VERSION "dbc-export 1 2025.20.8"

NS_ :

BS_:

BU_: APP BMS CC CMP CMPD CP DAS DI DIF DIR EPBL EPBR EVSE FC GTW HCML HCMR HVP ICR PCS PM PMF PMR PTC SCCM SCM SCS SDCR TAS UMC VC VCFRONT VCLEFT VCRIGHT VCSEC

BO_ 1291 TAS_alertLog: 8 TAS
 SG_ TAS_alertID M : 0|9@1+ (1,0) [0|511] "" Vector__XXX
 SG_ TAS_alertState : 15|1@1+ (1,0) [0|1] "" Vector__XXX
 SG_ TAS_a001_InternalWatchdog m1 : 16|1@1+ (1,0) [0|1] "" Vector__XXX
 SG_ TAS_a002_CPUUndervoltage m2 : 16|1@1+ (1,0) [0|1] "" Vector__XXX
 SG_ TAS_a002_PowerOnReset m2 : 17|1@1+ (1,0) [0|1] "" Vector__XXX
 SG_ TAS_a003_AssertID m3 : 16|16@1+ (1,0) [0|65535] "" Vector__XXX
 SG_ TAS_a003_LineNumber m3 : 32|16@1+ (1,0) [0|65535] "" Vector__XXX
 SG_ TAS_a003_Data m3 : 48|16@1+ (1,0) [0|65535] "" Vector__XXX
 SG_ TAS_a012_ClockError m12 : 16|1@1+ (1,0) [0|1] "" Vector__XXX
 SG_ TAS_a012_FlashError m12 : 17|1@1+ (1,0) [0|1] "" Vector__XXX
 SG_ TAS_a012_SoftwareReset m12 : 18|1@1+ (1,0) [0|1] "" Vector__XXX
 SG_ TAS_a012_CheckstopReset m12 : 19|1@1+ (1,0) [0|1] "" Vector__XXX
 SG_ TAS_a012_DebugReset m12 : 20|1@1+ (1,0) [0|1] "" Vector__XXX
 SG_ TAS_a012_ExternalReset m12 : 21|1@1+ (1,0) [0|1] "" Vector__XXX
 SG_ TAS_a021_Task1msLate m21 : 16|1@1+ (1,0) [0|1] "" Vector__XXX
 SG_ TAS_a021_Task1msStarved m21 : 17|1@1+ (1,0) [0|1] "" Vector__XXX
 SG_ TAS_a021_Task1msMissed m21 : 18|1@1+ (1,0) [0|1] "" Vector__XXX
 SG_ TAS_a021_Task10msLate m21 : 19|1@1+ (1,0) [0|1] "" Vector__XXX
 SG_ TAS_a021_Task10msStarved m21 : 20|1@1+ (1,0) [0|1] "" Vector__XXX
 SG_ TAS_a021_Task10msMissed m21 : 21|1@1+ (1,0) [0|1] "" Vector__XXX
 SG_ TAS_a021_Task100msLate m21 : 22|1@1+ (1,0) [0|1] "" Vector__XXX
 SG_ TAS_a021_Task100msStarved m21 : 23|1@1+ (1,0) [0|1] "" Vector__XXX
 SG_ TAS_a021_Task100msMissed m21 : 24|1@1+ (1,0) [0|1] "" Vector__XXX
 SG_ TAS_a021_Task1000msLate m21 : 25|1@1+ (1,0) [0|1] "" Vector__XXX
 SG_ TAS_a021_Task1000msStarved m21 : 26|1@1+ (1,0) [0|1] "" Vector__XXX
 SG_ TAS_a021_Task1000msMissed m21 : 27|1@1+ (1,0) [0|1] "" Vector__XXX
 SG_ TAS_a022_TaskInitErrorCount m22 : 16|8@1+ (1,0) [0|255] "" Vector__XXX
 SG_ TAS_a022_TaskInitError0 m22 : 24|8@1+ (1,0) [0|255] "" Vector__XXX
 SG_ TAS_a022_TaskInitError1 m22 : 32|8@1+ (1,0) [0|255] "" Vector__XXX
 SG_ TAS_a022_TaskInitError2 m22 : 40|8@1+ (1,0) [0|255] "" Vector__XXX
 SG_ TAS_a022_TaskInitError3 m22 : 48|8@1+ (1,0) [0|255] "" Vector__XXX
 SG_ TAS_a022_TaskInitError4 m22 : 56|8@1+ (1,0) [0|255] "" Vector__XXX
 SG_ TAS_a025_vehicleLockAtCrash m25 : 16|1@1+ (1,0) [0|1] "" Vector__XXX
 SG_ TAS_a025_CANCrashIsActive m25 : 17|1@1+ (1,0) [0|1] "" Vector__XXX
 SG_ TAS_a025_appCrashIsActive m25 : 18|1@1+ (1,0) [0|1] "" Vector__XXX
 SG_ TAS_a025_lastCrashEvent m25 : 24|32@1+ (1,0) [0|4294967295] "" Vector__XXX
 SG_ TAS_a030_PWMdutyCycleFL m30 : 16|16@1+ (0.0025,0) [0|163.8375] "%" Vector__XXX
 SG_ TAS_a030_PWMfrequencyFL m30 : 32|16@1+ (0.025,0) [0|1638.375] "Hz" Vector__XXX
 SG_ TAS_a030_PWMfaultFL m30 : 48|4@1+ (1,0) [0|15] "" Vector__XXX
 SG_ TAS_a031_PWMdutyCycleFR m31 : 16|16@1+ (0.0025,0) [0|163.8375] "%" Vector__XXX
 SG_ TAS_a031_PWMfrequencyFR m31 : 32|16@1+ (0.025,0) [0|1638.375] "Hz" Vector__XXX
 SG_ TAS_a031_PWMfaultFR m31 : 48|4@1+ (1,0) [0|15] "" Vector__XXX
 SG_ TAS_a032_PWMdutyCycleRL m32 : 16|16@1+ (0.0025,0) [0|163.8375] "%" Vector__XXX
 SG_ TAS_a032_PWMfrequencyRL m32 : 32|16@1+ (0.025,0) [0|1638.375] "Hz" Vector__XXX
 SG_ TAS_a032_PWMfaultRL m32 : 48|4@1+ (1,0) [0|15] "" Vector__XXX
 SG_ TAS_a033_PWMdutyCycleRR m33 : 16|16@1+ (0.0025,0) [0|163.8375] "%" Vector__XXX
 SG_ TAS_a033_PWMfrequencyRR m33 : 32|16@1+ (0.025,0) [0|1638.375] "Hz" Vector__XXX
 SG_ TAS_a033_PWMfaultRR m33 : 48|4@1+ (1,0) [0|15] "" Vector__XXX
 SG_ TAS_a034_PWMdutyCycleFL m34 : 16|16@1+ (0.0025,0) [0|163.8375] "%" Vector__XXX
 SG_ TAS_a034_PWMfrequencyFL m34 : 32|16@1+ (0.025,0) [0|1638.375] "Hz" Vector__XXX
 SG_ TAS_a034_PWMfaultFL m34 : 48|4@1+ (1,0) [0|15] "" Vector__XXX
 SG_ TAS_a035_PWMdutyCycleFR m35 : 16|16@1+ (0.0025,0) [0|163.8375] "%" Vector__XXX
 SG_ TAS_a035_PWMfrequencyFR m35 : 32|16@1+ (0.025,0) [0|1638.375] "Hz" Vector__XXX
 SG_ TAS_a035_PWMfaultFR m35 : 48|4@1+ (1,0) [0|15] "" Vector__XXX
 SG_ TAS_a036_PWMdutyCycleRL m36 : 16|16@1+ (0.0025,0) [0|163.8375] "%" Vector__XXX
 SG_ TAS_a036_PWMfrequencyRL m36 : 32|16@1+ (0.025,0) [0|1638.375] "Hz" Vector__XXX
 SG_ TAS_a036_PWMfaultRL m36 : 48|4@1+ (1,0) [0|15] "" Vector__XXX
 SG_ TAS_a037_PWMdutyCycleRR m37 : 16|16@1+ (0.0025,0) [0|163.8375] "%" Vector__XXX
 SG_ TAS_a037_PWMfrequencyRR m37 : 32|16@1+ (0.025,0) [0|1638.375] "Hz" Vector__XXX
 SG_ TAS_a037_PWMfaultRR m37 : 48|4@1+ (1,0) [0|15] "" Vector__XXX
 SG_ TAS_a038_PWMdutyCycleFL m38 : 16|16@1+ (0.0025,0) [0|163.8375] "%" Vector__XXX
 SG_ TAS_a038_PWMfrequencyFL m38 : 32|16@1+ (0.025,0) [0|1638.375] "Hz" Vector__XXX
 SG_ TAS_a038_PWMfaultFL m38 : 48|4@1+ (1,0) [0|15] "" Vector__XXX
 SG_ TAS_a039_PWMdutyCycleFR m39 : 16|16@1+ (0.0025,0) [0|163.8375] "%" Vector__XXX
 SG_ TAS_a039_PWMfrequencyFR m39 : 32|16@1+ (0.025,0) [0|1638.375] "Hz" Vector__XXX
 SG_ TAS_a039_PWMfaultFR m39 : 48|4@1+ (1,0) [0|15] "" Vector__XXX
 SG_ TAS_a040_PWMdutyCycleRL m40 : 16|16@1+ (0.0025,0) [0|163.8375] "%" Vector__XXX
 SG_ TAS_a040_PWMfrequencyRL m40 : 32|16@1+ (0.025,0) [0|1638.375] "Hz" Vector__XXX
 SG_ TAS_a040_PWMfaultRL m40 : 48|4@1+ (1,0) [0|15] "" Vector__XXX
 SG_ TAS_a041_PWMdutyCycleRR m41 : 16|16@1+ (0.0025,0) [0|163.8375] "%" Vector__XXX
 SG_ TAS_a041_PWMfrequencyRR m41 : 32|16@1+ (0.025,0) [0|1638.375] "Hz" Vector__XXX
 SG_ TAS_a041_PWMfaultRR m41 : 48|4@1+ (1,0) [0|15] "" Vector__XXX
 SG_ TAS_a070_voltage12V m70 : 16|16@1+ (0.001,0) [0|65.535] "V" Vector__XXX
 SG_ TAS_a071_voltage12V m71 : 16|16@1+ (0.001,0) [0|65.535] "V" Vector__XXX
 SG_ TAS_a072_voltage5VOnBoard m72 : 16|16@1+ (0.001,0) [0|65.535] "V" Vector__XXX
 SG_ TAS_a073_voltage5VOnBoard m73 : 16|16@1+ (0.001,0) [0|65.535] "V" Vector__XXX
 SG_ TAS_a074_voltage5VOffBoard m74 : 16|16@1+ (0.001,0) [0|65.535] "V" Vector__XXX
 SG_ TAS_a075_voltage5VOffBoard m75 : 16|16@1+ (0.001,0) [0|65.535] "V" Vector__XXX
 SG_ TAS_a076_voltage5VOffBoard m76 : 16|16@1+ (0.001,0) [0|65.535] "V" Vector__XXX
 SG_ TAS_a077_sensorVoltage m77 : 16|16@1+ (0.001,0) [0|65.535] "V" Vector__XXX
 SG_ TAS_a077_sensorRefVoltage m77 : 32|16@1+ (0.001,0) [0|65.535] "V" Vector__XXX
 SG_ TAS_a078_sensorVoltage m78 : 16|16@1+ (0.001,0) [0|65.535] "V" Vector__XXX
 SG_ TAS_a078_sensorRefVoltage m78 : 32|16@1+ (0.001,0) [0|65.535] "V" Vector__XXX
 SG_ TAS_a080_voltage5VHeight m80 : 16|16@1+ (0.001,0) [0|65.535] "V" Vector__XXX
 SG_ TAS_a081_voltage5VHeight m81 : 16|16@1+ (0.001,0) [0|65.535] "V" Vector__XXX
 SG_ TAS_a082_voltage5VHeight m82 : 16|16@1+ (0.001,0) [0|65.535] "V" Vector__XXX
 SG_ TAS_a083_voltage5VAnalog m83 : 16|16@1+ (0.001,0) [0|65.535] "V" Vector__XXX
 SG_ TAS_a084_voltage5VAnalog m84 : 16|16@1+ (0.001,0) [0|65.535] "V" Vector__XXX
 SG_ TAS_a085_voltage5VAnalog m85 : 16|16@1+ (0.001,0) [0|65.535] "V" Vector__XXX
 SG_ TAS_a086_voltage12VSwitched m86 : 16|16@1+ (0.001,0) [0|65.535] "V" Vector__XXX
 SG_ TAS_a087_voltage12VSwitched m87 : 16|16@1+ (0.001,0) [0|65.535] "V" Vector__XXX
 SG_ TAS_a093_readError m93 : 16|1@1+ (1,0) [0|1] "" Vector__XXX
 SG_ TAS_a093_IVOR2Exception m93 : 17|1@1+ (1,0) [0|1] "" Vector__XXX
 SG_ TAS_a098_VCFRONT_LVPowerState_MI m98 : 16|1@1+ (1,0) [0|1] "" Vector__XXX
 SG_ TAS_a098_VCFRONT_sensors_MIA m98 : 17|1@1+ (1,0) [0|1] "" Vector__XXX
 SG_ TAS_a098_VCFRONT_status_MIA m98 : 18|1@1+ (1,0) [0|1] "" Vector__XXX
 SG_ TAS_a098_VCFRONT_systemStatus_MI m98 : 19|1@1+ (1,0) [0|1] "" Vector__XXX
 SG_ TAS_a098_VCFRONT_vehNm_MIA m98 : 20|1@1+ (1,0) [0|1] "" Vector__XXX
 SG_ TAS_a099_UI_chassisControl_MIA m99 : 16|1@1+ (1,0) [0|1] "" Vector__XXX
 SG_ TAS_a099_UI_driverAssistMapData_ m99 : 17|1@1+ (1,0) [0|1] "" Vector__XXX
 SG_ TAS_a099_UI_suspensionControl_MI m99 : 18|1@1+ (1,0) [0|1] "" Vector__XXX
 SG_ TAS_a099_UI_vehicleModes_MIA m99 : 19|1@1+ (1,0) [0|1] "" Vector__XXX
 SG_ TAS_a100_RCM_inertial1_MIA m100 : 16|1@1+ (1,0) [0|1] "" Vector__XXX
 SG_ TAS_a100_RCM_inertial2_MIA m100 : 17|1@1+ (1,0) [0|1] "" Vector__XXX
 SG_ TAS_a101_ESP_brakeTorque_MIA m101 : 16|1@1+ (1,0) [0|1] "" Vector__XXX
 SG_ TAS_a101_ESP_status_MIA m101 : 17|1@1+ (1,0) [0|1] "" Vector__XXX
 SG_ TAS_a101_ESP_wheelRotation_MIA m101 : 18|1@1+ (1,0) [0|1] "" Vector__XXX
 SG_ TAS_a102_DI_chassisControl_MIA m102 : 16|1@1+ (1,0) [0|1] "" Vector__XXX
 SG_ TAS_a102_DI_locStatus_MIA m102 : 17|1@1+ (1,0) [0|1] "" Vector__XXX
 SG_ TAS_a102_DI_speed_MIA m102 : 18|1@1+ (1,0) [0|1] "" Vector__XXX
 SG_ TAS_a102_DI_systemStatus_MIA m102 : 19|1@1+ (1,0) [0|1] "" Vector__XXX
 SG_ TAS_a102_DI_vehicleEstimates_MIA m102 : 20|1@1+ (1,0) [0|1] "" Vector__XXX
 SG_ TAS_a102_DIF_torque_MIA m102 : 21|1@1+ (1,0) [0|1] "" Vector__XXX
 SG_ TAS_a102_DIR_torque_MIA m102 : 22|1@1+ (1,0) [0|1] "" Vector__XXX
 SG_ TAS_a103_GTW_carConfig_MIA m103 : 16|1@1+ (1,0) [0|1] "" Vector__XXX
 SG_ TAS_a103_GTW_time_MIA m103 : 17|1@1+ (1,0) [0|1] "" Vector__XXX
 SG_ TAS_a103_GTW_vehNm_MIA m103 : 18|1@1+ (1,0) [0|1] "" Vector__XXX
 SG_ TAS_a103_GTW_vin_MIA m103 : 19|1@1+ (1,0) [0|1] "" Vector__XXX
 SG_ TAS_a164_detectedDamperSolenoid m164 : 16|3@1+ (1,0) [0|7] "" Vector__XXX
 SG_ TAS_a164_expectedDamperSolenoid m164 : 19|3@1+ (1,0) [0|7] "" Vector__XXX
 SG_ TAS_a165_damperValveFault m165 : 16|4@1+ (1,0) [0|15] "" Vector__XXX
 SG_ TAS_a166_damperValveFault m166 : 16|4@1+ (1,0) [0|15] "" Vector__XXX
 SG_ TAS_a167_damperValveFault m167 : 16|4@1+ (1,0) [0|15] "" Vector__XXX
 SG_ TAS_a168_damperValveFault m168 : 16|4@1+ (1,0) [0|15] "" Vector__XXX
 SG_ TAS_a169_damperValveFault m169 : 16|4@1+ (1,0) [0|15] "" Vector__XXX
 SG_ TAS_a170_damperValveFault m170 : 16|4@1+ (1,0) [0|15] "" Vector__XXX
 SG_ TAS_a171_damperValveFault m171 : 16|4@1+ (1,0) [0|15] "" Vector__XXX
 SG_ TAS_a172_damperValveFault m172 : 16|4@1+ (1,0) [0|15] "" Vector__XXX
 SG_ TAS_a173_heightDelta_mm m173 : 16|8@1+ (1,-128) [-128|127] "mm" Vector__XXX
 SG_ TAS_a174_heightDelta_mm m174 : 16|8@1+ (1,-128) [-128|127] "mm" Vector__XXX
 SG_ TAS_a175_heightDelta_mm m175 : 16|8@1+ (1,-128) [-128|127] "mm" Vector__XXX
 SG_ TAS_a176_heightDelta_mm m176 : 16|8@1+ (1,-128) [-128|127] "mm" Vector__XXX
 SG_ TAS_a190_a2bFaultType m190 : 16|4@1+ (1,0) [0|15] "" Vector__XXX
 SG_ TAS_a190_a2bInterruptType m190 : 24|8@1+ (1,0) [0|255] "" Vector__XXX
 SG_ TAS_a190_a2bFaultSource m190 : 32|2@1+ (1,0) [0|3] "" Vector__XXX
 SG_ TAS_a191_a2bFaultType m191 : 16|4@1+ (1,0) [0|15] "" Vector__XXX
 SG_ TAS_a191_a2bInterruptType m191 : 24|8@1+ (1,0) [0|255] "" Vector__XXX
 SG_ TAS_a191_a2bFaultSource m191 : 32|2@1+ (1,0) [0|3] "" Vector__XXX
 SG_ TAS_a192_rideHeightVelDspFL m192 : 16|5@1- (0.2,0) [-3.2|3] "mps" Vector__XXX
 SG_ TAS_a192_rideHeightVelDspFR m192 : 24|5@1- (0.2,0) [-3.2|3] "mps" Vector__XXX
 SG_ TAS_a192_rideHeightVelDspRL m192 : 32|5@1- (0.2,0) [-3.2|3] "mps" Vector__XXX
 SG_ TAS_a192_rideHeightVelDspRR m192 : 37|5@1- (0.2,0) [-3.2|3] "mps" Vector__XXX
 SG_ TAS_a192_rideHeightVelObserverFL m192 : 42|5@1- (0.2,0) [-3.2|3] "mps" Vector__XXX
 SG_ TAS_a192_rideHeightVelObserverFR m192 : 47|5@1- (0.2,0) [-3.2|3] "mps" Vector__XXX
 SG_ TAS_a192_rideHeightVelObserverRL m192 : 52|5@1- (0.2,0) [-3.2|3] "mps" Vector__XXX
 SG_ TAS_a192_rideHeightVelObserverRR m192 : 57|5@1- (0.2,0) [-3.2|3] "mps" Vector__XXX
 SG_ TAS_a192_alertVersion m192 : 62|2@1+ (1,0) [0|3] "" Vector__XXX
 SG_ TAS_a193_EPAS3P_sysStatus_MIA m193 : 16|1@1+ (1,0) [0|1] "" Vector__XXX
 SG_ TAS_a210_heightSensorDeltaFL m210 : 16|8@1+ (1,-128) [-128|127] "mm" Vector__XXX
 SG_ TAS_a210_heightSensorDeltaFR m210 : 24|8@1+ (1,-128) [-128|127] "mm" Vector__XXX
 SG_ TAS_a210_heightSensorDeltaRL m210 : 32|8@1+ (1,-128) [-128|127] "mm" Vector__XXX
 SG_ TAS_a210_heightSensorDeltaRR m210 : 40|8@1+ (1,-128) [-128|127] "mm" Vector__XXX
 SG_ TAS_a220_galleryPressure m220 : 16|8@1+ (0.1,0) [0|25.5] "bara" Vector__XXX
 SG_ TAS_a220_timeInExhaust m220 : 24|32@1+ (1,0) [0|4294967295] "ms" Vector__XXX
 SG_ TAS_a221_galleryPressureDelta m221 : 16|8@1+ (0.1,0) [0|25.5] "bar" Vector__XXX
 SG_ TAS_a221_timeInIdle m221 : 24|32@1+ (1,0) [0|4294967295] "ms" Vector__XXX
 SG_ TAS_a222_galleryPressureDelta m222 : 16|8@1+ (0.1,0) [0|25.5] "bar" Vector__XXX
 SG_ TAS_a223_galleryPressure m223 : 16|8@1+ (0.1,0) [0|25.5] "bara" Vector__XXX
 SG_ TAS_a223_valveOnFL m223 : 24|1@1+ (1,0) [0|1] "" Vector__XXX
 SG_ TAS_a223_valveOnFR m223 : 25|1@1+ (1,0) [0|1] "" Vector__XXX
 SG_ TAS_a223_valveOnRL m223 : 26|1@1+ (1,0) [0|1] "" Vector__XXX
 SG_ TAS_a223_valveOnRR m223 : 27|1@1+ (1,0) [0|1] "" Vector__XXX
 SG_ TAS_a223_valveOnReservoir m223 : 28|1@1+ (1,0) [0|1] "" Vector__XXX
 SG_ TAS_a224_galleryPressure m224 : 16|8@1+ (0.1,0) [0|25.5] "bara" Vector__XXX
 SG_ TAS_a224_valveOnFL m224 : 24|1@1+ (1,0) [0|1] "" Vector__XXX
 SG_ TAS_a224_valveOnFR m224 : 25|1@1+ (1,0) [0|1] "" Vector__XXX
 SG_ TAS_a224_valveOnRL m224 : 26|1@1+ (1,0) [0|1] "" Vector__XXX
 SG_ TAS_a224_valveOnRR m224 : 27|1@1+ (1,0) [0|1] "" Vector__XXX
 SG_ TAS_a224_valveOnReservoir m224 : 28|1@1+ (1,0) [0|1] "" Vector__XXX
 SG_ TAS_a225_galleryPressure m225 : 16|8@1+ (0.1,0) [0|25.5] "bara" Vector__XXX
 SG_ TAS_a226_PWMdutyCycleFL m226 : 16|16@1+ (0.0025,0) [0|163.8375] "%" Vector__XXX
 SG_ TAS_a226_PWMfrequencyFL m226 : 32|16@1+ (0.025,0) [0|1638.375] "Hz" Vector__XXX
 SG_ TAS_a226_PWMfaultFL m226 : 48|4@1+ (1,0) [0|15] "" Vector__XXX
 SG_ TAS_a227_PWMdutyCycleFR m227 : 16|16@1+ (0.0025,0) [0|163.8375] "%" Vector__XXX
 SG_ TAS_a227_PWMfrequencyFR m227 : 32|16@1+ (0.025,0) [0|1638.375] "Hz" Vector__XXX
 SG_ TAS_a227_PWMfaultFR m227 : 48|4@1+ (1,0) [0|15] "" Vector__XXX
 SG_ TAS_a228_PWMdutyCycleRL m228 : 16|16@1+ (0.0025,0) [0|163.8375] "%" Vector__XXX
 SG_ TAS_a228_PWMfrequencyRL m228 : 32|16@1+ (0.025,0) [0|1638.375] "Hz" Vector__XXX
 SG_ TAS_a228_PWMfaultRL m228 : 48|4@1+ (1,0) [0|15] "" Vector__XXX
 SG_ TAS_a229_PWMdutyCycleRR m229 : 16|16@1+ (0.0025,0) [0|163.8375] "%" Vector__XXX
 SG_ TAS_a229_PWMfrequencyRR m229 : 32|16@1+ (0.025,0) [0|1638.375] "Hz" Vector__XXX
 SG_ TAS_a229_PWMfaultRR m229 : 48|4@1+ (1,0) [0|15] "" Vector__XXX
 SG_ TAS_a232_detectedSuspensionType m232 : 16|3@1+ (1,0) [0|7] "" Vector__XXX
 SG_ TAS_a232_expectedSuspensionType m232 : 19|3@1+ (1,0) [0|7] "" Vector__XXX
 SG_ TAS_a234_detectedDamperHydraulic m234 : 16|2@1+ (1,0) [0|3] "" Vector__XXX
 SG_ TAS_a234_expectedDamperHydraulic m234 : 18|2@1+ (1,0) [0|3] "" Vector__XXX
 SG_ TAS_a240_highAdjustCountRatio m240 : 16|1@1+ (1,0) [0|1] "" Vector__XXX
 SG_ TAS_a240_highAdjustTimeRatio m240 : 17|1@1+ (1,0) [0|1] "" Vector__XXX
 SG_ TAS_a240_highCrossPressure m240 : 18|1@1+ (1,0) [0|1] "" Vector__XXX
 SG_ TAS_a240_highCompExhTimeRatio m240 : 19|1@1+ (1,0) [0|1] "" Vector__XXX
 SG_ TAS_a240_adjustCountRatioSpring m240 : 20|3@1+ (1,0) [0|7] "" Vector__XXX
 SG_ TAS_a240_adjustCountRatio m240 : 24|8@1+ (0.02952756,0) [0|7.50000024] "InflateCount/DeflateCount" Vector__XXX
 SG_ TAS_a240_adjustTimeRatioSpring m240 : 32|3@1+ (1,0) [0|7] "" Vector__XXX
 SG_ TAS_a240_adjustTimeRatio m240 : 40|8@1+ (0.02952756,0) [0|7.50000024] "InflateTime/DeflateTime" Vector__XXX
 SG_ TAS_a240_compExhTimeRatio m240 : 48|8@1+ (0.0294117648154,0) [0|7.50000002793] "CompressorTime/ExhaustTime" Vector__XXX
 SG_ TAS_a240_crossPressure m240 : 56|8@1- (0.1,0) [-12.8|12.7] "bara/bara" Vector__XXX
 SG_ TAS_a285_twistLevel m285 : 16|8@1+ (1,-128) [-128|127] "mm" Vector__XXX
 SG_ TAS_a290_twistLevel m290 : 16|8@1+ (1,-128) [-128|127] "mm" Vector__XXX
 SG_ TAS_a291_frontAxleHeight m291 : 16|8@1+ (1,-128) [-128|127] "mm" Vector__XXX
 SG_ TAS_a292_rearAxleHeight m292 : 16|8@1+ (1,-128) [-128|127] "mm" Vector__XXX
 SG_ TAS_a293_frontAxleHeight m293 : 16|8@1+ (1,-128) [-128|127] "mm" Vector__XXX
 SG_ TAS_a294_rearAxleHeight m294 : 16|8@1+ (1,-128) [-128|127] "mm" Vector__XXX
 SG_ TAS_a295_targetHeight m295 : 16|8@1+ (1,-128) [-128|127] "mm" Vector__XXX
 SG_ TAS_a296_detectedChassisType m296 : 16|3@1+ (1,0) [0|7] "" Vector__XXX
 SG_ TAS_a296_expectedChassisType m296 : 19|3@1+ (1,0) [0|7] "" Vector__XXX
 SG_ TAS_a319_detectedDrivetrainType m319 : 16|2@1+ (1,0) [0|3] "" Vector__XXX
 SG_ TAS_a319_expectedDrivetrainType m319 : 18|2@1+ (1,0) [0|3] "" Vector__XXX

BO_ 852 TAS_alertMatrix: 8 TAS
 SG_ TAS_matrixIndex M : 0|4@1+ (1,0) [0|15] "" Vector__XXX
 SG_ TAS_a001_WatchdogReset m0 : 4|1@1+ (1,0) [0|1] "" Vector__XXX
 SG_ TAS_a002_PowerLossReset m0 : 5|1@1+ (1,0) [0|1] "" Vector__XXX
 SG_ TAS_a003_SWAssertion m0 : 6|1@1+ (1,0) [0|1] "" Vector__XXX
 SG_ TAS_a012_CPUReset m0 : 15|1@1+ (1,0) [0|1] "" Vector__XXX
 SG_ TAS_a015_NVMMError m0 : 18|1@1+ (1,0) [0|1] "" Vector__XXX
 SG_ TAS_a016_NVMMRecordError m0 : 19|1@1+ (1,0) [0|1] "" Vector__XXX
 SG_ TAS_a021_TaskSchedulerError m0 : 24|1@1+ (1,0) [0|1] "" Vector__XXX
 SG_ TAS_a022_TaskInitError m0 : 25|1@1+ (1,0) [0|1] "" Vector__XXX
 SG_ TAS_a023_rtosResetRequested m0 : 26|1@1+ (1,0) [0|1] "" Vector__XXX
 SG_ TAS_a024_prefetchAbort m0 : 27|1@1+ (1,0) [0|1] "" Vector__XXX
 SG_ TAS_a025_CrashEvent m0 : 28|1@1+ (1,0) [0|1] "" Vector__XXX
 SG_ TAS_a030_PWMerrorFL m0 : 33|1@1+ (1,0) [0|1] "" Vector__XXX
 SG_ TAS_a031_PWMerrorFR m0 : 34|1@1+ (1,0) [0|1] "" Vector__XXX
 SG_ TAS_a032_PWMerrorRL m0 : 35|1@1+ (1,0) [0|1] "" Vector__XXX
 SG_ TAS_a033_PWMerrorRR m0 : 36|1@1+ (1,0) [0|1] "" Vector__XXX
 SG_ TAS_a034_PWMshortFL m0 : 37|1@1+ (1,0) [0|1] "" Vector__XXX
 SG_ TAS_a035_PWMshortFR m0 : 38|1@1+ (1,0) [0|1] "" Vector__XXX
 SG_ TAS_a036_PWMshortRL m0 : 39|1@1+ (1,0) [0|1] "" Vector__XXX
 SG_ TAS_a037_PWMshortRR m0 : 40|1@1+ (1,0) [0|1] "" Vector__XXX
 SG_ TAS_a038_PWMopenFL m0 : 41|1@1+ (1,0) [0|1] "" Vector__XXX
 SG_ TAS_a039_PWMopenFR m0 : 42|1@1+ (1,0) [0|1] "" Vector__XXX
 SG_ TAS_a040_PWMopenRL m0 : 43|1@1+ (1,0) [0|1] "" Vector__XXX
 SG_ TAS_a041_PWMopenRR m0 : 44|1@1+ (1,0) [0|1] "" Vector__XXX
 SG_ TAS_a043_Task1msError m0 : 46|1@1+ (1,0) [0|1] "" Vector__XXX
 SG_ TAS_a044_Task10msError m0 : 47|1@1+ (1,0) [0|1] "" Vector__XXX
 SG_ TAS_a045_Task100msError m0 : 48|1@1+ (1,0) [0|1] "" Vector__XXX
 SG_ TAS_a046_Task1000msError m0 : 49|1@1+ (1,0) [0|1] "" Vector__XXX
 SG_ TAS_a061_XCPConnected m1 : 4|1@1+ (1,0) [0|1] "" Vector__XXX
 SG_ TAS_a062_XCPWasConnected m1 : 5|1@1+ (1,0) [0|1] "" Vector__XXX
 SG_ TAS_a063_abortFault m1 : 6|1@1+ (1,0) [0|1] "" Vector__XXX
 SG_ TAS_a064_abortFaultExt m1 : 7|1@1+ (1,0) [0|1] "" Vector__XXX
 SG_ TAS_a065_ahbWriteFault m1 : 8|1@1+ (1,0) [0|1] "" Vector__XXX
 SG_ TAS_a066_undefinedInstructionAbo m1 : 9|1@1+ (1,0) [0|1] "" Vector__XXX
 SG_ TAS_a067_reservedHandlerAbort m1 : 10|1@1+ (1,0) [0|1] "" Vector__XXX
 SG_ TAS_a070_underVoltage12V m1 : 13|1@1+ (1,0) [0|1] "" Vector__XXX
 SG_ TAS_a071_overVoltage12V m1 : 14|1@1+ (1,0) [0|1] "" Vector__XXX
 SG_ TAS_a072_shortCircuit5VOnBoard m1 : 15|1@1+ (1,0) [0|1] "" Vector__XXX
 SG_ TAS_a073_underVoltage5VOnBoard m1 : 16|1@1+ (1,0) [0|1] "" Vector__XXX
 SG_ TAS_a074_shortCircuit5VOffBoard m1 : 17|1@1+ (1,0) [0|1] "" Vector__XXX
 SG_ TAS_a075_underVoltage5VOffBoard m1 : 18|1@1+ (1,0) [0|1] "" Vector__XXX
 SG_ TAS_a076_overVoltage5VOffBoard m1 : 19|1@1+ (1,0) [0|1] "" Vector__XXX
 SG_ TAS_a077_pressureSigVTooLow m1 : 20|1@1+ (1,0) [0|1] "" Vector__XXX
 SG_ TAS_a078_pressureSigVTooHigh m1 : 21|1@1+ (1,0) [0|1] "" Vector__XXX
 SG_ TAS_a080_shortCircuit5VHeight m1 : 23|1@1+ (1,0) [0|1] "" Vector__XXX
 SG_ TAS_a081_underVoltage5VHeight m1 : 24|1@1+ (1,0) [0|1] "" Vector__XXX
 SG_ TAS_a082_overVoltage5VHeight m1 : 25|1@1+ (1,0) [0|1] "" Vector__XXX
 SG_ TAS_a083_shortCircuit5VAnalog m1 : 26|1@1+ (1,0) [0|1] "" Vector__XXX
 SG_ TAS_a084_underVoltage5VAnalog m1 : 27|1@1+ (1,0) [0|1] "" Vector__XXX
 SG_ TAS_a085_overVoltage5VAnalog m1 : 28|1@1+ (1,0) [0|1] "" Vector__XXX
 SG_ TAS_a086_underVoltage12VSwtchd m1 : 29|1@1+ (1,0) [0|1] "" Vector__XXX
 SG_ TAS_a087_overVoltage12VSwtchd m1 : 30|1@1+ (1,0) [0|1] "" Vector__XXX
 SG_ TAS_a093_OTPError m1 : 36|1@1+ (1,0) [0|1] "" Vector__XXX
 SG_ TAS_a098_VCFRONT_MIA m1 : 41|1@1+ (1,0) [0|1] "" Vector__XXX
 SG_ TAS_a099_UI_MIA m1 : 42|1@1+ (1,0) [0|1] "" Vector__XXX
 SG_ TAS_a100_RCM_MIA m1 : 43|1@1+ (1,0) [0|1] "" Vector__XXX
 SG_ TAS_a101_ESP_MIA m1 : 44|1@1+ (1,0) [0|1] "" Vector__XXX
 SG_ TAS_a102_DI_MIA m1 : 45|1@1+ (1,0) [0|1] "" Vector__XXX
 SG_ TAS_a103_GTW_MIA m1 : 46|1@1+ (1,0) [0|1] "" Vector__XXX
 SG_ TAS_a105_ECUDebugMode m1 : 48|1@1+ (1,0) [0|1] "" Vector__XXX
 SG_ TAS_a106_HighCPULoad m1 : 49|1@1+ (1,0) [0|1] "" Vector__XXX
 SG_ TAS_a107_HighStackUsage m1 : 50|1@1+ (1,0) [0|1] "" Vector__XXX
 SG_ TAS_a150_accelAvgImplausible_FL_ m2 : 33|1@1+ (1,0) [0|1] "" Vector__XXX
 SG_ TAS_a151_accelAvgImplausible_FL_ m2 : 34|1@1+ (1,0) [0|1] "" Vector__XXX
 SG_ TAS_a152_accelAvgImplausible_FL_ m2 : 35|1@1+ (1,0) [0|1] "" Vector__XXX
 SG_ TAS_a153_accelAvgImplausible_FR_ m2 : 36|1@1+ (1,0) [0|1] "" Vector__XXX
 SG_ TAS_a154_accelAvgImplausible_FR_ m2 : 37|1@1+ (1,0) [0|1] "" Vector__XXX
 SG_ TAS_a155_accelAvgImplausible_FR_ m2 : 38|1@1+ (1,0) [0|1] "" Vector__XXX
 SG_ TAS_a156_accelAvgImplausible_RL_ m2 : 39|1@1+ (1,0) [0|1] "" Vector__XXX
 SG_ TAS_a157_accelAvgImplausible_RL_ m2 : 40|1@1+ (1,0) [0|1] "" Vector__XXX
 SG_ TAS_a158_accelAvgImplausible_RL_ m2 : 41|1@1+ (1,0) [0|1] "" Vector__XXX
 SG_ TAS_a159_accelAvgImplausible_RR_ m2 : 42|1@1+ (1,0) [0|1] "" Vector__XXX
 SG_ TAS_a160_accelAvgImplausible_RR_ m2 : 43|1@1+ (1,0) [0|1] "" Vector__XXX
 SG_ TAS_a161_accelAvgImplausible_RR_ m2 : 44|1@1+ (1,0) [0|1] "" Vector__XXX
 SG_ TAS_a164_damperSolenoidMismatch m2 : 47|1@1+ (1,0) [0|1] "" Vector__XXX
 SG_ TAS_a165_damperValveCompFL m2 : 48|1@1+ (1,0) [0|1] "" Vector__XXX
 SG_ TAS_a166_damperValveRbndFL m2 : 49|1@1+ (1,0) [0|1] "" Vector__XXX
 SG_ TAS_a167_damperValveCompFR m2 : 50|1@1+ (1,0) [0|1] "" Vector__XXX
 SG_ TAS_a168_damperValveRbndFR m2 : 51|1@1+ (1,0) [0|1] "" Vector__XXX
 SG_ TAS_a169_damperValveCompRL m2 : 52|1@1+ (1,0) [0|1] "" Vector__XXX
 SG_ TAS_a170_damperValveRbndRL m2 : 53|1@1+ (1,0) [0|1] "" Vector__XXX
 SG_ TAS_a171_damperValveCompRR m2 : 54|1@1+ (1,0) [0|1] "" Vector__XXX
 SG_ TAS_a172_damperValveRbndRR m2 : 55|1@1+ (1,0) [0|1] "" Vector__XXX
 SG_ TAS_a173_staticLeakDetectFL m2 : 56|1@1+ (1,0) [0|1] "" Vector__XXX
 SG_ TAS_a174_staticLeakDetectFR m2 : 57|1@1+ (1,0) [0|1] "" Vector__XXX
 SG_ TAS_a175_staticLeakDetectRL m2 : 58|1@1+ (1,0) [0|1] "" Vector__XXX
 SG_ TAS_a176_staticLeakDetectRR m2 : 59|1@1+ (1,0) [0|1] "" Vector__XXX
 SG_ TAS_a190_a2bFrontAxleFault m3 : 13|1@1+ (1,0) [0|1] "" Vector__XXX
 SG_ TAS_a191_a2bRearAxleFault m3 : 14|1@1+ (1,0) [0|1] "" Vector__XXX
 SG_ TAS_a192_rideHeightObserverDiver m3 : 15|1@1+ (1,0) [0|1] "" Vector__XXX
 SG_ TAS_a193_EPAS3P_MIA m3 : 16|1@1+ (1,0) [0|1] "" Vector__XXX
 SG_ TAS_a194_a2bFrontAxleDataError m3 : 17|1@1+ (1,0) [0|1] "" Vector__XXX
 SG_ TAS_a195_a2bRearAxleDataError m3 : 18|1@1+ (1,0) [0|1] "" Vector__XXX
 SG_ TAS_a196_adaptiveDampingUsingDSP m3 : 19|1@1+ (1,0) [0|1] "" Vector__XXX
 SG_ TAS_a197_invalidAdaptiveModeRequ m3 : 20|1@1+ (1,0) [0|1] "" Vector__XXX
 SG_ TAS_a200_jackModeActive m3 : 23|1@1+ (1,0) [0|1] "" Vector__XXX
 SG_ TAS_a201_low12VBattery m3 : 24|1@1+ (1,0) [0|1] "" Vector__XXX
 SG_ TAS_a210_outOfRangeCalibration m3 : 33|1@1+ (1,0) [0|1] "" Vector__XXX
 SG_ TAS_a211_noRideHeightCalib m3 : 34|1@1+ (1,0) [0|1] "" Vector__XXX
 SG_ TAS_a213_yellowWarningLamp m3 : 36|1@1+ (1,0) [0|1] "" Vector__XXX
 SG_ TAS_a214_redWarningLamp m3 : 37|1@1+ (1,0) [0|1] "" Vector__XXX
 SG_ TAS_a215_limpHomeMode10 m3 : 38|1@1+ (1,0) [0|1] "" Vector__XXX
 SG_ TAS_a216_limpHomeMode20 m3 : 39|1@1+ (1,0) [0|1] "" Vector__XXX
 SG_ TAS_a217_limpHomeMode30 m3 : 40|1@1+ (1,0) [0|1] "" Vector__XXX
 SG_ TAS_a218_limpHomeMode40 m3 : 41|1@1+ (1,0) [0|1] "" Vector__XXX
 SG_ TAS_a220_exhaustGalleryFault m3 : 43|1@1+ (1,0) [0|1] "" Vector__XXX
 SG_ TAS_a221_valveLeakDetected m3 : 44|1@1+ (1,0) [0|1] "" Vector__XXX
 SG_ TAS_a222_compressorPrefillFault m3 : 45|1@1+ (1,0) [0|1] "" Vector__XXX
 SG_ TAS_a223_blockedAirline m3 : 46|1@1+ (1,0) [0|1] "" Vector__XXX
 SG_ TAS_a224_openAirline m3 : 47|1@1+ (1,0) [0|1] "" Vector__XXX
 SG_ TAS_a225_galleryPressureTooHigh m3 : 48|1@1+ (1,0) [0|1] "" Vector__XXX
 SG_ TAS_a226_PWMfastDetectFL m3 : 49|1@1+ (1,0) [0|1] "" Vector__XXX
 SG_ TAS_a227_PWMfastDetectFR m3 : 50|1@1+ (1,0) [0|1] "" Vector__XXX
 SG_ TAS_a228_PWMfastDetectRL m3 : 51|1@1+ (1,0) [0|1] "" Vector__XXX
 SG_ TAS_a229_PWMfastDetectRR m3 : 52|1@1+ (1,0) [0|1] "" Vector__XXX
 SG_ TAS_a230_notifyGeofence m3 : 53|1@1+ (1,0) [0|1] "" Vector__XXX
 SG_ TAS_a231_notifyRoughRoadRaise m3 : 54|1@1+ (1,0) [0|1] "" Vector__XXX
 SG_ TAS_a232_suspensionTypeMismatch m3 : 55|1@1+ (1,0) [0|1] "" Vector__XXX
 SG_ TAS_a233_compressorStuckOn m3 : 56|1@1+ (1,0) [0|1] "" Vector__XXX
 SG_ TAS_a234_damperHydraulicMismatch m3 : 57|1@1+ (1,0) [0|1] "" Vector__XXX
 SG_ TAS_a240_airSpringLeak m3 : 63|1@1+ (1,0) [0|1] "" Vector__XXX
 SG_ TAS_a284_serviceRunModeActive m4 : 47|1@1+ (1,0) [0|1] "" Vector__XXX
 SG_ TAS_a285_twistSustainedUserVis m4 : 48|1@1+ (1,0) [0|1] "" Vector__XXX
 SG_ TAS_a286_driveCycleStats1 m4 : 49|1@1+ (1,0) [0|1] "" Vector__XXX
 SG_ TAS_a287_driveCycleStats2 m4 : 50|1@1+ (1,0) [0|1] "" Vector__XXX
 SG_ TAS_a288_driveCycleStats3 m4 : 51|1@1+ (1,0) [0|1] "" Vector__XXX
 SG_ TAS_a289_driveCycleStats4 m4 : 52|1@1+ (1,0) [0|1] "" Vector__XXX
 SG_ TAS_a290_twistSustainedAtSpeed m4 : 53|1@1+ (1,0) [0|1] "" Vector__XXX
 SG_ TAS_a291_frontAxleTooHigh m4 : 54|1@1+ (1,0) [0|1] "" Vector__XXX
 SG_ TAS_a292_rearAxleTooHigh m4 : 55|1@1+ (1,0) [0|1] "" Vector__XXX
 SG_ TAS_a293_frontAxleTooLow m4 : 56|1@1+ (1,0) [0|1] "" Vector__XXX
 SG_ TAS_a294_rearAxleTooLow m4 : 57|1@1+ (1,0) [0|1] "" Vector__XXX
 SG_ TAS_a295_targetHeightNotMet m4 : 58|1@1+ (1,0) [0|1] "" Vector__XXX
 SG_ TAS_a296_chassisTypeMismatch m4 : 59|1@1+ (1,0) [0|1] "" Vector__XXX
 SG_ TAS_a297_vinMismatch m4 : 60|1@1+ (1,0) [0|1] "" Vector__XXX
 SG_ TAS_a298_vinNotLearned m4 : 61|1@1+ (1,0) [0|1] "" Vector__XXX
 SG_ TAS_a299_offsetEstimateTooLarge m4 : 62|1@1+ (1,0) [0|1] "" Vector__XXX
 SG_ TAS_a300_offsetEstimateData1 m4 : 63|1@1+ (1,0) [0|1] "" Vector__XXX
 SG_ TAS_a301_offsetEstimateData2 m5 : 4|1@1+ (1,0) [0|1] "" Vector__XXX
 SG_ TAS_a303_massEstimateFrozen m5 : 6|1@1+ (1,0) [0|1] "" Vector__XXX
 SG_ TAS_a304_massEstimateFrozenData m5 : 7|1@1+ (1,0) [0|1] "" Vector__XXX
 SG_ TAS_a305_newEndstopPosition m5 : 8|1@1+ (1,0) [0|1] "" Vector__XXX
 SG_ TAS_a306_hardwareProtectFrozen m5 : 9|1@1+ (1,0) [0|1] "" Vector__XXX
 SG_ TAS_a307_endstopBoundaryComp m5 : 10|1@1+ (1,0) [0|1] "" Vector__XXX
 SG_ TAS_a308_endstopBoundaryRbnd m5 : 11|1@1+ (1,0) [0|1] "" Vector__XXX
 SG_ TAS_a309_controlFrozen m5 : 12|1@1+ (1,0) [0|1] "" Vector__XXX
 SG_ TAS_a310_controlFrozenData m5 : 13|1@1+ (1,0) [0|1] "" Vector__XXX
 SG_ TAS_a311_accelsMIA m5 : 14|1@1+ (1,0) [0|1] "" Vector__XXX
 SG_ TAS_a312_rotationalRatesMIA m5 : 15|1@1+ (1,0) [0|1] "" Vector__XXX
 SG_ TAS_a313_dampingCntrlDisabled m5 : 16|1@1+ (1,0) [0|1] "" Vector__XXX
 SG_ TAS_a314_dampingReduced m5 : 17|1@1+ (1,0) [0|1] "" Vector__XXX
 SG_ TAS_a315_pcbaHighTemp m5 : 18|1@1+ (1,0) [0|1] "" Vector__XXX
 SG_ TAS_a316_offsetsAccels m5 : 19|1@1+ (1,0) [0|1] "" Vector__XXX
 SG_ TAS_a317_offsetsRotationalRates m5 : 20|1@1+ (1,0) [0|1] "" Vector__XXX
 SG_ TAS_a318_dampingCntrlInputMIA m5 : 21|1@1+ (1,0) [0|1] "" Vector__XXX
 SG_ TAS_a319_drivetrainTypeMismatch m5 : 22|1@1+ (1,0) [0|1] "" Vector__XXX
 SG_ TAS_a320_offsetsRotationalRates m5 : 23|1@1+ (1,0) [0|1] "" Vector__XXX
 SG_ TAS_a321_speedBumpAttributes1 m5 : 24|1@1+ (1,0) [0|1] "" Vector__XXX
 SG_ TAS_a322_speedBumpAttributes2 m5 : 25|1@1+ (1,0) [0|1] "" Vector__XXX
 SG_ TAS_a332_levelingThresholds1 m5 : 35|1@1+ (1,0) [0|1] "" Vector__XXX
 SG_ TAS_a333_levelingThresholds2 m5 : 36|1@1+ (1,0) [0|1] "" Vector__XXX

BO_ 523 TAS_axleData: 8 TAS
 SG_ TAS_axleIndex M : 0|1@1+ (1,0) [0|1] "" Vector__XXX
 SG_ TAS_rawHeightFL m0 : 4|10@1+ (1,-512) [-512|510] "mm" Vector__XXX
 SG_ TAS_staticHeightEstimateFL m0 : 14|10@1+ (1,-512) [-512|510] "mm" Vector__XXX
 SG_ TAS_componentPressureFL m0 : 24|8@1+ (0.1,0) [0|25.4] "bara" Vector__XXX
 SG_ TAS_rawHeightFR m0 : 32|10@1+ (1,-512) [-512|510] "mm" Vector__XXX
 SG_ TAS_staticHeightEstimateFR m0 : 42|10@1+ (1,-512) [-512|510] "mm" Vector__XXX
 SG_ TAS_componentPressureFR m0 : 52|8@1+ (0.1,0) [0|25.4] "bara" Vector__XXX
 SG_ TAS_rawHeightRL m1 : 4|10@1+ (1,-512) [-512|510] "mm" Vector__XXX
 SG_ TAS_staticHeightEstimateRL m1 : 14|10@1+ (1,-512) [-512|510] "mm" Vector__XXX
 SG_ TAS_componentPressureRL m1 : 24|8@1+ (0.1,0) [0|25.4] "bara" Vector__XXX
 SG_ TAS_rawHeightRR m1 : 32|10@1+ (1,-512) [-512|510] "mm" Vector__XXX
 SG_ TAS_staticHeightEstimateRR m1 : 42|10@1+ (1,-512) [-512|510] "mm" Vector__XXX
 SG_ TAS_componentPressureRR m1 : 52|8@1+ (0.1,0) [0|25.4] "bara" Vector__XXX

BO_ 1398 TAS_dampingStates: 8 TAS
 SG_ TAS_endstopState : 0|1@1+ (1,0) [0|1] "" Vector__XXX
 SG_ TAS_continuousControlState : 1|1@1+ (1,0) [0|1] "" Vector__XXX
 SG_ TAS_activeTireTune : 2|1@1+ (1,0) [0|1] "" Vector__XXX
 SG_ TAS_roughnessRaiseReason : 3|2@1+ (1,0) [0|3] "" Vector__XXX
 SG_ TAS_frontMetricDrivesRear : 5|2@1+ (1,0) [0|3] "" Vector__XXX
 SG_ TAS_roadCondition : 8|8@1+ (0.005,0) [0|1.27] "-" Vector__XXX
 SG_ TAS_bellyProtect : 16|2@1+ (1,0) [0|3] "" Vector__XXX
 SG_ TAS_frontMetricDrivesFront : 18|2@1+ (1,0) [0|3] "" Vector__XXX
 SG_ TAS_speedBumpAxleFront : 20|3@1+ (1,0) [0|7] "" Vector__XXX
 SG_ TAS_speedBumpAxleRear : 23|3@1+ (1,0) [0|7] "" Vector__XXX
 SG_ TAS_holeProtectFL : 26|2@1+ (1,0) [0|3] "" Vector__XXX
 SG_ TAS_holeProtectFR : 28|2@1+ (1,0) [0|3] "" Vector__XXX
 SG_ TAS_holeProtectRL : 30|2@1+ (1,0) [0|3] "" Vector__XXX
 SG_ TAS_holeProtectRR : 32|2@1+ (1,0) [0|3] "" Vector__XXX
 SG_ TAS_stepProtectFL : 34|2@1+ (1,0) [0|3] "" Vector__XXX
 SG_ TAS_stepProtectFR : 36|2@1+ (1,0) [0|3] "" Vector__XXX
 SG_ TAS_stepProtectRL : 38|2@1+ (1,0) [0|3] "" Vector__XXX
 SG_ TAS_stepProtectRR : 40|2@1+ (1,0) [0|3] "" Vector__XXX
 SG_ TAS_FDUTorqueCorruptionScale : 42|4@1+ (0.075,0) [0|1.05] "-" Vector__XXX
 SG_ TAS_sprungMassEstimate : 46|5@1+ (64,1800) [1800|3720] "kg" Vector__XXX
 SG_ TAS_anyDamperActive : 51|1@1+ (1,0) [0|1] "" Vector__XXX
 SG_ TAS_dampingStatesCounter : 52|4@1+ (1,0) [0|15] "" Vector__XXX
 SG_ TAS_dampingStatesChecksum : 56|8@1+ (1,0) [0|255] "" Vector__XXX

BO_ 1357 TAS_info: 8 TAS
 SG_ TAS_infoIndex M : 0|8@1+ (1,0) [0|255] "" Vector__XXX
 SG_ TAS_infoBuildType m10 : 8|8@1+ (1,0) [0|255] "" Vector__XXX
 SG_ TAS_infoBuildConfigId m10 : 16|16@1+ (1,0) [0|65535] "" Vector__XXX
 SG_ TAS_infoHardwareId m10 : 32|1@1+ (1,0) [0|1] "" Vector__XXX
 SG_ TAS_infoComponentId m10 : 48|16@1+ (1,0) [0|65535] "" Vector__XXX
 SG_ TAS_infoPcbaId m11 : 16|8@1+ (1,0) [0|255] "" Vector__XXX
 SG_ TAS_infoAssemblyId m11 : 24|8@1+ (1,0) [0|254] "" Vector__XXX
 SG_ TAS_infoUsageId m11 : 32|16@1+ (1,0) [0|65535] "" Vector__XXX
 SG_ TAS_infoSubUsageId m11 : 48|16@1+ (1,0) [0|65535] "" Vector__XXX
 SG_ TAS_infoAppCrc m13 : 32|32@1+ (1,0) [0|4294967295] "" Vector__XXX
 SG_ TAS_infoAppGitHash m17 : 8|56@1+ (1,0) [0|7.20575940379e+16] "" Vector__XXX
 SG_ TAS_infoBootGitHash m18 : 8|56@1+ (1,0) [0|7.20575940379e+16] "" Vector__XXX
 SG_ TAS_infoPlatformType m19 : 8|8@1+ (1,0) [0|255] "" Vector__XXX
 SG_ TAS_infoMajorVersion m19 : 16|8@1+ (1,0) [0|254] "" Vector__XXX
 SG_ TAS_infoBranchOrigin m19 : 24|8@1+ (1,0) [0|254] "" Vector__XXX
 SG_ TAS_infoMaturity m19 : 32|8@1+ (1,0) [0|254] "" Vector__XXX
 SG_ TAS_infoHardwareRevision m19 : 40|8@1+ (1,0) [0|254] "" Vector__XXX

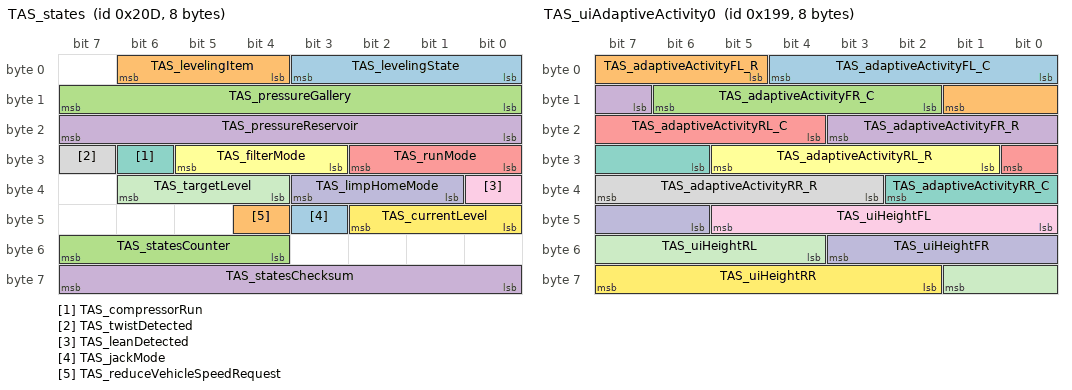
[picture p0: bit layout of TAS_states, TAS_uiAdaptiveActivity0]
BO_ 525 TAS_states: 8 TAS
 SG_ TAS_levelingState : 0|4@1+ (1,0) [0|15] "" Vector__XXX
 SG_ TAS_levelingItem : 4|3@1+ (1,0) [0|7] "" Vector__XXX
 SG_ TAS_pressureGallery : 8|8@1+ (0.1,0) [0|25.4] "bara" Vector__XXX
 SG_ TAS_pressureReservoir : 16|8@1+ (0.1,0) [0|25.4] "bara" Vector__XXX
 SG_ TAS_runMode : 24|3@1+ (1,0) [0|7] "" Vector__XXX
 SG_ TAS_filterMode : 27|3@1+ (1,0) [0|7] "" Vector__XXX
 SG_ TAS_compressorRun : 30|1@1+ (1,0) [0|1] "" Vector__XXX
 SG_ TAS_twistDetected : 31|1@1+ (1,0) [0|1] "" Vector__XXX
 SG_ TAS_leanDetected : 32|1@1+ (1,0) [0|1] "" Vector__XXX
 SG_ TAS_limpHomeMode : 33|3@1+ (1,0) [0|7] "" Vector__XXX
 SG_ TAS_targetLevel : 36|3@1+ (1,0) [0|7] "" Vector__XXX
 SG_ TAS_currentLevel : 40|3@1+ (1,0) [0|7] "" Vector__XXX
 SG_ TAS_jackMode : 43|1@1+ (1,0) [0|1] "" Vector__XXX
 SG_ TAS_reduceVehicleSpeedRequest : 44|1@1+ (1,0) [0|1] "" Vector__XXX
 SG_ TAS_statesCounter : 52|4@1+ (1,0) [0|15] "" Vector__XXX
 SG_ TAS_statesChecksum : 56|8@1+ (1,0) [0|255] "" Vector__XXX

BO_ 409 TAS_uiAdaptiveActivity0: 8 TAS
 SG_ TAS_adaptiveActivityFL_C : 0|5@1+ (0.04,0) [0|1] "-" Vector__XXX
 SG_ TAS_adaptiveActivityFL_R : 5|5@1+ (0.04,0) [0|1] "-" Vector__XXX
 SG_ TAS_adaptiveActivityFR_C : 10|5@1+ (0.04,0) [0|1] "-" Vector__XXX
 SG_ TAS_adaptiveActivityFR_R : 15|5@1+ (0.04,0) [0|1] "-" Vector__XXX
 SG_ TAS_adaptiveActivityRL_C : 20|5@1+ (0.04,0) [0|1] "-" Vector__XXX
 SG_ TAS_adaptiveActivityRL_R : 25|5@1+ (0.04,0) [0|1] "-" Vector__XXX
 SG_ TAS_adaptiveActivityRR_C : 30|5@1+ (0.04,0) [0|1] "-" Vector__XXX
 SG_ TAS_adaptiveActivityRR_R : 35|5@1+ (0.04,0) [0|1] "-" Vector__XXX
 SG_ TAS_uiHeightFL : 40|6@1+ (4,-128) [-128|120] "mm" Vector__XXX
 SG_ TAS_uiHeightFR : 46|6@1+ (4,-128) [-128|120] "mm" Vector__XXX
 SG_ TAS_uiHeightRL : 52|6@1+ (4,-128) [-128|120] "mm" Vector__XXX
 SG_ TAS_uiHeightRR : 58|6@1+ (4,-128) [-128|120] "mm" Vector__XXX

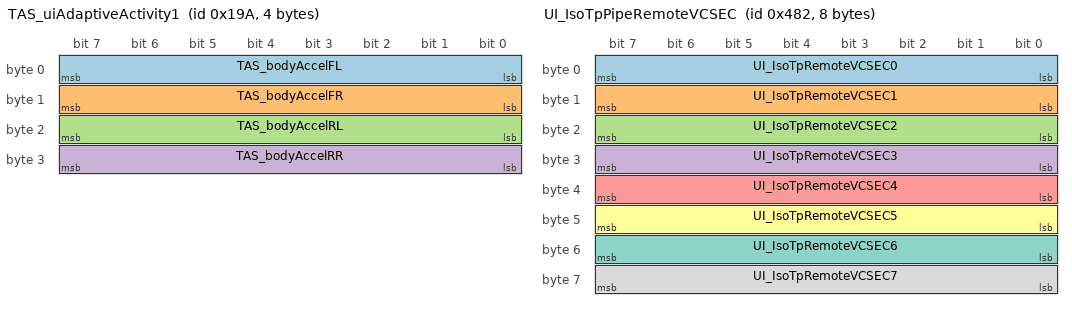
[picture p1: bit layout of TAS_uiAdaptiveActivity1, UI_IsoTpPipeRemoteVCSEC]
BO_ 410 TAS_uiAdaptiveActivity1: 4 TAS
 SG_ TAS_bodyAccelFL : 0|8@1+ (0.05,-5) [-5|5] "g" Vector__XXX
 SG_ TAS_bodyAccelFR : 8|8@1+ (0.05,-5) [-5|5] "g" Vector__XXX
 SG_ TAS_bodyAccelRL : 16|8@1+ (0.05,-5) [-5|5] "g" Vector__XXX
 SG_ TAS_bodyAccelRR : 24|8@1+ (0.05,-5) [-5|5] "g" Vector__XXX

BO_ 538 TAS_uiControl: 5 TAS
 SG_ TAS_yellowWarningLamp : 0|1@1+ (1,0) [0|1] "" Vector__XXX
 SG_ TAS_redWarningLamp : 1|1@1+ (1,0) [0|1] "" Vector__XXX
 SG_ TAS_veryLowAllowed : 2|1@1+ (1,0) [0|1] "" Vector__XXX
 SG_ TAS_lowAllowed : 3|1@1+ (1,0) [0|1] "" Vector__XXX
 SG_ TAS_standardAllowed : 4|1@1+ (1,0) [0|1] "" Vector__XXX
 SG_ TAS_highAllowed : 5|1@1+ (1,0) [0|1] "" Vector__XXX
 SG_ TAS_veryHighAllowed : 6|1@1+ (1,0) [0|1] "" Vector__XXX
 SG_ TAS_extractAllowed : 7|1@1+ (1,0) [0|1] "" Vector__XXX
 SG_ TAS_showSpinner : 9|1@1+ (1,0) [0|1] "" Vector__XXX
 SG_ TAS_adaptiveRideModeOverride : 10|2@1+ (1,0) [0|2] "" Vector__XXX
 SG_ TAS_levelSelectEnabled : 12|1@1+ (1,0) [0|1] "" Vector__XXX
 SG_ TAS_jackModeToggleEnabled : 13|1@1+ (1,0) [0|1] "" Vector__XXX
 SG_ TAS_adaptiveRideSelectEnabled : 14|1@1+ (1,0) [0|1] "" Vector__XXX
 SG_ TAS_launchModeState : 16|3@1+ (1,0) [0|7] "" Vector__XXX
 SG_ TAS_restrictUpLevelingFalcons : 19|1@1+ (1,0) [0|1] "" Vector__XXX
 SG_ TAS_restrictUpLevelingTrunk : 20|1@1+ (1,0) [0|1] "" Vector__XXX
 SG_ TAS_restrictDownLevelingDoors : 21|1@1+ (1,0) [0|1] "" Vector__XXX
 SG_ TAS_restrictLevelingChargeCable : 22|1@1+ (1,0) [0|1] "" Vector__XXX
 SG_ TAS_restrictLevelingSystemCheck : 23|1@1+ (1,0) [0|1] "" Vector__XXX
 SG_ TAS_restrictLevelingTransport : 24|1@1+ (1,0) [0|1] "" Vector__XXX
 SG_ TAS_restrictLevelingShowroom : 25|1@1+ (1,0) [0|1] "" Vector__XXX
 SG_ TAS_uiControlCounter : 28|4@1+ (1,0) [0|15] "" Vector__XXX
 SG_ TAS_uiControlChecksum : 32|8@1+ (1,0) [0|255] "" Vector__XXX

BO_ 1154 UI_IsoTpPipeRemoteVCSEC: 8 GTW
 SG_ UI_IsoTpRemoteVCSEC0 : 0|8@1+ (1,0) [0|255] "" Vector__XXX
 SG_ UI_IsoTpRemoteVCSEC1 : 8|8@1+ (1,0) [0|255] "" Vector__XXX
 SG_ UI_IsoTpRemoteVCSEC2 : 16|8@1+ (1,0) [0|255] "" Vector__XXX
 SG_ UI_IsoTpRemoteVCSEC3 : 24|8@1+ (1,0) [0|255] "" Vector__XXX
 SG_ UI_IsoTpRemoteVCSEC4 : 32|8@1+ (1,0) [0|255] "" Vector__XXX
 SG_ UI_IsoTpRemoteVCSEC5 : 40|8@1+ (1,0) [0|255] "" Vector__XXX
 SG_ UI_IsoTpRemoteVCSEC6 : 48|8@1+ (1,0) [0|255] "" Vector__XXX
 SG_ UI_IsoTpRemoteVCSEC7 : 56|8@1+ (1,0) [0|255] "" Vector__XXX

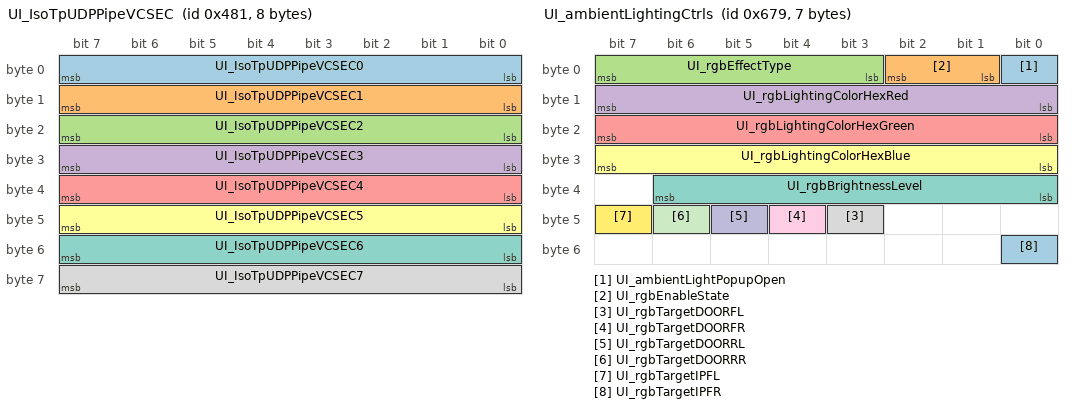
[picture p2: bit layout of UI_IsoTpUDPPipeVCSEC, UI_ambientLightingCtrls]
BO_ 1153 UI_IsoTpUDPPipeVCSEC: 8 GTW
 SG_ UI_IsoTpUDPPipeVCSEC0 : 0|8@1+ (1,0) [0|255] "" Vector__XXX
 SG_ UI_IsoTpUDPPipeVCSEC1 : 8|8@1+ (1,0) [0|255] "" Vector__XXX
 SG_ UI_IsoTpUDPPipeVCSEC2 : 16|8@1+ (1,0) [0|255] "" Vector__XXX
 SG_ UI_IsoTpUDPPipeVCSEC3 : 24|8@1+ (1,0) [0|255] "" Vector__XXX
 SG_ UI_IsoTpUDPPipeVCSEC4 : 32|8@1+ (1,0) [0|255] "" Vector__XXX
 SG_ UI_IsoTpUDPPipeVCSEC5 : 40|8@1+ (1,0) [0|255] "" Vector__XXX
 SG_ UI_IsoTpUDPPipeVCSEC6 : 48|8@1+ (1,0) [0|255] "" Vector__XXX
 SG_ UI_IsoTpUDPPipeVCSEC7 : 56|8@1+ (1,0) [0|255] "" Vector__XXX

BO_ 1657 UI_ambientLightingCtrls: 7 GTW
 SG_ UI_ambientLightPopupOpen : 0|1@1+ (1,0) [0|1] "" Vector__XXX
 SG_ UI_rgbEnableState : 1|2@1+ (1,0) [0|3] "" Vector__XXX
 SG_ UI_rgbEffectType : 3|5@1+ (1,0) [0|31] "" Vector__XXX
 SG_ UI_rgbLightingColorHexRed : 8|8@1+ (1,0) [0|255] "" Vector__XXX
 SG_ UI_rgbLightingColorHexGreen : 16|8@1+ (1,0) [0|255] "" Vector__XXX
 SG_ UI_rgbLightingColorHexBlue : 24|8@1+ (1,0) [0|255] "" Vector__XXX
 SG_ UI_rgbBrightnessLevel : 32|7@1+ (1,0) [0|100] "%" Vector__XXX
 SG_ UI_rgbTargetDOORFL : 43|1@1+ (1,0) [0|1] "" Vector__XXX
 SG_ UI_rgbTargetDOORFR : 44|1@1+ (1,0) [0|1] "" Vector__XXX
 SG_ UI_rgbTargetDOORRL : 45|1@1+ (1,0) [0|1] "" Vector__XXX
 SG_ UI_rgbTargetDOORRR : 46|1@1+ (1,0) [0|1] "" Vector__XXX
 SG_ UI_rgbTargetIPFL : 47|1@1+ (1,0) [0|1] "" Vector__XXX
 SG_ UI_rgbTargetIPFR : 48|1@1+ (1,0) [0|1] "" Vector__XXX

BO_ 1021 UI_autopilotControl: 8 GTW
 SG_ UI_autopilotControlIndex M : 0|3@1+ (1,0) [0|7] "" Vector__XXX
 SG_ UI_hovEnabled m0 : 3|1@1+ (1,0) [0|1] "" Vector__XXX
 SG_ UI_donDisableAutoWiperDuration m0 : 4|3@1+ (1,0) [0|7] "" Vector__XXX
 SG_ UI_donDisableOnAutoWiperSpeed m0 : 7|4@1+ (1,0) [0|15] "" Vector__XXX
 SG_ UI_blindspotMinSpeed m0 : 11|4@1+ (1,0) [0|15] "" Vector__XXX
 SG_ UI_blindspotDistance m0 : 15|3@1+ (1,0) [0|7] "" Vector__XXX
 SG_ UI_blindspotTTC m0 : 18|3@1+ (1,0) [0|7] "" Vector__XXX
 SG_ UI_donStopEndOfRampBuffer m0 : 21|3@1+ (1,0) [0|7] "" Vector__XXX
 SG_ UI_donDisableCutin m0 : 24|1@1+ (1,0) [0|1] "" Vector__XXX
 SG_ UI_smartSetSpeedOffset m0 : 25|6@1+ (1,-30) [-30|33] "%" Vector__XXX
 SG_ UI_smartSetSpeedOffsetType m0 : 31|1@1+ (1,0) [0|1] "" Vector__XXX
 SG_ UI_autopilotMonarchBackup m0 : 32|1@1+ (1,0) [0|1] "" Vector__XXX
 SG_ UI_fsdVisualizationEnabled m0 : 37|1@1+ (1,0) [0|1] "" Vector__XXX
 SG_ UI_fsdStopsControlEnabled m0 : 38|1@1+ (1,0) [0|1] "" Vector__XXX
 SG_ UI_fsdContinueOnGreenWithCIPV m0 : 39|1@1+ (1,0) [0|1] "" Vector__XXX
 SG_ UI_smartSetSpeed m0 : 40|1@1+ (1,0) [0|1] "" Vector__XXX
 SG_ UI_automaticSetSpeedOffset m0 : 41|1@1+ (1,0) [0|1] "" Vector__XXX
 SG_ UI_apply2021_1958_ISA m0 : 42|1@1+ (1,0) [0|1] "" Vector__XXX
 SG_ UI_apply2021_646_ELKS m0 : 43|1@1+ (1,0) [0|1] "" Vector__XXX
 SG_ UI_apply2021_1341_DDAW m0 : 44|1@1+ (1,0) [0|1] "" Vector__XXX
 SG_ UI_homelinkNearby m0 : 45|1@1+ (1,0) [0|1] "" Vector__XXX
 SG_ UI_enableFullSelfDriving m0 : 46|1@1+ (1,0) [0|1] "" Vector__XXX
 SG_ UI_hasFullSelfDriving m0 : 47|1@1+ (1,0) [0|1] "" Vector__XXX
 SG_ UI_autosteerActivation m0 : 48|1@1+ (1,0) [0|1] "" Vector__XXX
 SG_ UI_autopilotDrivingProfile m0 : 49|2@1+ (1,0) [0|3] "" Vector__XXX
 SG_ UI_fsdBetaRequest m0 : 51|1@1+ (1,0) [0|1] "" Vector__XXX
 SG_ UI_fullSelfDrivingSuspended m0 : 52|1@1+ (1,0) [0|1] "" Vector__XXX
 SG_ UI_disableOptionalLaneChanges m0 : 53|1@1+ (1,0) [0|1] "" Vector__XXX
 SG_ UI_applyR152_AEBS m0 : 59|1@1+ (1,0) [0|1] "" Vector__XXX
 SG_ UI_autopilotControlMux0Valid m0 : 63|1@1+ (1,0) [0|1] "" Vector__XXX
 SG_ UI_selectableCameraRequest m1 : 8|4@1+ (1,0) [0|14] "" Vector__XXX
 SG_ UI_overrideSleepWithSuspend m1 : 16|1@1+ (1,0) [0|1] "" Vector__XXX
 SG_ UI_driverMonitorConfirmation m1 : 17|1@1+ (1,0) [0|1] "" Vector__XXX
 SG_ UI_parkAssistUseVision m1 : 18|1@1+ (1,0) [0|1] "" Vector__XXX
 SG_ UI_applyEceR79 m1 : 19|1@1+ (1,0) [0|1] "" Vector__XXX
 SG_ UI_enableMapStops m1 : 20|1@1+ (1,0) [0|1] "" Vector__XXX
 SG_ UI_disableMain m1 : 23|1@1+ (1,0) [0|1] "" Vector__XXX
 SG_ UI_disableNarrow m1 : 24|1@1+ (1,0) [0|1] "" Vector__XXX
 SG_ UI_disableFisheye m1 : 25|1@1+ (1,0) [0|1] "" Vector__XXX
 SG_ UI_disableLeftPillar m1 : 26|1@1+ (1,0) [0|1] "" Vector__XXX
 SG_ UI_disableRightPillar m1 : 27|1@1+ (1,0) [0|1] "" Vector__XXX
 SG_ UI_disableLeftRepeater m1 : 28|1@1+ (1,0) [0|1] "" Vector__XXX
 SG_ UI_disableRightRepeater m1 : 29|1@1+ (1,0) [0|1] "" Vector__XXX
 SG_ UI_disableBackup m1 : 30|1@1+ (1,0) [0|1] "" Vector__XXX
 SG_ UI_disableRadar m1 : 31|1@1+ (1,0) [0|1] "" Vector__XXX
 SG_ UI_noStalkConfirmAlertHaptic m1 : 32|1@1+ (1,0) [0|1] "" Vector__XXX
 SG_ UI_regulatoryLKA m1 : 33|1@1+ (1,0) [0|1] "" Vector__XXX
 SG_ UI_regulatoryLaneAssistLevel m1 : 34|1@1+ (1,0) [0|1] "" Vector__XXX
 SG_ UI_ulcSnooze m1 : 36|1@1+ (1,0) [0|1] "" Vector__XXX
 SG_ UI_noStalkConfirmAlertChime m1 : 37|1@1+ (1,0) [0|1] "" Vector__XXX
 SG_ UI_factorySummonEnable m1 : 39|1@1+ (1,0) [0|1] "" Vector__XXX
 SG_ UI_apmv3Branch m1 : 40|3@1+ (1,0) [0|7] "" Vector__XXX
 SG_ UI_enableCabinCamera m1 : 43|1@1+ (1,0) [0|1] "" Vector__XXX
 SG_ UI_enableAutopilotStopWarning m1 : 44|1@1+ (1,0) [0|1] "" Vector__XXX
 SG_ UI_showLaneGraph m1 : 45|1@1+ (1,0) [0|1] "" Vector__XXX
 SG_ UI_showTrackLabels m1 : 46|1@1+ (1,0) [0|1] "" Vector__XXX
 SG_ UI_hardCoreSummon m1 : 47|1@1+ (1,0) [0|1] "" Vector__XXX
 SG_ UI_enableCabinCameraTelemetry m1 : 48|1@1+ (1,0) [0|1] "" Vector__XXX
 SG_ UI_enableVisionSpeedControl m1 : 49|1@1+ (1,0) [0|1] "" Vector__XXX
 SG_ UI_autopilotTelemetryInChina m1 : 50|1@1+ (1,0) [0|1] "" Vector__XXX
 SG_ UI_enableTeslaAutopark m1 : 51|1@1+ (1,0) [0|1] "" Vector__XXX
 SG_ UI_autoTurnSignalMode m1 : 52|1@1+ (1,0) [0|1] "" Vector__XXX
 SG_ UI_enableCautionLightControl m1 : 54|1@1+ (1,0) [0|1] "" Vector__XXX
 SG_ UI_applyEceR79SmartSummonOnly m1 : 55|1@1+ (1,0) [0|1] "" Vector__XXX
 SG_ UI_autopilotMonarchEnabled m1 : 56|1@1+ (1,0) [0|1] "" Vector__XXX
 SG_ UI_autopilotEphemerisEnabled m1 : 57|1@1+ (1,0) [0|1] "" Vector__XXX
 SG_ UI_enableCabinAudioRecording m1 : 59|1@1+ (1,0) [0|1] "" Vector__XXX
 SG_ UI_autopilotControlMux1Valid m1 : 63|1@1+ (1,0) [0|1] "" Vector__XXX
 SG_ UI_enableApproachingEmergencyVeh m2 : 5|1@1+ (1,0) [0|1] "" Vector__XXX
 SG_ UI_enableStartFsdFromParkBrakeCo m2 : 6|1@1+ (1,0) [0|1] "" Vector__XXX
 SG_ UI_enableStartFsdFromPark m2 : 7|1@1+ (1,0) [0|1] "" Vector__XXX
 SG_ UI_fsdMaxSpeedOffsetPercentage m2 : 8|6@1+ (1,0) [0|63] "%" Vector__XXX
 SG_ UI_coldStartMonarchInFactory m2 : 16|1@1+ (1,0) [0|1] "" Vector__XXX
 SG_ UI_autopilotControlMux2Valid m2 : 63|1@1+ (1,0) [0|1] "" Vector__XXX

BO_ 819 UI_chargeRequest: 5 GTW
 SG_ UI_openChargePortDoorRequest : 0|1@1+ (1,0) [0|1] "" Vector__XXX
 SG_ UI_closeChargePortDoorRequest : 1|1@1+ (1,0) [0|1] "" Vector__XXX
 SG_ UI_chargeEnableRequest : 2|1@1+ (1,0) [0|1] "" Vector__XXX
 SG_ UI_brickVLoggingRequest : 3|1@1+ (1,0) [0|1] "" Vector__XXX
 SG_ UI_brickBalancingDisabled : 4|1@1+ (1,0) [0|1] "" Vector__XXX
 SG_ UI_dSocAlertThreshold : 5|3@1+ (0.5,-4) [-4|-0.5] "%" Vector__XXX
 SG_ UI_acChargeCurrentLimit : 8|7@1+ (1,0) [0|126] "A" Vector__XXX
 SG_ UI_dSocAlertEnable : 15|1@1+ (1,0) [0|1] "" Vector__XXX
 SG_ UI_chargeTerminationPct : 16|10@1+ (0.1,0) [5|100] "%" Vector__XXX
 SG_ UI_chargeFeature1 : 26|1@1+ (1,0) [0|1] "" Vector__XXX
 SG_ UI_chargeFeature2 : 27|1@1+ (1,0) [0|1] "" Vector__XXX
 SG_ UI_chargeFeature3 : 28|1@1+ (1,0) [0|1] "" Vector__XXX
 SG_ UI_scheduledDepartureEnabled : 29|1@1+ (1,0) [0|1] "" Vector__XXX
 SG_ UI_chargePortLatchRequest : 30|2@1+ (1,0) [0|3] "" Vector__XXX
 SG_ UI_socSnapshotExpirationTime : 32|4@1+ (2,2) [2|32] "weeks" Vector__XXX
 SG_ UI_cpInletHeaterRequest : 36|2@1+ (1,0) [0|3] "" Vector__XXX
 SG_ UI_chargePowerSampleRequest : 38|1@1+ (1,0) [0|1] "" Vector__XXX
 SG_ UI_enableIso15118 : 39|1@1+ (1,0) [0|1] "" Vector__XXX

BO_ 659 UI_chassisControl: 8 GTW
 SG_ UI_steeringTuneRequest : 0|2@1+ (1,0) [0|3] "" Vector__XXX
 SG_ UI_tractionControlMode : 2|3@1+ (1,0) [0|7] "" Vector__XXX
 SG_ UI_parkBrakeRequest : 5|2@1+ (1,0) [0|2] "" Vector__XXX
 SG_ UI_narrowGarages : 7|1@1+ (1,0) [0|1] "" Vector__XXX
 SG_ UI_winchModeRequest : 8|2@1+ (1,0) [0|3] "" Vector__XXX
 SG_ UI_zeroSpeedConfirmed : 10|2@1+ (1,0) [0|2] "" Vector__XXX
 SG_ UI_trailerMode : 12|1@1+ (1,0) [0|1] "" Vector__XXX
 SG_ UI_distanceUnits : 13|1@1+ (1,0) [0|1] "" Vector__XXX
 SG_ UI_dasDebugEnable : 14|1@1+ (1,0) [0|1] "" Vector__XXX
 SG_ UI_accOvertakeEnable : 16|2@1+ (1,0) [0|2] "" Vector__XXX
 SG_ UI_aebEnable : 18|2@1+ (1,0) [0|2] "" Vector__XXX
 SG_ UI_aesEnable : 20|2@1+ (1,0) [0|2] "" Vector__XXX
 SG_ UI_ahlbEnable : 22|2@1+ (1,0) [0|2] "" Vector__XXX
 SG_ UI_autoLaneChangeEnable : 24|2@1+ (1,0) [0|2] "" Vector__XXX
 SG_ UI_winchProxUserOverride : 26|1@1+ (1,0) [0|1] "" Vector__XXX
 SG_ UI_rebootAutopilot : 27|1@1+ (1,0) [0|1] "" Vector__XXX
 SG_ UI_autoParkRequest : 28|4@1+ (1,0) [0|14] "" Vector__XXX
 SG_ UI_bsdEnable : 32|2@1+ (1,0) [0|2] "" Vector__XXX
 SG_ UI_fcwEnable : 34|2@1+ (1,0) [0|2] "" Vector__XXX
 SG_ UI_fcwSensitivity : 36|2@1+ (1,0) [0|2] "" Vector__XXX
 SG_ UI_latControlEnable : 38|2@1+ (1,0) [0|2] "" Vector__XXX
 SG_ UI_ldwEnable : 40|2@1+ (1,0) [0|2] "" Vector__XXX
 SG_ UI_pedalSafetyEnable : 42|2@1+ (1,0) [0|2] "" Vector__XXX
 SG_ UI_pedalMap_epas : 44|2@1+ (1,0) [0|3] "" Vector__XXX
 SG_ UI_redLightStopSignEnable : 46|2@1+ (1,0) [0|2] "" Vector__XXX
 SG_ UI_selfParkTune : 48|4@1+ (1,0) [0|14] "" Vector__XXX
 SG_ UI_chassisControlCounter : 52|4@1+ (1,0) [0|15] "" Vector__XXX
 SG_ UI_chassisControlChecksum : 56|8@1+ (1,0) [0|255] "" Vector__XXX

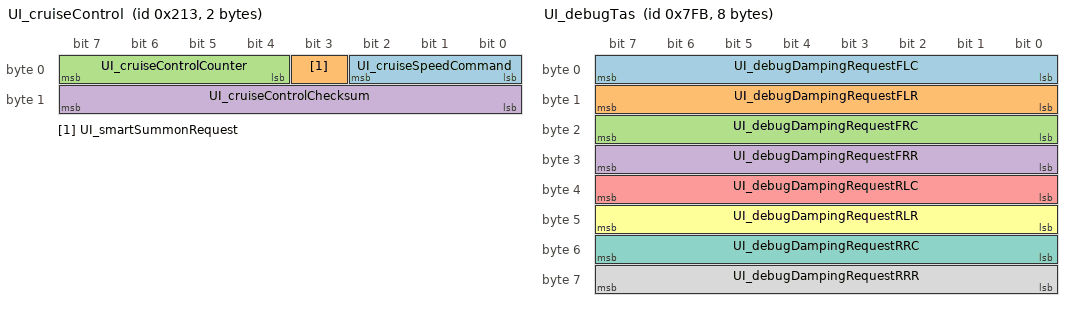
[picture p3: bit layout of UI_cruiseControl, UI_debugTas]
BO_ 531 UI_cruiseControl: 2 GTW
 SG_ UI_cruiseSpeedCommand : 0|3@1+ (1,0) [0|7] "" Vector__XXX
 SG_ UI_smartSummonRequest : 3|1@1+ (1,0) [0|1] "" Vector__XXX
 SG_ UI_cruiseControlCounter : 4|4@1+ (1,0) [0|15] "" Vector__XXX
 SG_ UI_cruiseControlChecksum : 8|8@1+ (1,0) [0|255] "" Vector__XXX

BO_ 1280 UI_debugECU: 2 GTW
 SG_ UI_debugEcuTarget M : 0|5@1+ (1,0) [0|31] "" Vector__XXX
 SG_ UI_DI_debugEnable m1 : 8|1@1+ (1,0) [0|1] "" Vector__XXX
 SG_ UI_DIS_debugEnable m2 : 8|1@1+ (1,0) [0|1] "" Vector__XXX
 SG_ UI_PM_debugEnable m3 : 8|1@1+ (1,0) [0|1] "" Vector__XXX
 SG_ UI_PM_debugAt100Hz m3 : 9|1@1+ (1,0) [0|1] "" Vector__XXX
 SG_ UI_PMS_debugEnable m4 : 8|1@1+ (1,0) [0|1] "" Vector__XXX
 SG_ UI_PMS_debugAt100Hz m4 : 9|1@1+ (1,0) [0|1] "" Vector__XXX
 SG_ UI_BMS_debugAllEnable m5 : 8|1@1+ (1,0) [0|1] "" Vector__XXX
 SG_ UI_BMS_debugDisable m5 : 9|1@1+ (1,0) [0|1] "" Vector__XXX
 SG_ UI_VCRIGHT_debugEnable m6 : 8|1@1+ (1,0) [0|1] "" Vector__XXX
 SG_ UI_VCFRONT_debugEnable m7 : 5|1@1+ (1,0) [0|1] "" Vector__XXX
 SG_ UI_DIF_debugEnable m8 : 8|1@1+ (1,0) [0|1] "" Vector__XXX
 SG_ UI_DIR_debugEnable m9 : 8|1@1+ (1,0) [0|1] "" Vector__XXX
 SG_ UI_PMF_debugEnable m10 : 8|1@1+ (1,0) [0|1] "" Vector__XXX
 SG_ UI_PMR_debugEnable m11 : 8|1@1+ (1,0) [0|1] "" Vector__XXX

BO_ 2043 UI_debugTas: 8 GTW
 SG_ UI_debugDampingRequestFLC : 0|8@1+ (0.01,0) [0|2.54] "A" Vector__XXX
 SG_ UI_debugDampingRequestFLR : 8|8@1+ (0.01,0) [0|2.54] "A" Vector__XXX
 SG_ UI_debugDampingRequestFRC : 16|8@1+ (0.01,0) [0|2.54] "A" Vector__XXX
 SG_ UI_debugDampingRequestFRR : 24|8@1+ (0.01,0) [0|2.54] "A" Vector__XXX
 SG_ UI_debugDampingRequestRLC : 32|8@1+ (0.01,0) [0|2.54] "A" Vector__XXX
 SG_ UI_debugDampingRequestRLR : 40|8@1+ (0.01,0) [0|2.54] "A" Vector__XXX
 SG_ UI_debugDampingRequestRRC : 48|8@1+ (0.01,0) [0|2.54] "A" Vector__XXX
 SG_ UI_debugDampingRequestRRR : 56|8@1+ (0.01,0) [0|2.54] "A" Vector__XXX

BO_ 568 UI_driverAssistMapData: 8 GTW
 SG_ UI_mapSpeedLimitDependency : 0|3@1+ (1,0) [0|6] "" Vector__XXX
 SG_ UI_roadClass : 3|3@1+ (1,0) [1|7] "" Vector__XXX
 SG_ UI_inSuperchargerGeofence : 6|1@1+ (1,0) [0|1] "" Vector__XXX
 SG_ UI_mapSpeedUnits : 7|1@1+ (1,0) [0|1] "" Vector__XXX
 SG_ UI_mapSpeedLimit : 8|5@1+ (1,0) [0|30] "" Vector__XXX
 SG_ UI_mapSpeedLimitType : 13|3@1+ (1,0) [0|6] "" Vector__XXX
 SG_ UI_countryCode : 16|10@1+ (1,0) [0|1022] "" Vector__XXX
 SG_ UI_streetCount : 26|2@1+ (1,0) [0|3] "" Vector__XXX
 SG_ UI_gpsRoadMatch : 28|1@1+ (1,0) [0|1] "" Vector__XXX
 SG_ UI_navRouteActive : 29|1@1+ (1,0) [0|1] "" Vector__XXX
 SG_ UI_parallelAutoparkEnabled : 30|1@1+ (1,0) [0|1] "" Vector__XXX
 SG_ UI_perpendicularAutoparkEnabled : 31|1@1+ (1,0) [0|1] "" Vector__XXX
 SG_ UI_nextBranchDist : 32|5@1+ (10,0) [0|300] "m" Vector__XXX
 SG_ UI_controlledAccess : 37|1@1+ (1,0) [0|1] "" Vector__XXX
 SG_ UI_nextBranchLeftOffRamp : 38|1@1+ (1,0) [0|1] "" Vector__XXX
 SG_ UI_nextBranchRightOffRamp : 39|1@1+ (1,0) [0|1] "" Vector__XXX
 SG_ UI_rejectLeftLane : 40|1@1+ (1,0) [0|1] "" Vector__XXX
 SG_ UI_rejectRightLane : 41|1@1+ (1,0) [0|1] "" Vector__XXX
 SG_ UI_rejectHPP : 42|1@1+ (1,0) [0|1] "" Vector__XXX
 SG_ UI_rejectNav : 43|1@1+ (1,0) [0|1] "" Vector__XXX
 SG_ UI_rejectLeftFreeSpace : 44|1@1+ (1,0) [0|1] "" Vector__XXX
 SG_ UI_rejectRightFreeSpace : 45|1@1+ (1,0) [0|1] "" Vector__XXX
 SG_ UI_rejectAutosteer : 46|1@1+ (1,0) [0|1] "" Vector__XXX
 SG_ UI_rejectHandsOn : 47|1@1+ (1,0) [0|1] "" Vector__XXX
 SG_ UI_acceptBottsDots : 48|1@1+ (1,0) [0|1] "" Vector__XXX
 SG_ UI_autosteerRestricted : 49|1@1+ (1,0) [0|1] "" Vector__XXX
 SG_ UI_pmmEnabled : 50|1@1+ (1,0) [0|1] "" Vector__XXX
 SG_ UI_scaEnabled : 51|1@1+ (1,0) [0|1] "" Vector__XXX
 SG_ UI_mapDataCounter : 52|4@1+ (1,0) [0|15] "" Vector__XXX
 SG_ UI_mapDataChecksum : 56|8@1+ (1,0) [0|255] "" Vector__XXX

BO_ 645 UI_driverProfileRecall: 8 GTW
 SG_ UI_driverProfileRecallIndex M : 0|3@1+ (1,0) [1|7] "" Vector__XXX
 SG_ UI_driverProfileRecallStop : 3|1@1+ (1,0) [0|1] "" Vector__XXX
 SG_ UI_frontSeatRecallActive m1 : 4|1@1+ (1,0) [0|1] "" Vector__XXX
 SG_ UI_frontSeatTrackPos m1 : 5|10@1- (4,0) [-2048|2044] "mm" Vector__XXX
 SG_ UI_frontSeatBackPos m1 : 16|12@1- (0.1,0) [-204.8|204.7] "deg" Vector__XXX
 SG_ UI_frontSeatLiftPos m1 : 32|10@1- (4,0) [-2048|2044] "mm" Vector__XXX
 SG_ UI_frontSeatTiltPos m1 : 48|12@1- (0.1,0) [-204.8|204.7] "deg" Vector__XXX
 SG_ UI_columnAndLumbarRecallActive m2 : 4|1@1+ (1,0) [0|1] "" Vector__XXX
 SG_ UI_steeringColumnUpDownPos m2 : 8|8@1- (1,103) [-25|230] "mm" Vector__XXX
 SG_ UI_lumbarAPressureHpa m2 : 16|16@1+ (1,0) [0|65535] "" Vector__XXX
 SG_ UI_lumbarBPressureHpa m2 : 32|16@1+ (1,0) [0|65535] "" Vector__XXX
 SG_ UI_steeringColumnInOutPos m2 : 48|8@1- (1,103) [-25|230] "mm" Vector__XXX
 SG_ UI_leftMirrorTiltXPosition m3 : 8|8@1+ (0.02,0) [0|5] "V" Vector__XXX
 SG_ UI_leftMirrorTiltYPosition m3 : 16|8@1+ (0.02,0) [0|5] "V" Vector__XXX
 SG_ UI_rightMirrorTiltXPosition m3 : 24|8@1+ (0.02,0) [0|5.1] "V" Vector__XXX
 SG_ UI_rightMirrorTiltYPosition m3 : 32|8@1+ (0.02,0) [0|5.1] "V" Vector__XXX
 SG_ UI_mirrorRecallActive m4 : 4|1@1+ (1,0) [0|1] "" Vector__XXX
 SG_ UI_customMirrorDipPositionsSet m4 : 5|1@1+ (1,0) [0|1] "" Vector__XXX
 SG_ UI_leftMirrorDipXPosition m4 : 8|8@1+ (0.02,0) [0|5] "V" Vector__XXX
 SG_ UI_leftMirrorDipYPosition m4 : 16|8@1+ (0.02,0) [0|5] "V" Vector__XXX
 SG_ UI_rightMirrorDipXPosition m4 : 24|8@1+ (0.02,0) [0|5.1] "V" Vector__XXX
 SG_ UI_rightMirrorDipYPosition m4 : 32|8@1+ (0.02,0) [0|5.1] "V" Vector__XXX
 SG_ UI_modifyMirrorDipRequest m4 : 40|2@1+ (1,0) [0|3] "" Vector__XXX

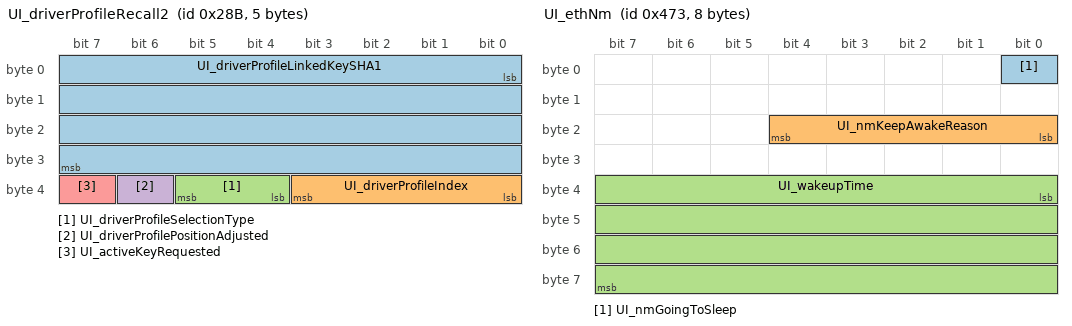
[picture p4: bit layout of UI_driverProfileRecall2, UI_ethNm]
BO_ 651 UI_driverProfileRecall2: 5 GTW
 SG_ UI_driverProfileLinkedKeySHA1 : 0|32@1+ (1,0) [0|4294967294] "" Vector__XXX
 SG_ UI_driverProfileIndex : 32|4@1+ (1,0) [0|15] "" Vector__XXX
 SG_ UI_driverProfileSelectionType : 36|2@1+ (1,0) [0|3] "" Vector__XXX
 SG_ UI_driverProfilePositionAdjusted : 38|1@1+ (1,0) [0|1] "" Vector__XXX
 SG_ UI_activeKeyRequested : 39|1@1+ (1,0) [0|1] "" Vector__XXX

BO_ 984 UI_elevationStatus: 4 GTW
 SG_ UI_elevation : 0|14@1- (1,0) [-8192|8190] "m" Vector__XXX
 SG_ UI_navElevation : 16|14@1- (1,0) [-8192|8190] "m" Vector__XXX

BO_ 1139 UI_ethNm: 8 GTW
 SG_ UI_nmGoingToSleep : 0|1@1+ (1,0) [0|1] "" Vector__XXX
 SG_ UI_nmKeepAwakeReason : 16|5@1+ (1,0) [1|31] "" Vector__XXX
 SG_ UI_wakeupTime : 32|32@1+ (1,0) [0|4294967295] "" Vector__XXX

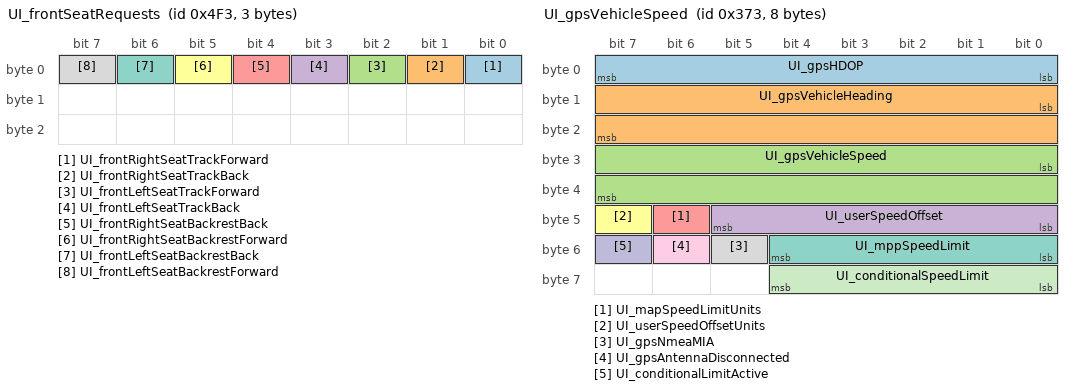
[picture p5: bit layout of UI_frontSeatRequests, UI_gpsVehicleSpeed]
BO_ 1267 UI_frontSeatRequests: 3 GTW
 SG_ UI_frontRightSeatTrackForward : 0|1@1+ (1,0) [0|1] "" Vector__XXX
 SG_ UI_frontRightSeatTrackBack : 1|1@1+ (1,0) [0|1] "" Vector__XXX
 SG_ UI_frontLeftSeatTrackForward : 2|1@1+ (1,0) [0|1] "" Vector__XXX
 SG_ UI_frontLeftSeatTrackBack : 3|1@1+ (1,0) [0|1] "" Vector__XXX
 SG_ UI_frontRightSeatBackrestBack : 4|1@1+ (1,0) [0|1] "" Vector__XXX
 SG_ UI_frontRightSeatBackrestForward : 5|1@1+ (1,0) [0|1] "" Vector__XXX
 SG_ UI_frontLeftSeatBackrestBack : 6|1@1+ (1,0) [0|1] "" Vector__XXX
 SG_ UI_frontLeftSeatBackrestForward : 7|1@1+ (1,0) [0|1] "" Vector__XXX

BO_ 804 UI_gpsTime: 8 GTW
 SG_ UI_gpsTime : 0|64@1+ (1,0) [0|1.84467440737e+19] "" Vector__XXX

BO_ 883 UI_gpsVehicleSpeed: 8 GTW
 SG_ UI_gpsHDOP : 0|8@1+ (0.1,0) [0|25.5] "1" Vector__XXX
 SG_ UI_gpsVehicleHeading : 8|16@1+ (0.0078125,0) [0|511.9921875] "deg" Vector__XXX
 SG_ UI_gpsVehicleSpeed : 24|16@1+ (0.00390625,0) [0|255.99609375] "km/hr" Vector__XXX
 SG_ UI_userSpeedOffset : 40|6@1+ (1,-30) [-30|33] "kph/mph" Vector__XXX
 SG_ UI_mapSpeedLimitUnits : 46|1@1+ (1,0) [0|1] "" Vector__XXX
 SG_ UI_userSpeedOffsetUnits : 47|1@1+ (1,0) [0|1] "" Vector__XXX
 SG_ UI_mppSpeedLimit : 48|5@1+ (5,0) [0|155] "kph/mph" Vector__XXX
 SG_ UI_gpsNmeaMIA : 53|1@1+ (1,0) [0|1] "" Vector__XXX
 SG_ UI_gpsAntennaDisconnected : 54|1@1+ (1,0) [0|1] "" Vector__XXX
 SG_ UI_conditionalLimitActive : 55|1@1+ (1,0) [0|1] "" Vector__XXX
 SG_ UI_conditionalSpeedLimit : 56|5@1+ (5,0) [0|150] "kph/mph" Vector__XXX

BO_ 755 UI_hvacRequest: 8 GTW
 SG_ UI_hvacReqTempSetpointLeft : 0|5@1+ (0.5,15) [15|28] "degC" Vector__XXX
 SG_ UI_hvacReqAutoBlowerLevel : 5|3@1+ (1,0) [0|7] "" Vector__XXX
 SG_ UI_hvacReqTempSetpointRight : 8|5@1+ (0.5,15) [15|28] "degC" Vector__XXX
 SG_ UI_hvacReqAirDistributionMode : 13|3@1+ (1,0) [0|7] "" Vector__XXX
 SG_ UI_hvacReqBlowerSegment : 16|4@1+ (1,0) [0|15] "" Vector__XXX
 SG_ UI_hvacReqRecirc : 20|2@1+ (1,0) [0|3] "" Vector__XXX
 SG_ UI_hvacReqACDisable : 22|2@1+ (1,0) [0|3] "" Vector__XXX
 SG_ UI_hvacDefogState : 24|2@1+ (1,0) [0|3] "" Vector__XXX
 SG_ UI_hvacReqUserPowerState : 26|3@1+ (1,0) [0|7] "" Vector__XXX
 SG_ UI_hvacReqSecondRowState : 29|3@1+ (1,0) [0|7] "" Vector__XXX
 SG_ UI_hvacUseModeledDuctTemp : 32|1@1+ (1,0) [0|1] "" Vector__XXX
 SG_ UI_hvacReqKeepClimateOn : 33|2@1+ (1,0) [0|3] "" Vector__XXX
 SG_ UI_hvacReqBioWeaponDefMode : 35|1@1+ (1,0) [0|1] "" Vector__XXX
 SG_ UI_hvacLatchPassengerPresent : 39|1@1+ (1,0) [0|1] "" Vector__XXX
 SG_ UI_enableHvacControlsFeatures1 : 44|1@1+ (1,0) [0|1] "" Vector__XXX
 SG_ UI_enableHvacNotifications : 45|1@1+ (1,0) [0|1] "" Vector__XXX
 SG_ UI_hvacPhoneCallAirFlowAdjustEna : 46|1@1+ (1,0) [0|1] "" Vector__XXX
 SG_ UI_enableHvacVOCPurgeRoutine : 47|1@1+ (1,0) [0|1] "" Vector__XXX
 SG_ UI_enableCustomerTHSAlerts : 53|1@1+ (1,0) [0|1] "" Vector__XXX
 SG_ UI_evapDryingSelectiveEnable : 54|1@1+ (1,0) [0|1] "" Vector__XXX
 SG_ UI_enableHvacWeatherDataBasedHum : 55|1@1+ (1,0) [0|1] "" Vector__XXX
 SG_ UI_hvacReqTempSetpointCOP : 56|2@1+ (1,0) [0|3] "" Vector__XXX
 SG_ UI_hvacClimateNudgeStatus : 58|3@1+ (1,0) [0|7] "" Vector__XXX
 SG_ UI_enableHvacControlsFeatures2 : 61|1@1+ (1,0) [0|1] "" Vector__XXX
 SG_ UI_enableHvacAPFoggingMonitor : 62|1@1+ (1,0) [0|1] "" Vector__XXX
 SG_ UI_enableHvacLimpMode : 63|1@1+ (1,0) [0|1] "" Vector__XXX

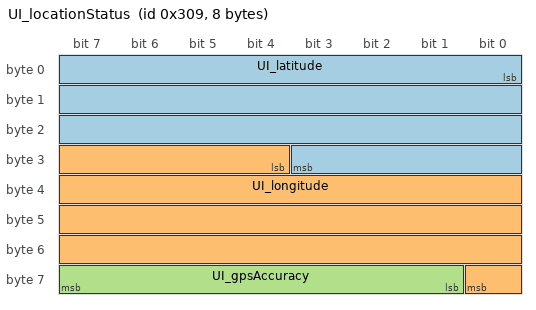
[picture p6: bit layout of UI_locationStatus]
BO_ 777 UI_locationStatus: 8 GTW
 SG_ UI_latitude : 0|28@1- (1.0e-06,0) [-134.217728|134.217727] "deg" Vector__XXX
 SG_ UI_longitude : 28|29@1- (1.0e-06,0) [-268.435456|268.435455] "deg" Vector__XXX
 SG_ UI_gpsAccuracy : 57|7@1+ (0.2,0) [0|25.2] "m" Vector__XXX

BO_TX_BU_ 1291 : TAS;
BO_TX_BU_ 852 : TAS;
BO_TX_BU_ 523 : TAS;
BO_TX_BU_ 1398 : TAS;
BO_TX_BU_ 1357 : TAS;
BO_TX_BU_ 525 : TAS;
BO_TX_BU_ 409 : TAS;
BO_TX_BU_ 410 : TAS;
BO_TX_BU_ 538 : TAS;
BO_TX_BU_ 1154 : GTW;
BO_TX_BU_ 1153 : GTW;
BO_TX_BU_ 1657 : GTW;
BO_TX_BU_ 1021 : GTW;
BO_TX_BU_ 819 : GTW;
BO_TX_BU_ 659 : GTW;
BO_TX_BU_ 531 : GTW;
BO_TX_BU_ 1280 : GTW;
BO_TX_BU_ 2043 : GTW;
BO_TX_BU_ 568 : GTW;
BO_TX_BU_ 645 : GTW;
BO_TX_BU_ 651 : GTW;
BO_TX_BU_ 984 : GTW;
BO_TX_BU_ 1139 : GTW;
BO_TX_BU_ 1267 : GTW;
BO_TX_BU_ 804 : GTW;
BO_TX_BU_ 883 : GTW;
BO_TX_BU_ 755 : GTW;
BO_TX_BU_ 777 : GTW;
CM_ BO_ 1291 "Air suspension controller message: alert log";
CM_ SG_ 1291 TAS_alertID "Air suspension controller: alert ID";
CM_ SG_ 1291 TAS_alertState "Air suspension controller: alert state";
CM_ SG_ 1291 TAS_a001_InternalWatchdog "Air suspension controller: a001 internal watchdog";
CM_ SG_ 1291 TAS_a002_CPUUndervoltage "Air suspension controller: a002 CPU undervoltage";
CM_ SG_ 1291 TAS_a002_PowerOnReset "Air suspension controller: a002 power on reset";
CM_ SG_ 1291 TAS_a003_AssertID "Air suspension controller: a003 assert ID";
CM_ SG_ 1291 TAS_a003_LineNumber "Air suspension controller: a003 line number";
CM_ SG_ 1291 TAS_a003_Data "Air suspension controller: a003 data";
CM_ SG_ 1291 TAS_a012_ClockError "Air suspension controller: a012 clock error";
CM_ SG_ 1291 TAS_a012_FlashError "Air suspension controller: a012 flash error";
CM_ SG_ 1291 TAS_a012_SoftwareReset "Air suspension controller: a012 software reset";
CM_ SG_ 1291 TAS_a012_CheckstopReset "Air suspension controller: a012 checkstop reset";
CM_ SG_ 1291 TAS_a012_DebugReset "Air suspension controller: a012 debug reset";
CM_ SG_ 1291 TAS_a012_ExternalReset "Air suspension controller: a012 external reset";
CM_ SG_ 1291 TAS_a021_Task1msLate "Air suspension controller: a021 task1ms late";
CM_ SG_ 1291 TAS_a021_Task1msStarved "Air suspension controller: a021 task1ms starved";
CM_ SG_ 1291 TAS_a021_Task1msMissed "Air suspension controller: a021 task1ms missed";
CM_ SG_ 1291 TAS_a021_Task10msLate "Air suspension controller: a021 task10ms late";
CM_ SG_ 1291 TAS_a021_Task10msStarved "Air suspension controller: a021 task10ms starved";
CM_ SG_ 1291 TAS_a021_Task10msMissed "Air suspension controller: a021 task10ms missed";
CM_ SG_ 1291 TAS_a021_Task100msLate "Air suspension controller: a021 task100ms late";
CM_ SG_ 1291 TAS_a021_Task100msStarved "Air suspension controller: a021 task100ms starved";
CM_ SG_ 1291 TAS_a021_Task100msMissed "Air suspension controller: a021 task100ms missed";
CM_ SG_ 1291 TAS_a021_Task1000msLate "Air suspension controller: a021 task1000ms late";
CM_ SG_ 1291 TAS_a021_Task1000msStarved "Air suspension controller: a021 task1000ms starved";
CM_ SG_ 1291 TAS_a021_Task1000msMissed "Air suspension controller: a021 task1000ms missed";
CM_ SG_ 1291 TAS_a022_TaskInitErrorCount "Air suspension controller: a022 task init error count";
CM_ SG_ 1291 TAS_a022_TaskInitError0 "Air suspension controller: a022 task init error0";
CM_ SG_ 1291 TAS_a022_TaskInitError1 "Air suspension controller: a022 task init error1";
CM_ SG_ 1291 TAS_a022_TaskInitError2 "Air suspension controller: a022 task init error2";
CM_ SG_ 1291 TAS_a022_TaskInitError3 "Air suspension controller: a022 task init error3";
CM_ SG_ 1291 TAS_a022_TaskInitError4 "Air suspension controller: a022 task init error4";
CM_ SG_ 1291 TAS_a025_vehicleLockAtCrash "Air suspension controller: a025 vehicle lock at crash";
CM_ SG_ 1291 TAS_a025_CANCrashIsActive "Air suspension controller: a025 CAN crash is active";
CM_ SG_ 1291 TAS_a025_appCrashIsActive "Air suspension controller: a025 app crash is active";
CM_ SG_ 1291 TAS_a025_lastCrashEvent "Air suspension controller: a025 last crash event";
CM_ SG_ 1291 TAS_a030_PWMdutyCycleFL "Air suspension controller: a030 PW mduty cycle FL";
CM_ SG_ 1291 TAS_a030_PWMfrequencyFL "Air suspension controller: a030 PW mfrequency FL";
CM_ SG_ 1291 TAS_a030_PWMfaultFL "Air suspension controller: a030 PW mfault FL";
CM_ SG_ 1291 TAS_a031_PWMdutyCycleFR "Air suspension controller: a031 PW mduty cycle FR";
CM_ SG_ 1291 TAS_a031_PWMfrequencyFR "Air suspension controller: a031 PW mfrequency FR";
CM_ SG_ 1291 TAS_a031_PWMfaultFR "Air suspension controller: a031 PW mfault FR";
CM_ SG_ 1291 TAS_a032_PWMdutyCycleRL "Air suspension controller: a032 PW mduty cycle RL";
CM_ SG_ 1291 TAS_a032_PWMfrequencyRL "Air suspension controller: a032 PW mfrequency RL";
CM_ SG_ 1291 TAS_a032_PWMfaultRL "Air suspension controller: a032 PW mfault RL";
CM_ SG_ 1291 TAS_a033_PWMdutyCycleRR "Air suspension controller: a033 PW mduty cycle RR";
CM_ SG_ 1291 TAS_a033_PWMfrequencyRR "Air suspension controller: a033 PW mfrequency RR";
CM_ SG_ 1291 TAS_a033_PWMfaultRR "Air suspension controller: a033 PW mfault RR";
CM_ SG_ 1291 TAS_a034_PWMdutyCycleFL "Air suspension controller: a034 PW mduty cycle FL";
CM_ SG_ 1291 TAS_a034_PWMfrequencyFL "Air suspension controller: a034 PW mfrequency FL";
CM_ SG_ 1291 TAS_a034_PWMfaultFL "Air suspension controller: a034 PW mfault FL";
CM_ SG_ 1291 TAS_a035_PWMdutyCycleFR "Air suspension controller: a035 PW mduty cycle FR";
CM_ SG_ 1291 TAS_a035_PWMfrequencyFR "Air suspension controller: a035 PW mfrequency FR";
CM_ SG_ 1291 TAS_a035_PWMfaultFR "Air suspension controller: a035 PW mfault FR";
CM_ SG_ 1291 TAS_a036_PWMdutyCycleRL "Air suspension controller: a036 PW mduty cycle RL";
CM_ SG_ 1291 TAS_a036_PWMfrequencyRL "Air suspension controller: a036 PW mfrequency RL";
CM_ SG_ 1291 TAS_a036_PWMfaultRL "Air suspension controller: a036 PW mfault RL";
CM_ SG_ 1291 TAS_a037_PWMdutyCycleRR "Air suspension controller: a037 PW mduty cycle RR";
CM_ SG_ 1291 TAS_a037_PWMfrequencyRR "Air suspension controller: a037 PW mfrequency RR";
CM_ SG_ 1291 TAS_a037_PWMfaultRR "Air suspension controller: a037 PW mfault RR";
CM_ SG_ 1291 TAS_a038_PWMdutyCycleFL "Air suspension controller: a038 PW mduty cycle FL";
CM_ SG_ 1291 TAS_a038_PWMfrequencyFL "Air suspension controller: a038 PW mfrequency FL";
CM_ SG_ 1291 TAS_a038_PWMfaultFL "Air suspension controller: a038 PW mfault FL";
CM_ SG_ 1291 TAS_a039_PWMdutyCycleFR "Air suspension controller: a039 PW mduty cycle FR";
CM_ SG_ 1291 TAS_a039_PWMfrequencyFR "Air suspension controller: a039 PW mfrequency FR";
CM_ SG_ 1291 TAS_a039_PWMfaultFR "Air suspension controller: a039 PW mfault FR";
CM_ SG_ 1291 TAS_a040_PWMdutyCycleRL "Air suspension controller: a040 PW mduty cycle RL";
CM_ SG_ 1291 TAS_a040_PWMfrequencyRL "Air suspension controller: a040 PW mfrequency RL";
CM_ SG_ 1291 TAS_a040_PWMfaultRL "Air suspension controller: a040 PW mfault RL";
CM_ SG_ 1291 TAS_a041_PWMdutyCycleRR "Air suspension controller: a041 PW mduty cycle RR";
CM_ SG_ 1291 TAS_a041_PWMfrequencyRR "Air suspension controller: a041 PW mfrequency RR";
CM_ SG_ 1291 TAS_a041_PWMfaultRR "Air suspension controller: a041 PW mfault RR";
CM_ SG_ 1291 TAS_a070_voltage12V "Air suspension controller: a070 voltage12 v";
CM_ SG_ 1291 TAS_a071_voltage12V "Air suspension controller: a071 voltage12 v";
CM_ SG_ 1291 TAS_a072_voltage5VOnBoard "Air suspension controller: a072 voltage5 v on board";
CM_ SG_ 1291 TAS_a073_voltage5VOnBoard "Air suspension controller: a073 voltage5 v on board";
CM_ SG_ 1291 TAS_a074_voltage5VOffBoard "Air suspension controller: a074 voltage5 v off board";
CM_ SG_ 1291 TAS_a075_voltage5VOffBoard "Air suspension controller: a075 voltage5 v off board";
CM_ SG_ 1291 TAS_a076_voltage5VOffBoard "Air suspension controller: a076 voltage5 v off board";
CM_ SG_ 1291 TAS_a077_sensorVoltage "Air suspension controller: a077 sensor voltage";
CM_ SG_ 1291 TAS_a077_sensorRefVoltage "Air suspension controller: a077 sensor ref voltage";
CM_ SG_ 1291 TAS_a078_sensorVoltage "Air suspension controller: a078 sensor voltage";
CM_ SG_ 1291 TAS_a078_sensorRefVoltage "Air suspension controller: a078 sensor ref voltage";
CM_ SG_ 1291 TAS_a080_voltage5VHeight "Air suspension controller: a080 voltage5 v height";
CM_ SG_ 1291 TAS_a081_voltage5VHeight "Air suspension controller: a081 voltage5 v height";
CM_ SG_ 1291 TAS_a082_voltage5VHeight "Air suspension controller: a082 voltage5 v height";
CM_ SG_ 1291 TAS_a083_voltage5VAnalog "Air suspension controller: a083 voltage5 v analog";
CM_ SG_ 1291 TAS_a084_voltage5VAnalog "Air suspension controller: a084 voltage5 v analog";
CM_ SG_ 1291 TAS_a085_voltage5VAnalog "Air suspension controller: a085 voltage5 v analog";
CM_ SG_ 1291 TAS_a086_voltage12VSwitched "Air suspension controller: a086 voltage12 v switched";
CM_ SG_ 1291 TAS_a087_voltage12VSwitched "Air suspension controller: a087 voltage12 v switched";
CM_ SG_ 1291 TAS_a093_readError "Air suspension controller: a093 read error";
CM_ SG_ 1291 TAS_a093_IVOR2Exception "Air suspension controller: a093 IVOR2 exception";
CM_ SG_ 1291 TAS_a098_VCFRONT_LVPowerState_MI "Air suspension controller: a098 VCFRONT LV power state MIA";
CM_ SG_ 1291 TAS_a098_VCFRONT_sensors_MIA "Air suspension controller: a098 VCFRONT sensors MIA";
CM_ SG_ 1291 TAS_a098_VCFRONT_status_MIA "Air suspension controller: a098 VCFRONT status MIA";
CM_ SG_ 1291 TAS_a098_VCFRONT_systemStatus_MI "Air suspension controller: a098 VCFRONT system status MIA";
CM_ SG_ 1291 TAS_a098_VCFRONT_vehNm_MIA "Air suspension controller: a098 VCFRONT veh nm MIA";
CM_ SG_ 1291 TAS_a099_UI_chassisControl_MIA "Air suspension controller: a099 UI chassis control MIA";
CM_ SG_ 1291 TAS_a099_UI_driverAssistMapData_ "Air suspension controller: a099 UI driver assist map data MIA";
CM_ SG_ 1291 TAS_a099_UI_suspensionControl_MI "Air suspension controller: a099 UI suspension control MIA";
CM_ SG_ 1291 TAS_a099_UI_vehicleModes_MIA "Air suspension controller: a099 UI vehicle modes MIA";
CM_ SG_ 1291 TAS_a100_RCM_inertial1_MIA "Air suspension controller: a100 RCM inertial1 MIA";
CM_ SG_ 1291 TAS_a100_RCM_inertial2_MIA "Air suspension controller: a100 RCM inertial2 MIA";
CM_ SG_ 1291 TAS_a101_ESP_brakeTorque_MIA "Air suspension controller: a101 ESP brake torque MIA";
CM_ SG_ 1291 TAS_a101_ESP_status_MIA "Air suspension controller: a101 ESP status MIA";
CM_ SG_ 1291 TAS_a101_ESP_wheelRotation_MIA "Air suspension controller: a101 ESP wheel rotation MIA";
CM_ SG_ 1291 TAS_a102_DI_chassisControl_MIA "Air suspension controller: a102 DI chassis control MIA";
CM_ SG_ 1291 TAS_a102_DI_locStatus_MIA "Air suspension controller: a102 DI loc status MIA";
CM_ SG_ 1291 TAS_a102_DI_speed_MIA "Air suspension controller: a102 DI speed MIA";
CM_ SG_ 1291 TAS_a102_DI_systemStatus_MIA "Air suspension controller: a102 DI system status MIA";
CM_ SG_ 1291 TAS_a102_DI_vehicleEstimates_MIA "Air suspension controller: a102 DI vehicle estimates MIA";
CM_ SG_ 1291 TAS_a102_DIF_torque_MIA "Air suspension controller: a102 DIF torque MIA";
CM_ SG_ 1291 TAS_a102_DIR_torque_MIA "Air suspension controller: a102 DIR torque MIA";
CM_ SG_ 1291 TAS_a103_GTW_carConfig_MIA "Air suspension controller: a103 GTW car config MIA";
CM_ SG_ 1291 TAS_a103_GTW_time_MIA "Air suspension controller: a103 GTW time MIA";
CM_ SG_ 1291 TAS_a103_GTW_vehNm_MIA "Air suspension controller: a103 GTW veh nm MIA";
CM_ SG_ 1291 TAS_a103_GTW_vin_MIA "Air suspension controller: a103 GTW vin MIA";
CM_ SG_ 1291 TAS_a164_detectedDamperSolenoid "Air suspension controller: a164 detected damper solenoid";
CM_ SG_ 1291 TAS_a164_expectedDamperSolenoid "Air suspension controller: a164 expected damper solenoid";
CM_ SG_ 1291 TAS_a165_damperValveFault "Air suspension controller: a165 damper valve fault";
CM_ SG_ 1291 TAS_a166_damperValveFault "Air suspension controller: a166 damper valve fault";
CM_ SG_ 1291 TAS_a167_damperValveFault "Air suspension controller: a167 damper valve fault";
CM_ SG_ 1291 TAS_a168_damperValveFault "Air suspension controller: a168 damper valve fault";
CM_ SG_ 1291 TAS_a169_damperValveFault "Air suspension controller: a169 damper valve fault";
CM_ SG_ 1291 TAS_a170_damperValveFault "Air suspension controller: a170 damper valve fault";
CM_ SG_ 1291 TAS_a171_damperValveFault "Air suspension controller: a171 damper valve fault";
CM_ SG_ 1291 TAS_a172_damperValveFault "Air suspension controller: a172 damper valve fault";
CM_ SG_ 1291 TAS_a173_heightDelta_mm "Air suspension controller: a173 height delta mm";
CM_ SG_ 1291 TAS_a174_heightDelta_mm "Air suspension controller: a174 height delta mm";
CM_ SG_ 1291 TAS_a175_heightDelta_mm "Air suspension controller: a175 height delta mm";
CM_ SG_ 1291 TAS_a176_heightDelta_mm "Air suspension controller: a176 height delta mm";
CM_ SG_ 1291 TAS_a190_a2bFaultType "Air suspension controller: a190 a2b fault type";
CM_ SG_ 1291 TAS_a190_a2bInterruptType "Air suspension controller: a190 a2b interrupt type";
CM_ SG_ 1291 TAS_a190_a2bFaultSource "Air suspension controller: a190 a2b fault source";
CM_ SG_ 1291 TAS_a191_a2bFaultType "Air suspension controller: a191 a2b fault type";
CM_ SG_ 1291 TAS_a191_a2bInterruptType "Air suspension controller: a191 a2b interrupt type";
CM_ SG_ 1291 TAS_a191_a2bFaultSource "Air suspension controller: a191 a2b fault source";
CM_ SG_ 1291 TAS_a192_rideHeightVelDspFL "Air suspension controller: a192 ride height vel dsp FL";
CM_ SG_ 1291 TAS_a192_rideHeightVelDspFR "Air suspension controller: a192 ride height vel dsp FR";
CM_ SG_ 1291 TAS_a192_rideHeightVelDspRL "Air suspension controller: a192 ride height vel dsp RL";
CM_ SG_ 1291 TAS_a192_rideHeightVelDspRR "Air suspension controller: a192 ride height vel dsp RR";
CM_ SG_ 1291 TAS_a192_rideHeightVelObserverFL "Air suspension controller: a192 ride height vel observer FL";
CM_ SG_ 1291 TAS_a192_rideHeightVelObserverFR "Air suspension controller: a192 ride height vel observer FR";
CM_ SG_ 1291 TAS_a192_rideHeightVelObserverRL "Air suspension controller: a192 ride height vel observer RL";
CM_ SG_ 1291 TAS_a192_rideHeightVelObserverRR "Air suspension controller: a192 ride height vel observer RR";
CM_ SG_ 1291 TAS_a192_alertVersion "Air suspension controller: a192 alert version";
CM_ SG_ 1291 TAS_a193_EPAS3P_sysStatus_MIA "Air suspension controller: a193 EPAS3 p sys status MIA";
CM_ SG_ 1291 TAS_a210_heightSensorDeltaFL "Air suspension controller: a210 height sensor delta FL";
CM_ SG_ 1291 TAS_a210_heightSensorDeltaFR "Air suspension controller: a210 height sensor delta FR";
CM_ SG_ 1291 TAS_a210_heightSensorDeltaRL "Air suspension controller: a210 height sensor delta RL";
CM_ SG_ 1291 TAS_a210_heightSensorDeltaRR "Air suspension controller: a210 height sensor delta RR";
CM_ SG_ 1291 TAS_a220_galleryPressure "Air suspension controller: a220 gallery pressure";
CM_ SG_ 1291 TAS_a220_timeInExhaust "Air suspension controller: a220 time in exhaust";
CM_ SG_ 1291 TAS_a221_galleryPressureDelta "Air suspension controller: a221 gallery pressure delta";
CM_ SG_ 1291 TAS_a221_timeInIdle "Air suspension controller: a221 time in idle";
CM_ SG_ 1291 TAS_a222_galleryPressureDelta "Air suspension controller: a222 gallery pressure delta";
CM_ SG_ 1291 TAS_a223_galleryPressure "Air suspension controller: a223 gallery pressure";
CM_ SG_ 1291 TAS_a223_valveOnFL "Air suspension controller: a223 valve on FL";
CM_ SG_ 1291 TAS_a223_valveOnFR "Air suspension controller: a223 valve on FR";
CM_ SG_ 1291 TAS_a223_valveOnRL "Air suspension controller: a223 valve on RL";
CM_ SG_ 1291 TAS_a223_valveOnRR "Air suspension controller: a223 valve on RR";
CM_ SG_ 1291 TAS_a223_valveOnReservoir "Air suspension controller: a223 valve on reservoir";
CM_ SG_ 1291 TAS_a224_galleryPressure "Air suspension controller: a224 gallery pressure";
CM_ SG_ 1291 TAS_a224_valveOnFL "Air suspension controller: a224 valve on FL";
CM_ SG_ 1291 TAS_a224_valveOnFR "Air suspension controller: a224 valve on FR";
CM_ SG_ 1291 TAS_a224_valveOnRL "Air suspension controller: a224 valve on RL";
CM_ SG_ 1291 TAS_a224_valveOnRR "Air suspension controller: a224 valve on RR";
CM_ SG_ 1291 TAS_a224_valveOnReservoir "Air suspension controller: a224 valve on reservoir";
CM_ SG_ 1291 TAS_a225_galleryPressure "Air suspension controller: a225 gallery pressure";
CM_ SG_ 1291 TAS_a226_PWMdutyCycleFL "Air suspension controller: a226 PW mduty cycle FL";
CM_ SG_ 1291 TAS_a226_PWMfrequencyFL "Air suspension controller: a226 PW mfrequency FL";
CM_ SG_ 1291 TAS_a226_PWMfaultFL "Air suspension controller: a226 PW mfault FL";
CM_ SG_ 1291 TAS_a227_PWMdutyCycleFR "Air suspension controller: a227 PW mduty cycle FR";
CM_ SG_ 1291 TAS_a227_PWMfrequencyFR "Air suspension controller: a227 PW mfrequency FR";
CM_ SG_ 1291 TAS_a227_PWMfaultFR "Air suspension controller: a227 PW mfault FR";
CM_ SG_ 1291 TAS_a228_PWMdutyCycleRL "Air suspension controller: a228 PW mduty cycle RL";
CM_ SG_ 1291 TAS_a228_PWMfrequencyRL "Air suspension controller: a228 PW mfrequency RL";
CM_ SG_ 1291 TAS_a228_PWMfaultRL "Air suspension controller: a228 PW mfault RL";
CM_ SG_ 1291 TAS_a229_PWMdutyCycleRR "Air suspension controller: a229 PW mduty cycle RR";
CM_ SG_ 1291 TAS_a229_PWMfrequencyRR "Air suspension controller: a229 PW mfrequency RR";
CM_ SG_ 1291 TAS_a229_PWMfaultRR "Air suspension controller: a229 PW mfault RR";
CM_ SG_ 1291 TAS_a232_detectedSuspensionType "Air suspension controller: a232 detected suspension type";
CM_ SG_ 1291 TAS_a232_expectedSuspensionType "Air suspension controller: a232 expected suspension type";
CM_ SG_ 1291 TAS_a234_detectedDamperHydraulic "Air suspension controller: a234 detected damper hydraulic";
CM_ SG_ 1291 TAS_a234_expectedDamperHydraulic "Air suspension controller: a234 expected damper hydraulic";
CM_ SG_ 1291 TAS_a240_highAdjustCountRatio "Air suspension controller: a240 high adjust count ratio";
CM_ SG_ 1291 TAS_a240_highAdjustTimeRatio "Air suspension controller: a240 high adjust time ratio";
CM_ SG_ 1291 TAS_a240_highCrossPressure "Air suspension controller: a240 high cross pressure";
CM_ SG_ 1291 TAS_a240_highCompExhTimeRatio "Air suspension controller: a240 high comp exh time ratio";
CM_ SG_ 1291 TAS_a240_adjustCountRatioSpring "Air suspension controller: a240 adjust count ratio spring";
CM_ SG_ 1291 TAS_a240_adjustCountRatio "Air suspension controller: a240 adjust count ratio; raw 255 = signal not available (SNA)";
CM_ SG_ 1291 TAS_a240_adjustTimeRatioSpring "Air suspension controller: a240 adjust time ratio spring";
CM_ SG_ 1291 TAS_a240_adjustTimeRatio "Air suspension controller: a240 adjust time ratio; raw 255 = signal not available (SNA)";
CM_ SG_ 1291 TAS_a240_compExhTimeRatio "Air suspension controller: a240 comp exh time ratio";
CM_ SG_ 1291 TAS_a240_crossPressure "Air suspension controller: a240 cross pressure";
CM_ SG_ 1291 TAS_a285_twistLevel "Air suspension controller: a285 twist level";
CM_ SG_ 1291 TAS_a290_twistLevel "Air suspension controller: a290 twist level";
CM_ SG_ 1291 TAS_a291_frontAxleHeight "Air suspension controller: a291 front axle height";
CM_ SG_ 1291 TAS_a292_rearAxleHeight "Air suspension controller: a292 rear axle height";
CM_ SG_ 1291 TAS_a293_frontAxleHeight "Air suspension controller: a293 front axle height";
CM_ SG_ 1291 TAS_a294_rearAxleHeight "Air suspension controller: a294 rear axle height";
CM_ SG_ 1291 TAS_a295_targetHeight "Air suspension controller: a295 target height";
CM_ SG_ 1291 TAS_a296_detectedChassisType "Air suspension controller: a296 detected chassis type";
CM_ SG_ 1291 TAS_a296_expectedChassisType "Air suspension controller: a296 expected chassis type";
CM_ SG_ 1291 TAS_a319_detectedDrivetrainType "Air suspension controller: a319 detected drivetrain type";
CM_ SG_ 1291 TAS_a319_expectedDrivetrainType "Air suspension controller: a319 expected drivetrain type";
CM_ BO_ 852 "Air suspension controller message: alert matrix";
CM_ SG_ 852 TAS_matrixIndex "Air suspension controller: matrix index";
CM_ SG_ 852 TAS_a001_WatchdogReset "Air suspension controller: a001 watchdog reset";
CM_ SG_ 852 TAS_a002_PowerLossReset "Air suspension controller: a002 power loss reset";
CM_ SG_ 852 TAS_a003_SWAssertion "Air suspension controller: a003 SW assertion";
CM_ SG_ 852 TAS_a012_CPUReset "Air suspension controller: a012 CPU reset";
CM_ SG_ 852 TAS_a015_NVMMError "Air suspension controller: a015 NVMM error";
CM_ SG_ 852 TAS_a016_NVMMRecordError "Air suspension controller: a016 NVMM record error";
CM_ SG_ 852 TAS_a021_TaskSchedulerError "Air suspension controller: a021 task scheduler error";
CM_ SG_ 852 TAS_a022_TaskInitError "Air suspension controller: a022 task init error";
CM_ SG_ 852 TAS_a023_rtosResetRequested "Air suspension controller: a023 rtos reset requested";
CM_ SG_ 852 TAS_a024_prefetchAbort "Air suspension controller: a024 prefetch abort";
CM_ SG_ 852 TAS_a025_CrashEvent "Air suspension controller: a025 crash event";
CM_ SG_ 852 TAS_a030_PWMerrorFL "Air suspension controller: a030 PW merror FL";
CM_ SG_ 852 TAS_a031_PWMerrorFR "Air suspension controller: a031 PW merror FR";
CM_ SG_ 852 TAS_a032_PWMerrorRL "Air suspension controller: a032 PW merror RL";
CM_ SG_ 852 TAS_a033_PWMerrorRR "Air suspension controller: a033 PW merror RR";
CM_ SG_ 852 TAS_a034_PWMshortFL "Air suspension controller: a034 PW mshort FL";
CM_ SG_ 852 TAS_a035_PWMshortFR "Air suspension controller: a035 PW mshort FR";
CM_ SG_ 852 TAS_a036_PWMshortRL "Air suspension controller: a036 PW mshort RL";
CM_ SG_ 852 TAS_a037_PWMshortRR "Air suspension controller: a037 PW mshort RR";
CM_ SG_ 852 TAS_a038_PWMopenFL "Air suspension controller: a038 PW mopen FL";
CM_ SG_ 852 TAS_a039_PWMopenFR "Air suspension controller: a039 PW mopen FR";
CM_ SG_ 852 TAS_a040_PWMopenRL "Air suspension controller: a040 PW mopen RL";
CM_ SG_ 852 TAS_a041_PWMopenRR "Air suspension controller: a041 PW mopen RR";
CM_ SG_ 852 TAS_a043_Task1msError "Air suspension controller: a043 task1ms error";
CM_ SG_ 852 TAS_a044_Task10msError "Air suspension controller: a044 task10ms error";
CM_ SG_ 852 TAS_a045_Task100msError "Air suspension controller: a045 task100ms error";
CM_ SG_ 852 TAS_a046_Task1000msError "Air suspension controller: a046 task1000ms error";
CM_ SG_ 852 TAS_a061_XCPConnected "Air suspension controller: a061 XCP connected";
CM_ SG_ 852 TAS_a062_XCPWasConnected "Air suspension controller: a062 XCP was connected";
CM_ SG_ 852 TAS_a063_abortFault "Air suspension controller: a063 abort fault";
CM_ SG_ 852 TAS_a064_abortFaultExt "Air suspension controller: a064 abort fault ext";
CM_ SG_ 852 TAS_a065_ahbWriteFault "Air suspension controller: a065 ahb write fault";
CM_ SG_ 852 TAS_a066_undefinedInstructionAbo "Air suspension controller: a066 undefined instruction abort";
CM_ SG_ 852 TAS_a067_reservedHandlerAbort "Air suspension controller: a067 reserved handler abort";
CM_ SG_ 852 TAS_a070_underVoltage12V "Air suspension controller: a070 under voltage12 v";
CM_ SG_ 852 TAS_a071_overVoltage12V "Air suspension controller: a071 over voltage12 v";
CM_ SG_ 852 TAS_a072_shortCircuit5VOnBoard "Air suspension controller: a072 short circuit5 v on board";
CM_ SG_ 852 TAS_a073_underVoltage5VOnBoard "Air suspension controller: a073 under voltage5 v on board";
CM_ SG_ 852 TAS_a074_shortCircuit5VOffBoard "Air suspension controller: a074 short circuit5 v off board";
CM_ SG_ 852 TAS_a075_underVoltage5VOffBoard "Air suspension controller: a075 under voltage5 v off board";
CM_ SG_ 852 TAS_a076_overVoltage5VOffBoard "Air suspension controller: a076 over voltage5 v off board";
CM_ SG_ 852 TAS_a077_pressureSigVTooLow "Air suspension controller: a077 pressure sig v too low";
CM_ SG_ 852 TAS_a078_pressureSigVTooHigh "Air suspension controller: a078 pressure sig v too high";
CM_ SG_ 852 TAS_a080_shortCircuit5VHeight "Air suspension controller: a080 short circuit5 v height";
CM_ SG_ 852 TAS_a081_underVoltage5VHeight "Air suspension controller: a081 under voltage5 v height";
CM_ SG_ 852 TAS_a082_overVoltage5VHeight "Air suspension controller: a082 over voltage5 v height";
CM_ SG_ 852 TAS_a083_shortCircuit5VAnalog "Air suspension controller: a083 short circuit5 v analog";
CM_ SG_ 852 TAS_a084_underVoltage5VAnalog "Air suspension controller: a084 under voltage5 v analog";
CM_ SG_ 852 TAS_a085_overVoltage5VAnalog "Air suspension controller: a085 over voltage5 v analog";
CM_ SG_ 852 TAS_a086_underVoltage12VSwtchd "Air suspension controller: a086 under voltage12 v swtchd";
CM_ SG_ 852 TAS_a087_overVoltage12VSwtchd "Air suspension controller: a087 over voltage12 v swtchd";
CM_ SG_ 852 TAS_a093_OTPError "Air suspension controller: a093 OTP error";
CM_ SG_ 852 TAS_a098_VCFRONT_MIA "Air suspension controller: a098 VCFRONT MIA";
CM_ SG_ 852 TAS_a099_UI_MIA "Air suspension controller: a099 UI MIA";
CM_ SG_ 852 TAS_a100_RCM_MIA "Air suspension controller: a100 RCM MIA";
CM_ SG_ 852 TAS_a101_ESP_MIA "Air suspension controller: a101 ESP MIA";
CM_ SG_ 852 TAS_a102_DI_MIA "Air suspension controller: a102 DI MIA";
CM_ SG_ 852 TAS_a103_GTW_MIA "Air suspension controller: a103 GTW MIA";
CM_ SG_ 852 TAS_a105_ECUDebugMode "Air suspension controller: a105 ECU debug mode";
CM_ SG_ 852 TAS_a106_HighCPULoad "Air suspension controller: a106 high CPU load";
CM_ SG_ 852 TAS_a107_HighStackUsage "Air suspension controller: a107 high stack usage";
CM_ SG_ 852 TAS_a150_accelAvgImplausible_FL_ "Air suspension controller: a150 accel avg implausible FL x";
CM_ SG_ 852 TAS_a151_accelAvgImplausible_FL_ "Air suspension controller: a151 accel avg implausible FL y";
CM_ SG_ 852 TAS_a152_accelAvgImplausible_FL_ "Air suspension controller: a152 accel avg implausible FL z";
CM_ SG_ 852 TAS_a153_accelAvgImplausible_FR_ "Air suspension controller: a153 accel avg implausible FR x";
CM_ SG_ 852 TAS_a154_accelAvgImplausible_FR_ "Air suspension controller: a154 accel avg implausible FR y";
CM_ SG_ 852 TAS_a155_accelAvgImplausible_FR_ "Air suspension controller: a155 accel avg implausible FR z";
CM_ SG_ 852 TAS_a156_accelAvgImplausible_RL_ "Air suspension controller: a156 accel avg implausible RL x";
CM_ SG_ 852 TAS_a157_accelAvgImplausible_RL_ "Air suspension controller: a157 accel avg implausible RL y";
CM_ SG_ 852 TAS_a158_accelAvgImplausible_RL_ "Air suspension controller: a158 accel avg implausible RL z";
CM_ SG_ 852 TAS_a159_accelAvgImplausible_RR_ "Air suspension controller: a159 accel avg implausible RR x";
CM_ SG_ 852 TAS_a160_accelAvgImplausible_RR_ "Air suspension controller: a160 accel avg implausible RR y";
CM_ SG_ 852 TAS_a161_accelAvgImplausible_RR_ "Air suspension controller: a161 accel avg implausible RR z";
CM_ SG_ 852 TAS_a164_damperSolenoidMismatch "Air suspension controller: a164 damper solenoid mismatch";
CM_ SG_ 852 TAS_a165_damperValveCompFL "Air suspension controller: a165 damper valve comp FL";
CM_ SG_ 852 TAS_a166_damperValveRbndFL "Air suspension controller: a166 damper valve rbnd FL";
CM_ SG_ 852 TAS_a167_damperValveCompFR "Air suspension controller: a167 damper valve comp FR";
CM_ SG_ 852 TAS_a168_damperValveRbndFR "Air suspension controller: a168 damper valve rbnd FR";
CM_ SG_ 852 TAS_a169_damperValveCompRL "Air suspension controller: a169 damper valve comp RL";
CM_ SG_ 852 TAS_a170_damperValveRbndRL "Air suspension controller: a170 damper valve rbnd RL";
CM_ SG_ 852 TAS_a171_damperValveCompRR "Air suspension controller: a171 damper valve comp RR";
CM_ SG_ 852 TAS_a172_damperValveRbndRR "Air suspension controller: a172 damper valve rbnd RR";
CM_ SG_ 852 TAS_a173_staticLeakDetectFL "Air suspension controller: a173 static leak detect FL";
CM_ SG_ 852 TAS_a174_staticLeakDetectFR "Air suspension controller: a174 static leak detect FR";
CM_ SG_ 852 TAS_a175_staticLeakDetectRL "Air suspension controller: a175 static leak detect RL";
CM_ SG_ 852 TAS_a176_staticLeakDetectRR "Air suspension controller: a176 static leak detect RR";
CM_ SG_ 852 TAS_a190_a2bFrontAxleFault "Air suspension controller: a190 a2b front axle fault";
CM_ SG_ 852 TAS_a191_a2bRearAxleFault "Air suspension controller: a191 a2b rear axle fault";
CM_ SG_ 852 TAS_a192_rideHeightObserverDiver "Air suspension controller: a192 ride height observer divergence";
CM_ SG_ 852 TAS_a193_EPAS3P_MIA "Air suspension controller: a193 EPAS3 p MIA";
CM_ SG_ 852 TAS_a194_a2bFrontAxleDataError "Air suspension controller: a194 a2b front axle data error";
CM_ SG_ 852 TAS_a195_a2bRearAxleDataError "Air suspension controller: a195 a2b rear axle data error";
CM_ SG_ 852 TAS_a196_adaptiveDampingUsingDSP "Air suspension controller: a196 adaptive damping using DSP";
CM_ SG_ 852 TAS_a197_invalidAdaptiveModeRequ "Air suspension controller: a197 invalid adaptive mode requested";
CM_ SG_ 852 TAS_a200_jackModeActive "Air suspension controller: a200 jack mode active";
CM_ SG_ 852 TAS_a201_low12VBattery "Air suspension controller: a201 low12 v battery";
CM_ SG_ 852 TAS_a210_outOfRangeCalibration "Air suspension controller: a210 out of range calibration";
CM_ SG_ 852 TAS_a211_noRideHeightCalib "Air suspension controller: a211 no ride height calib";
CM_ SG_ 852 TAS_a213_yellowWarningLamp "Air suspension controller: a213 yellow warning lamp";
CM_ SG_ 852 TAS_a214_redWarningLamp "Air suspension controller: a214 red warning lamp";
CM_ SG_ 852 TAS_a215_limpHomeMode10 "Air suspension controller: a215 limp home mode10";
CM_ SG_ 852 TAS_a216_limpHomeMode20 "Air suspension controller: a216 limp home mode20";
CM_ SG_ 852 TAS_a217_limpHomeMode30 "Air suspension controller: a217 limp home mode30";
CM_ SG_ 852 TAS_a218_limpHomeMode40 "Air suspension controller: a218 limp home mode40";
CM_ SG_ 852 TAS_a220_exhaustGalleryFault "Air suspension controller: a220 exhaust gallery fault";
CM_ SG_ 852 TAS_a221_valveLeakDetected "Air suspension controller: a221 valve leak detected";
CM_ SG_ 852 TAS_a222_compressorPrefillFault "Air suspension controller: a222 compressor prefill fault";
CM_ SG_ 852 TAS_a223_blockedAirline "Air suspension controller: a223 blocked airline";
CM_ SG_ 852 TAS_a224_openAirline "Air suspension controller: a224 open airline";
CM_ SG_ 852 TAS_a225_galleryPressureTooHigh "Air suspension controller: a225 gallery pressure too high";
CM_ SG_ 852 TAS_a226_PWMfastDetectFL "Air suspension controller: a226 PW mfast detect FL";
CM_ SG_ 852 TAS_a227_PWMfastDetectFR "Air suspension controller: a227 PW mfast detect FR";
CM_ SG_ 852 TAS_a228_PWMfastDetectRL "Air suspension controller: a228 PW mfast detect RL";
CM_ SG_ 852 TAS_a229_PWMfastDetectRR "Air suspension controller: a229 PW mfast detect RR";
CM_ SG_ 852 TAS_a230_notifyGeofence "Air suspension controller: a230 notify geofence";
CM_ SG_ 852 TAS_a231_notifyRoughRoadRaise "Air suspension controller: a231 notify rough road raise";
CM_ SG_ 852 TAS_a232_suspensionTypeMismatch "Air suspension controller: a232 suspension type mismatch";
CM_ SG_ 852 TAS_a233_compressorStuckOn "Air suspension controller: a233 compressor stuck on";
CM_ SG_ 852 TAS_a234_damperHydraulicMismatch "Air suspension controller: a234 damper hydraulic mismatch";
CM_ SG_ 852 TAS_a240_airSpringLeak "Air suspension controller: a240 air spring leak";
CM_ SG_ 852 TAS_a284_serviceRunModeActive "Air suspension controller: a284 service run mode active";
CM_ SG_ 852 TAS_a285_twistSustainedUserVis "Air suspension controller: a285 twist sustained user vis";
CM_ SG_ 852 TAS_a286_driveCycleStats1 "Air suspension controller: a286 drive cycle stats1";
CM_ SG_ 852 TAS_a287_driveCycleStats2 "Air suspension controller: a287 drive cycle stats2";
CM_ SG_ 852 TAS_a288_driveCycleStats3 "Air suspension controller: a288 drive cycle stats3";
CM_ SG_ 852 TAS_a289_driveCycleStats4 "Air suspension controller: a289 drive cycle stats4";
CM_ SG_ 852 TAS_a290_twistSustainedAtSpeed "Air suspension controller: a290 twist sustained at speed";
CM_ SG_ 852 TAS_a291_frontAxleTooHigh "Air suspension controller: a291 front axle too high";
CM_ SG_ 852 TAS_a292_rearAxleTooHigh "Air suspension controller: a292 rear axle too high";
CM_ SG_ 852 TAS_a293_frontAxleTooLow "Air suspension controller: a293 front axle too low";
CM_ SG_ 852 TAS_a294_rearAxleTooLow "Air suspension controller: a294 rear axle too low";
CM_ SG_ 852 TAS_a295_targetHeightNotMet "Air suspension controller: a295 target height not met";
CM_ SG_ 852 TAS_a296_chassisTypeMismatch "Air suspension controller: a296 chassis type mismatch";
CM_ SG_ 852 TAS_a297_vinMismatch "Air suspension controller: a297 vin mismatch";
CM_ SG_ 852 TAS_a298_vinNotLearned "Air suspension controller: a298 vin not learned";
CM_ SG_ 852 TAS_a299_offsetEstimateTooLarge "Air suspension controller: a299 offset estimate too large";
CM_ SG_ 852 TAS_a300_offsetEstimateData1 "Air suspension controller: a300 offset estimate data1";
CM_ SG_ 852 TAS_a301_offsetEstimateData2 "Air suspension controller: a301 offset estimate data2";
CM_ SG_ 852 TAS_a303_massEstimateFrozen "Air suspension controller: a303 mass estimate frozen";
CM_ SG_ 852 TAS_a304_massEstimateFrozenData "Air suspension controller: a304 mass estimate frozen data";
CM_ SG_ 852 TAS_a305_newEndstopPosition "Air suspension controller: a305 new endstop position";
CM_ SG_ 852 TAS_a306_hardwareProtectFrozen "Air suspension controller: a306 hardware protect frozen";
CM_ SG_ 852 TAS_a307_endstopBoundaryComp "Air suspension controller: a307 endstop boundary comp";
CM_ SG_ 852 TAS_a308_endstopBoundaryRbnd "Air suspension controller: a308 endstop boundary rbnd";
CM_ SG_ 852 TAS_a309_controlFrozen "Air suspension controller: a309 control frozen";
CM_ SG_ 852 TAS_a310_controlFrozenData "Air suspension controller: a310 control frozen data";
CM_ SG_ 852 TAS_a311_accelsMIA "Air suspension controller: a311 accels MIA";
CM_ SG_ 852 TAS_a312_rotationalRatesMIA "Air suspension controller: a312 rotational rates MIA";
CM_ SG_ 852 TAS_a313_dampingCntrlDisabled "Air suspension controller: a313 damping cntrl disabled";
CM_ SG_ 852 TAS_a314_dampingReduced "Air suspension controller: a314 damping reduced";
CM_ SG_ 852 TAS_a315_pcbaHighTemp "Air suspension controller: a315 pcba high temp";
CM_ SG_ 852 TAS_a316_offsetsAccels "Air suspension controller: a316 offsets accels";
CM_ SG_ 852 TAS_a317_offsetsRotationalRates "Air suspension controller: a317 offsets rotational rates";
CM_ SG_ 852 TAS_a318_dampingCntrlInputMIA "Air suspension controller: a318 damping cntrl input MIA";
CM_ SG_ 852 TAS_a319_drivetrainTypeMismatch "Air suspension controller: a319 drivetrain type mismatch";
CM_ SG_ 852 TAS_a320_offsetsRotationalRates "Air suspension controller: a320 offsets rotational rates";
CM_ SG_ 852 TAS_a321_speedBumpAttributes1 "Air suspension controller: a321 speed bump attributes1";
CM_ SG_ 852 TAS_a322_speedBumpAttributes2 "Air suspension controller: a322 speed bump attributes2";
CM_ SG_ 852 TAS_a332_levelingThresholds1 "Air suspension controller: a332 leveling thresholds1";
CM_ SG_ 852 TAS_a333_levelingThresholds2 "Air suspension controller: a333 leveling thresholds2";
CM_ BO_ 523 "Air suspension controller message: axle data";
CM_ SG_ 523 TAS_axleIndex "Air suspension controller: axle index";
CM_ SG_ 523 TAS_rawHeightFL "Current height of the FL air spring.; raw 1023 = signal not available (SNA)";
CM_ SG_ 523 TAS_staticHeightEstimateFL "Current static height estimate of the FL air spring.; raw 1023 = signal not available (SNA)";
CM_ SG_ 523 TAS_componentPressureFL "Current static pressure of the FL air spring.; raw 255 = signal not available (SNA)";
CM_ SG_ 523 TAS_rawHeightFR "Current height of the FR air spring.; raw 1023 = signal not available (SNA)";
CM_ SG_ 523 TAS_staticHeightEstimateFR "Current static height estimate of the FR air spring.; raw 1023 = signal not available (SNA)";
CM_ SG_ 523 TAS_componentPressureFR "Current static pressure of the FR air spring.; raw 255 = signal not available (SNA)";
CM_ SG_ 523 TAS_rawHeightRL "Current height of the RL air spring.; raw 1023 = signal not available (SNA)";
CM_ SG_ 523 TAS_staticHeightEstimateRL "Current static height estimate of the RL air spring.; raw 1023 = signal not available (SNA)";
CM_ SG_ 523 TAS_componentPressureRL "Current static pressure of the RL air spring.; raw 255 = signal not available (SNA)";
CM_ SG_ 523 TAS_rawHeightRR "Current height of the RR air spring.; raw 1023 = signal not available (SNA)";
CM_ SG_ 523 TAS_staticHeightEstimateRR "Current static height estimate of the RR air spring.; raw 1023 = signal not available (SNA)";
CM_ SG_ 523 TAS_componentPressureRR "Current static pressure of the RR air spring.; raw 255 = signal not available (SNA)";
CM_ BO_ 1398 "Air suspension controller message: damping states";
CM_ SG_ 1398 TAS_endstopState "Air suspension controller: endstop state";
CM_ SG_ 1398 TAS_continuousControlState "SW-237496";
CM_ SG_ 1398 TAS_activeTireTune "Air suspension controller: active tire tune";
CM_ SG_ 1398 TAS_roughnessRaiseReason "Air suspension controller: roughness raise reason";
CM_ SG_ 1398 TAS_frontMetricDrivesRear "Air suspension controller: front metric drives rear";
CM_ SG_ 1398 TAS_roadCondition "Air suspension controller: road condition; raw 255 = signal not available (SNA)";
CM_ SG_ 1398 TAS_bellyProtect "Air suspension controller: belly protect";
CM_ SG_ 1398 TAS_frontMetricDrivesFront "Air suspension controller: front metric drives front";
CM_ SG_ 1398 TAS_speedBumpAxleFront "Air suspension controller: speed bump axle front";
CM_ SG_ 1398 TAS_speedBumpAxleRear "Air suspension controller: speed bump axle rear";
CM_ SG_ 1398 TAS_holeProtectFL "Air suspension controller: hole protect FL";
CM_ SG_ 1398 TAS_holeProtectFR "Air suspension controller: hole protect FR";
CM_ SG_ 1398 TAS_holeProtectRL "Air suspension controller: hole protect RL";
CM_ SG_ 1398 TAS_holeProtectRR "Air suspension controller: hole protect RR";
CM_ SG_ 1398 TAS_stepProtectFL "Air suspension controller: step protect FL";
CM_ SG_ 1398 TAS_stepProtectFR "Air suspension controller: step protect FR";
CM_ SG_ 1398 TAS_stepProtectRL "Air suspension controller: step protect RL";
CM_ SG_ 1398 TAS_stepProtectRR "Air suspension controller: step protect RR";
CM_ SG_ 1398 TAS_FDUTorqueCorruptionScale "Air suspension controller: FDU torque corruption scale; raw 15 = signal not available (SNA)";
CM_ SG_ 1398 TAS_sprungMassEstimate "Air suspension controller: sprung mass estimate; raw 31 = signal not available (SNA)";
CM_ SG_ 1398 TAS_anyDamperActive "Air suspension controller: any damper active";
CM_ SG_ 1398 TAS_dampingStatesCounter "Air suspension controller: damping states counter";
CM_ SG_ 1398 TAS_dampingStatesChecksum "Air suspension controller: damping states checksum";
CM_ BO_ 1357 "Air suspension controller message: info";
CM_ SG_ 1357 TAS_infoIndex "Air suspension controller: info index";
CM_ SG_ 1357 TAS_infoBuildType "Air suspension controller: info build type";
CM_ SG_ 1357 TAS_infoBuildConfigId "Air suspension controller: info build config id";
CM_ SG_ 1357 TAS_infoHardwareId "Air suspension controller: info hardware id";
CM_ SG_ 1357 TAS_infoComponentId "Air suspension controller: info component id";
CM_ SG_ 1357 TAS_infoPcbaId "Air suspension controller: info pcba id";
CM_ SG_ 1357 TAS_infoAssemblyId "Air suspension controller: info assembly id; raw 255 = signal not available (SNA)";
CM_ SG_ 1357 TAS_infoUsageId "Air suspension controller: info usage id";
CM_ SG_ 1357 TAS_infoSubUsageId "Air suspension controller: info sub usage id";
CM_ SG_ 1357 TAS_infoAppCrc "Air suspension controller: info app crc";
CM_ SG_ 1357 TAS_infoAppGitHash "Air suspension controller: info app git hash";
CM_ SG_ 1357 TAS_infoBootGitHash "Air suspension controller: info boot git hash";
CM_ SG_ 1357 TAS_infoPlatformType "Air suspension controller: info platform type";
CM_ SG_ 1357 TAS_infoMajorVersion "Air suspension controller: info major version; raw 255 = signal not available (SNA)";
CM_ SG_ 1357 TAS_infoBranchOrigin "Air suspension controller: info branch origin; raw 255 = signal not available (SNA)";
CM_ SG_ 1357 TAS_infoMaturity "Air suspension controller: info maturity; raw 255 = signal not available (SNA)";
CM_ SG_ 1357 TAS_infoHardwareRevision "Air suspension controller: info hardware revision; raw 255 = signal not available (SNA)";
CM_ BO_ 525 "Air suspension controller message: states";
CM_ SG_ 525 TAS_levelingState "Indicates air suspension leveling state.";
CM_ SG_ 525 TAS_levelingItem "Indicates the currently active air suspension components.";
CM_ SG_ 525 TAS_pressureGallery "Current air suspension valve block gallery pressure.; raw 255 = signal not available (SNA)";
CM_ SG_ 525 TAS_pressureReservoir "Indicates the latest valid reservoir pressure.; raw 255 = signal not available (SNA)";
CM_ SG_ 525 TAS_runMode "Indicates the status of run mode.";
CM_ SG_ 525 TAS_filterMode "Indicates the status of filter mode.";
CM_ SG_ 525 TAS_compressorRun "Either an indication that the compressor is running or a request to run the air compressor";
CM_ SG_ 525 TAS_twistDetected "TAS has detected large amount of twist.";
CM_ SG_ 525 TAS_leanDetected "TAS has detected vehicle to be leaning left or right.";
CM_ SG_ 525 TAS_limpHomeMode "Indicates which limp home mode is active.";
CM_ SG_ 525 TAS_targetLevel "Indicates target ride height.";
CM_ SG_ 525 TAS_currentLevel "Indicates current ride height.";
CM_ SG_ 525 TAS_jackMode "Indicates the status of Jack mode.";
CM_ SG_ 525 TAS_reduceVehicleSpeedRequest "Air suspension controller: reduce vehicle speed request";
CM_ SG_ 525 TAS_statesCounter "Air suspension controller: states counter";
CM_ SG_ 525 TAS_statesChecksum "Air suspension controller: states checksum";
CM_ BO_ 409 "Air suspension controller message: ui adaptive activity0";
CM_ SG_ 409 TAS_adaptiveActivityFL_C "Air suspension controller: adaptive activity FL c; raw 31 = signal not available (SNA)";
CM_ SG_ 409 TAS_adaptiveActivityFL_R "Air suspension controller: adaptive activity FL r; raw 31 = signal not available (SNA)";
CM_ SG_ 409 TAS_adaptiveActivityFR_C "Air suspension controller: adaptive activity FR c; raw 31 = signal not available (SNA)";
CM_ SG_ 409 TAS_adaptiveActivityFR_R "Air suspension controller: adaptive activity FR r; raw 31 = signal not available (SNA)";
CM_ SG_ 409 TAS_adaptiveActivityRL_C "Air suspension controller: adaptive activity RL c; raw 31 = signal not available (SNA)";
CM_ SG_ 409 TAS_adaptiveActivityRL_R "Air suspension controller: adaptive activity RL r; raw 31 = signal not available (SNA)";
CM_ SG_ 409 TAS_adaptiveActivityRR_C "Air suspension controller: adaptive activity RR c; raw 31 = signal not available (SNA)";
CM_ SG_ 409 TAS_adaptiveActivityRR_R "Air suspension controller: adaptive activity RR r; raw 31 = signal not available (SNA)";
CM_ SG_ 409 TAS_uiHeightFL "Air suspension controller: ui height FL; raw 63 = signal not available (SNA)";
CM_ SG_ 409 TAS_uiHeightFR "Air suspension controller: ui height FR; raw 63 = signal not available (SNA)";
CM_ SG_ 409 TAS_uiHeightRL "Air suspension controller: ui height RL; raw 63 = signal not available (SNA)";
CM_ SG_ 409 TAS_uiHeightRR "Air suspension controller: ui height RR; raw 63 = signal not available (SNA)";
CM_ BO_ 410 "Air suspension controller message: ui adaptive activity1";
CM_ SG_ 410 TAS_bodyAccelFL "Air suspension controller: body accel FL; raw 255 = signal not available (SNA)";
CM_ SG_ 410 TAS_bodyAccelFR "Air suspension controller: body accel FR; raw 255 = signal not available (SNA)";
CM_ SG_ 410 TAS_bodyAccelRL "Air suspension controller: body accel RL; raw 255 = signal not available (SNA)";
CM_ SG_ 410 TAS_bodyAccelRR "Air suspension controller: body accel RR; raw 255 = signal not available (SNA)";
CM_ BO_ 538 "Air suspension controller message: ui control";
CM_ SG_ 538 TAS_yellowWarningLamp "Air suspension controller: yellow warning lamp";
CM_ SG_ 538 TAS_redWarningLamp "Air suspension controller: red warning lamp";
CM_ SG_ 538 TAS_veryLowAllowed "Air suspension controller: very low allowed";
CM_ SG_ 538 TAS_lowAllowed "Air suspension controller: low allowed";
CM_ SG_ 538 TAS_standardAllowed "Air suspension controller: standard allowed";
CM_ SG_ 538 TAS_highAllowed "Air suspension controller: high allowed";
CM_ SG_ 538 TAS_veryHighAllowed "Air suspension controller: very high allowed";
CM_ SG_ 538 TAS_extractAllowed "Air suspension controller: extract allowed";
CM_ SG_ 538 TAS_showSpinner "Air suspension controller: show spinner";
CM_ SG_ 538 TAS_adaptiveRideModeOverride "Air suspension controller: adaptive ride mode override; raw 3 = signal not available (SNA)";
CM_ SG_ 538 TAS_levelSelectEnabled "Air suspension controller: level select enabled";
CM_ SG_ 538 TAS_jackModeToggleEnabled "Air suspension controller: jack mode toggle enabled";
CM_ SG_ 538 TAS_adaptiveRideSelectEnabled "Air suspension controller: adaptive ride select enabled";
CM_ SG_ 538 TAS_launchModeState "Air suspension controller: launch mode state";
CM_ SG_ 538 TAS_restrictUpLevelingFalcons "Air suspension controller: restrict up leveling falcons";
CM_ SG_ 538 TAS_restrictUpLevelingTrunk "Air suspension controller: restrict up leveling trunk";
CM_ SG_ 538 TAS_restrictDownLevelingDoors "Air suspension controller: restrict down leveling doors";
CM_ SG_ 538 TAS_restrictLevelingChargeCable "Air suspension controller: restrict leveling charge cable";
CM_ SG_ 538 TAS_restrictLevelingSystemCheck "Air suspension controller: restrict leveling system check";
CM_ SG_ 538 TAS_restrictLevelingTransport "Air suspension controller: restrict leveling transport";
CM_ SG_ 538 TAS_restrictLevelingShowroom "Indication that up and down leveling are restricted while showroom mode is active.";
CM_ SG_ 538 TAS_uiControlCounter "Air suspension controller: ui control counter";
CM_ SG_ 538 TAS_uiControlChecksum "Air suspension controller: ui control checksum";
CM_ BO_ 1154 "Touchscreen user interface computer message: iso tp pipe remote VCSEC; forwarded onto this bus by the gateway";
CM_ SG_ 1154 UI_IsoTpRemoteVCSEC0 "Touchscreen user interface computer: iso tp remote VCSEC0";
CM_ SG_ 1154 UI_IsoTpRemoteVCSEC1 "Touchscreen user interface computer: iso tp remote VCSEC1";
CM_ SG_ 1154 UI_IsoTpRemoteVCSEC2 "Touchscreen user interface computer: iso tp remote VCSEC2";
CM_ SG_ 1154 UI_IsoTpRemoteVCSEC3 "Touchscreen user interface computer: iso tp remote VCSEC3";
CM_ SG_ 1154 UI_IsoTpRemoteVCSEC4 "Touchscreen user interface computer: iso tp remote VCSEC4";
CM_ SG_ 1154 UI_IsoTpRemoteVCSEC5 "Touchscreen user interface computer: iso tp remote VCSEC5";
CM_ SG_ 1154 UI_IsoTpRemoteVCSEC6 "Touchscreen user interface computer: iso tp remote VCSEC6";
CM_ SG_ 1154 UI_IsoTpRemoteVCSEC7 "Touchscreen user interface computer: iso tp remote VCSEC7";
CM_ BO_ 1153 "Touchscreen user interface computer message: iso tp UDP pipe VCSEC; forwarded onto this bus by the gateway";
CM_ SG_ 1153 UI_IsoTpUDPPipeVCSEC0 "Touchscreen user interface computer: iso tp UDP pipe VCSEC0";
CM_ SG_ 1153 UI_IsoTpUDPPipeVCSEC1 "Touchscreen user interface computer: iso tp UDP pipe VCSEC1";
CM_ SG_ 1153 UI_IsoTpUDPPipeVCSEC2 "Touchscreen user interface computer: iso tp UDP pipe VCSEC2";
CM_ SG_ 1153 UI_IsoTpUDPPipeVCSEC3 "Touchscreen user interface computer: iso tp UDP pipe VCSEC3";
CM_ SG_ 1153 UI_IsoTpUDPPipeVCSEC4 "Touchscreen user interface computer: iso tp UDP pipe VCSEC4";
CM_ SG_ 1153 UI_IsoTpUDPPipeVCSEC5 "Touchscreen user interface computer: iso tp UDP pipe VCSEC5";
CM_ SG_ 1153 UI_IsoTpUDPPipeVCSEC6 "Touchscreen user interface computer: iso tp UDP pipe VCSEC6";
CM_ SG_ 1153 UI_IsoTpUDPPipeVCSEC7 "Touchscreen user interface computer: iso tp UDP pipe VCSEC7";
CM_ BO_ 1657 "Touchscreen user interface computer message: ambient lighting ctrls; forwarded onto this bus by the gateway";
CM_ SG_ 1657 UI_ambientLightPopupOpen "Touchscreen user interface computer: ambient light popup open";
CM_ SG_ 1657 UI_rgbEnableState "Request to enable RGB lights";
CM_ SG_ 1657 UI_rgbEffectType "Reports the RGB light effect type.";
CM_ SG_ 1657 UI_rgbLightingColorHexRed "Touchscreen user interface computer: rgb lighting color hex red";
CM_ SG_ 1657 UI_rgbLightingColorHexGreen "Touchscreen user interface computer: rgb lighting color hex green";
CM_ SG_ 1657 UI_rgbLightingColorHexBlue "Touchscreen user interface computer: rgb lighting color hex blue";
CM_ SG_ 1657 UI_rgbBrightnessLevel "Reports the requested RGB brightness level.; raw 127 = signal not available (SNA)";
CM_ SG_ 1657 UI_rgbTargetDOORFL "Target RGB control for front left door";
CM_ SG_ 1657 UI_rgbTargetDOORFR "Target RGB control for the front right door";
CM_ SG_ 1657 UI_rgbTargetDOORRL "Target RGB control for rear left door";
CM_ SG_ 1657 UI_rgbTargetDOORRR "Target RGB control for the rear right door";
CM_ SG_ 1657 UI_rgbTargetIPFL "Reports control for RGB lighting for the front left instrument panel.";
CM_ SG_ 1657 UI_rgbTargetIPFR "Reports control for RGB lighting for the front right instrument panel.";
CM_ BO_ 1021 "Touchscreen user interface computer message: autopilot control; forwarded onto this bus by the gateway";
CM_ SG_ 1021 UI_autopilotControlIndex "Touchscreen user interface computer: autopilot control index";
CM_ SG_ 1021 UI_hovEnabled "UI HOV routes enabled";
CM_ SG_ 1021 UI_donDisableAutoWiperDuration "Touchscreen user interface computer: don disable auto wiper duration";
CM_ SG_ 1021 UI_donDisableOnAutoWiperSpeed "Touchscreen user interface computer: don disable on auto wiper speed";
CM_ SG_ 1021 UI_blindspotMinSpeed "Touchscreen user interface computer: blindspot min speed";
CM_ SG_ 1021 UI_blindspotDistance "Touchscreen user interface computer: blindspot distance";
CM_ SG_ 1021 UI_blindspotTTC "Touchscreen user interface computer: blindspot TTC";
CM_ SG_ 1021 UI_donStopEndOfRampBuffer "Touchscreen user interface computer: don stop end of ramp buffer";
CM_ SG_ 1021 UI_donDisableCutin "Touchscreen user interface computer: don disable cutin";
CM_ SG_ 1021 UI_smartSetSpeedOffset "TACC will apply this offset over the speed limit";
CM_ SG_ 1021 UI_smartSetSpeedOffsetType "Offset applied will be a percentage or fixed value based on this setting";
CM_ SG_ 1021 UI_autopilotMonarchBackup "Touchscreen user interface computer: autopilot monarch backup";
CM_ SG_ 1021 UI_fsdVisualizationEnabled "Touchscreen user interface computer: fsd visualization enabled";
CM_ SG_ 1021 UI_fsdStopsControlEnabled "Indicates if autopilot control for traffic lights and stops signs has been enabled by the driver";
CM_ SG_ 1021 UI_fsdContinueOnGreenWithCIPV "Touchscreen user interface computer: fsd continue on green with CIPV";
CM_ SG_ 1021 UI_smartSetSpeed "TACC will use speed limit + offset as user set speed when enabled";
CM_ SG_ 1021 UI_automaticSetSpeedOffset "Maximum set speed offset would be determined automatically when this option is enabled";
CM_ SG_ 1021 UI_apply2021_1958_ISA "Touchscreen user interface computer: apply2021 1958 ISA";
CM_ SG_ 1021 UI_apply2021_646_ELKS "Touchscreen user interface computer: apply2021 646 ELKS";
CM_ SG_ 1021 UI_apply2021_1341_DDAW "Touchscreen user interface computer: apply2021 1341 DDAW";
CM_ SG_ 1021 UI_homelinkNearby "Touchscreen user interface computer: homelink nearby";
CM_ SG_ 1021 UI_enableFullSelfDriving "Indicates if the driver has enabled FSD behaviors";
CM_ SG_ 1021 UI_hasFullSelfDriving "Indicates if the vehicle hardware, software, and dependencies allow FSD";
CM_ SG_ 1021 UI_autosteerActivation "User-selected autosteer activation method";
CM_ SG_ 1021 UI_autopilotDrivingProfile "Driving profile for autopilot control";
CM_ SG_ 1021 UI_fsdBetaRequest "User accepted disclaimer and requested FSD (Supervised) builds";
CM_ SG_ 1021 UI_fullSelfDrivingSuspended "Full self driving is suspended";
CM_ SG_ 1021 UI_disableOptionalLaneChanges "Disable optional lane changes while FSD is controlling";
CM_ SG_ 1021 UI_applyR152_AEBS "Touchscreen user interface computer: apply R152 AEBS";
CM_ SG_ 1021 UI_autopilotControlMux0Valid "Touchscreen user interface computer: autopilot control mux0 valid";
CM_ SG_ 1021 UI_selectableCameraRequest "Infotainment selectable camera state request from AP signal; raw 15 = signal not available (SNA)";
CM_ SG_ 1021 UI_overrideSleepWithSuspend "Touchscreen user interface computer: override sleep with suspend";
CM_ SG_ 1021 UI_driverMonitorConfirmation "Driver attentiveness confirmation";
CM_ SG_ 1021 UI_parkAssistUseVision "Reports if the vehicle should use vision park assist.";
CM_ SG_ 1021 UI_applyEceR79 "Touchscreen user interface computer: apply ece R79";
CM_ SG_ 1021 UI_enableMapStops "Touchscreen user interface computer: enable map stops";
CM_ SG_ 1021 UI_disableMain "Touchscreen user interface computer: disable main";
CM_ SG_ 1021 UI_disableNarrow "Touchscreen user interface computer: disable narrow";
CM_ SG_ 1021 UI_disableFisheye "Touchscreen user interface computer: disable fisheye";
CM_ SG_ 1021 UI_disableLeftPillar "Touchscreen user interface computer: disable left pillar";
CM_ SG_ 1021 UI_disableRightPillar "Touchscreen user interface computer: disable right pillar";
CM_ SG_ 1021 UI_disableLeftRepeater "Touchscreen user interface computer: disable left repeater";
CM_ SG_ 1021 UI_disableRightRepeater "Touchscreen user interface computer: disable right repeater";
CM_ SG_ 1021 UI_disableBackup "Touchscreen user interface computer: disable backup";
CM_ SG_ 1021 UI_disableRadar "Touchscreen user interface computer: disable radar";
CM_ SG_ 1021 UI_noStalkConfirmAlertHaptic "Detects if alert haptic feedback should trigger.";
CM_ SG_ 1021 UI_regulatoryLKA "Touchscreen user interface computer: regulatory LKA";
CM_ SG_ 1021 UI_regulatoryLaneAssistLevel "Touchscreen user interface computer: regulatory lane assist level";
CM_ SG_ 1021 UI_ulcSnooze "Touchscreen user interface computer: ulc snooze";
CM_ SG_ 1021 UI_noStalkConfirmAlertChime "Detects if alert chime should trigger.";
CM_ SG_ 1021 UI_factorySummonEnable "Controls Factory Summon.";
CM_ SG_ 1021 UI_apmv3Branch "Touchscreen user interface computer: apmv3 branch";
CM_ SG_ 1021 UI_enableCabinCamera "Indicates if autopilot can enable cabin camera";
CM_ SG_ 1021 UI_enableAutopilotStopWarning "Enables the Autopilot active red light warning function.";
CM_ SG_ 1021 UI_showLaneGraph "Touchscreen user interface computer: show lane graph";
CM_ SG_ 1021 UI_showTrackLabels "Touchscreen user interface computer: show track labels";
CM_ SG_ 1021 UI_hardCoreSummon "Touchscreen user interface computer: hard core summon";
CM_ SG_ 1021 UI_enableCabinCameraTelemetry "Touchscreen user interface computer: enable cabin camera telemetry";
CM_ SG_ 1021 UI_enableVisionSpeedControl "Indicates if autopilot can enable vision speed control";
CM_ SG_ 1021 UI_autopilotTelemetryInChina "Touchscreen user interface computer: autopilot telemetry in china";
CM_ SG_ 1021 UI_enableTeslaAutopark "Indicates if autopilot can enable Telsa Autopark control";
CM_ SG_ 1021 UI_autoTurnSignalMode "Turn signal activation mode";
CM_ SG_ 1021 UI_enableCautionLightControl "Touchscreen user interface computer: enable caution light control";
CM_ SG_ 1021 UI_applyEceR79SmartSummonOnly "Touchscreen user interface computer: apply ece R79 smart summon only";
CM_ SG_ 1021 UI_autopilotMonarchEnabled "Touchscreen user interface computer: autopilot monarch enabled";
CM_ SG_ 1021 UI_autopilotEphemerisEnabled "Touchscreen user interface computer: autopilot ephemeris enabled";
CM_ SG_ 1021 UI_enableCabinAudioRecording "Indicates if autopilot can record cabin audio";
CM_ SG_ 1021 UI_autopilotControlMux1Valid "Touchscreen user interface computer: autopilot control mux1 valid";
CM_ SG_ 1021 UI_enableApproachingEmergencyVeh "Touchscreen user interface computer: enable approaching emergency vehicle detection";
CM_ SG_ 1021 UI_enableStartFsdFromParkBrakeCo "Touchscreen user interface computer: enable start fsd from park brake confirmation";
CM_ SG_ 1021 UI_enableStartFsdFromPark "Touchscreen user interface computer: enable start fsd from park";
CM_ SG_ 1021 UI_fsdMaxSpeedOffsetPercentage "Touchscreen user interface computer: fsd max speed offset percentage";
CM_ SG_ 1021 UI_coldStartMonarchInFactory "Touchscreen user interface computer: cold start monarch in factory";
CM_ SG_ 1021 UI_autopilotControlMux2Valid "Touchscreen user interface computer: autopilot control mux2 valid";
CM_ BO_ 819 "Touchscreen user interface computer message: charge request; forwarded onto this bus by the gateway";
CM_ SG_ 819 UI_openChargePortDoorRequest "Request to open charge port.";
CM_ SG_ 819 UI_closeChargePortDoorRequest "Request to close charge port.";
CM_ SG_ 819 UI_chargeEnableRequest "Charging request initiated";
CM_ SG_ 819 UI_brickVLoggingRequest "Touchscreen user interface computer: brick v logging request";
CM_ SG_ 819 UI_brickBalancingDisabled "Touchscreen user interface computer: brick balancing disabled";
CM_ SG_ 819 UI_dSocAlertThreshold "Touchscreen user interface computer: d soc alert threshold";
CM_ SG_ 819 UI_acChargeCurrentLimit "UI charging line current request; raw 127 = signal not available (SNA)";
CM_ SG_ 819 UI_dSocAlertEnable "Set when the BMS_a117_SW_Delta_SOC_Weak_Short alert for the BMS should have a functional response";
CM_ SG_ 819 UI_chargeTerminationPct "Charge Termination Limit Percent";
CM_ SG_ 819 UI_chargeFeature1 "Touchscreen user interface computer: charge feature1";
CM_ SG_ 819 UI_chargeFeature2 "Touchscreen user interface computer: charge feature2";
CM_ SG_ 819 UI_chargeFeature3 "Touchscreen user interface computer: charge feature3";
CM_ SG_ 819 UI_scheduledDepartureEnabled "Reports scheduled departure feature enablement.";
CM_ SG_ 819 UI_chargePortLatchRequest "Request to engage or disengage the latch.";
CM_ SG_ 819 UI_socSnapshotExpirationTime "Touchscreen user interface computer: soc snapshot expiration time";
CM_ SG_ 819 UI_cpInletHeaterRequest "Enable charge port inlet heater";
CM_ SG_ 819 UI_chargePowerSampleRequest "Touchscreen user interface computer: charge power sample request";
CM_ SG_ 819 UI_enableIso15118 "Touchscreen user interface computer: enable iso15118";
CM_ BO_ 659 "Touchscreen user interface computer message: chassis control; forwarded onto this bus by the gateway";
CM_ SG_ 659 UI_steeringTuneRequest "UI customer level request for steering feel. MS had comfort, normal, sport. M3 intent is Normal, sport see SW-95934";
CM_ SG_ 659 UI_tractionControlMode "Transport user selected traction control modes";
CM_ SG_ 659 UI_parkBrakeRequest "User selection for Park brake; raw 3 = signal not available (SNA)";
CM_ SG_ 659 UI_narrowGarages "Touchscreen user interface computer: narrow garages";
CM_ SG_ 659 UI_winchModeRequest "Winch mode (towing) request";
CM_ SG_ 659 UI_zeroSpeedConfirmed "Touchscreen user interface computer: zero speed confirmed; raw 3 = signal not available (SNA)";
CM_ SG_ 659 UI_trailerMode "Indicates whether trailer mode is selected. To be used when towing a trailer.";
CM_ SG_ 659 UI_distanceUnits "Touchscreen user interface computer: distance units";
CM_ SG_ 659 UI_dasDebugEnable "Touchscreen user interface computer: das debug enable";
CM_ SG_ 659 UI_accOvertakeEnable "Enable ACC Overtake assistance (reduce follow distance when the turn signal is on), UI firmware only sets datavalue to True; raw 3 = signal not available (SNA)";
CM_ SG_ 659 UI_aebEnable "Enable Autonomous Emergency Brakes; raw 3 = signal not available (SNA)";
CM_ SG_ 659 UI_aesEnable "Enable Automatic Emergency Steering (associated datavalue set to true and never changed by UI firmware); raw 3 = signal not available (SNA)";
CM_ SG_ 659 UI_ahlbEnable "Enable Automatic High/Low Beams; raw 3 = signal not available (SNA)";
CM_ SG_ 659 UI_autoLaneChangeEnable "Enable Automatic Lane Change; raw 3 = signal not available (SNA)";
CM_ SG_ 659 UI_winchProxUserOverride "User feedback from tow mode panel confirming that charge cable is disconnected when vehicle is unable to determine cable status";
CM_ SG_ 659 UI_rebootAutopilot "Touchscreen user interface computer: reboot autopilot";
CM_ SG_ 659 UI_autoParkRequest "Request Automatic Parking; raw 15 = signal not available (SNA)";
CM_ SG_ 659 UI_bsdEnable "Enable Blind Spot Detection (datavalue defaults to true and not changed by UI firmware); raw 3 = signal not available (SNA)";
CM_ SG_ 659 UI_fcwEnable "Enable Forward Collision Warning; raw 3 = signal not available (SNA)";
CM_ SG_ 659 UI_fcwSensitivity "Forward Collision Warning Level; raw 3 = signal not available (SNA)";
CM_ SG_ 659 UI_latControlEnable "Enable Lateral Control (lane centering, lane keeping, lane changing); raw 3 = signal not available (SNA)";
CM_ SG_ 659 UI_ldwEnable "Enable Lane Departure Warning; raw 3 = signal not available (SNA)";
CM_ SG_ 659 UI_pedalSafetyEnable "Touchscreen user interface computer: pedal safety enable; raw 3 = signal not available (SNA)";
CM_ SG_ 659 UI_pedalMap_epas "Touchscreen user interface computer: pedal map epas";
CM_ SG_ 659 UI_redLightStopSignEnable "Touchscreen user interface computer: red light stop sign enable; raw 3 = signal not available (SNA)";
CM_ SG_ 659 UI_selfParkTune "Touchscreen user interface computer: self park tune; raw 15 = signal not available (SNA)";
CM_ SG_ 659 UI_chassisControlCounter "Touchscreen user interface computer: chassis control counter";
CM_ SG_ 659 UI_chassisControlChecksum "Touchscreen user interface computer: chassis control checksum";
CM_ BO_ 531 "Touchscreen user interface computer message: cruise control; forwarded onto this bus by the gateway";
CM_ SG_ 531 UI_cruiseSpeedCommand "User command to change the cruise set speed.";
CM_ SG_ 531 UI_smartSummonRequest "Touchscreen user interface computer: smart summon request";
CM_ SG_ 531 UI_cruiseControlCounter "Touchscreen user interface computer: cruise control counter";
CM_ SG_ 531 UI_cruiseControlChecksum "Touchscreen user interface computer: cruise control checksum";
CM_ BO_ 1280 "Touchscreen user interface computer message: debug ECU; forwarded onto this bus by the gateway";
CM_ SG_ 1280 UI_debugEcuTarget "Touchscreen user interface computer: debug ecu target";
CM_ SG_ 1280 UI_DI_debugEnable "Touchscreen user interface computer: DI debug enable";
CM_ SG_ 1280 UI_DIS_debugEnable "Touchscreen user interface computer: DIS debug enable";
CM_ SG_ 1280 UI_PM_debugEnable "Touchscreen user interface computer: PM debug enable";
CM_ SG_ 1280 UI_PM_debugAt100Hz "Touchscreen user interface computer: PM debug at100 hz";
CM_ SG_ 1280 UI_PMS_debugEnable "Touchscreen user interface computer: PMS debug enable";
CM_ SG_ 1280 UI_PMS_debugAt100Hz "Touchscreen user interface computer: PMS debug at100 hz";
CM_ SG_ 1280 UI_BMS_debugAllEnable "Touchscreen user interface computer: BMS debug all enable";
CM_ SG_ 1280 UI_BMS_debugDisable "Touchscreen user interface computer: BMS debug disable";
CM_ SG_ 1280 UI_VCRIGHT_debugEnable "Touchscreen user interface computer: VCRIGHT debug enable";
CM_ SG_ 1280 UI_VCFRONT_debugEnable "Touchscreen user interface computer: VCFRONT debug enable";
CM_ SG_ 1280 UI_DIF_debugEnable "Touchscreen user interface computer: DIF debug enable";
CM_ SG_ 1280 UI_DIR_debugEnable "Touchscreen user interface computer: DIR debug enable";
CM_ SG_ 1280 UI_PMF_debugEnable "Touchscreen user interface computer: PMF debug enable";
CM_ SG_ 1280 UI_PMR_debugEnable "Touchscreen user interface computer: PMR debug enable";
CM_ BO_ 2043 "Touchscreen user interface computer message: debug tas; forwarded onto this bus by the gateway";
CM_ SG_ 2043 UI_debugDampingRequestFLC "Touchscreen user interface computer: debug damping request FLC; raw 255 = signal not available (SNA)";
CM_ SG_ 2043 UI_debugDampingRequestFLR "Touchscreen user interface computer: debug damping request FLR; raw 255 = signal not available (SNA)";
CM_ SG_ 2043 UI_debugDampingRequestFRC "Touchscreen user interface computer: debug damping request FRC; raw 255 = signal not available (SNA)";
CM_ SG_ 2043 UI_debugDampingRequestFRR "Touchscreen user interface computer: debug damping request FRR; raw 255 = signal not available (SNA)";
CM_ SG_ 2043 UI_debugDampingRequestRLC "Touchscreen user interface computer: debug damping request RLC; raw 255 = signal not available (SNA)";
CM_ SG_ 2043 UI_debugDampingRequestRLR "Touchscreen user interface computer: debug damping request RLR; raw 255 = signal not available (SNA)";
CM_ SG_ 2043 UI_debugDampingRequestRRC "Touchscreen user interface computer: debug damping request RRC; raw 255 = signal not available (SNA)";
CM_ SG_ 2043 UI_debugDampingRequestRRR "Touchscreen user interface computer: debug damping request RRR; raw 255 = signal not available (SNA)";
CM_ BO_ 568 "Touchscreen user interface computer message: driver assist map data; forwarded onto this bus by the gateway";
CM_ SG_ 568 UI_mapSpeedLimitDependency "Touchscreen user interface computer: map speed limit dependency; raw 7 = signal not available (SNA)";
CM_ SG_ 568 UI_roadClass "Autopilot map road class; raw 0 = signal not available (SNA)";
CM_ SG_ 568 UI_inSuperchargerGeofence "Touchscreen user interface computer: in supercharger geofence";
CM_ SG_ 568 UI_mapSpeedUnits "Touchscreen user interface computer: map speed units";
CM_ SG_ 568 UI_mapSpeedLimit "Touchscreen user interface computer: map speed limit; raw 31 = signal not available (SNA)";
CM_ SG_ 568 UI_mapSpeedLimitType "Touchscreen user interface computer: map speed limit type; raw 7 = signal not available (SNA)";
CM_ SG_ 568 UI_countryCode "Touchscreen user interface computer: country code; raw 1023 = signal not available (SNA)";
CM_ SG_ 568 UI_streetCount "Touchscreen user interface computer: street count";
CM_ SG_ 568 UI_gpsRoadMatch "Touchscreen user interface computer: gps road match";
CM_ SG_ 568 UI_navRouteActive "Navigation route is active";
CM_ SG_ 568 UI_parallelAutoparkEnabled "Autopilot map parallel park enabled.";
CM_ SG_ 568 UI_perpendicularAutoparkEnabled "Autopilot map perpendicular park enabled.";
CM_ SG_ 568 UI_nextBranchDist "Touchscreen user interface computer: next branch dist; raw 31 = signal not available (SNA)";
CM_ SG_ 568 UI_controlledAccess "DAS map controlled access segment.";
CM_ SG_ 568 UI_nextBranchLeftOffRamp "Touchscreen user interface computer: next branch left off ramp";
CM_ SG_ 568 UI_nextBranchRightOffRamp "Touchscreen user interface computer: next branch right off ramp";
CM_ SG_ 568 UI_rejectLeftLane "Touchscreen user interface computer: reject left lane";
CM_ SG_ 568 UI_rejectRightLane "Touchscreen user interface computer: reject right lane";
CM_ SG_ 568 UI_rejectHPP "Touchscreen user interface computer: reject HPP";
CM_ SG_ 568 UI_rejectNav "Touchscreen user interface computer: reject nav";
CM_ SG_ 568 UI_rejectLeftFreeSpace "Touchscreen user interface computer: reject left free space";
CM_ SG_ 568 UI_rejectRightFreeSpace "Touchscreen user interface computer: reject right free space";
CM_ SG_ 568 UI_rejectAutosteer "Touchscreen user interface computer: reject autosteer";
CM_ SG_ 568 UI_rejectHandsOn "Touchscreen user interface computer: reject hands on";
CM_ SG_ 568 UI_acceptBottsDots "Touchscreen user interface computer: accept botts dots";
CM_ SG_ 568 UI_autosteerRestricted "Autopilot map is autostreer restricted.";
CM_ SG_ 568 UI_pmmEnabled "Touchscreen user interface computer: pmm enabled";
CM_ SG_ 568 UI_scaEnabled "Touchscreen user interface computer: sca enabled";
CM_ SG_ 568 UI_mapDataCounter "Touchscreen user interface computer: map data counter";
CM_ SG_ 568 UI_mapDataChecksum "Touchscreen user interface computer: map data checksum";
CM_ BO_ 645 "Touchscreen user interface computer message: driver profile recall; forwarded onto this bus by the gateway";
CM_ SG_ 645 UI_driverProfileRecallIndex "Touchscreen user interface computer: driver profile recall index; raw 0 = signal not available (SNA)";
CM_ SG_ 645 UI_driverProfileRecallStop "notifies controller to stop profile recall action";
CM_ SG_ 645 UI_frontSeatRecallActive "signals when driver seat presets are being recalled";
CM_ SG_ 645 UI_frontSeatTrackPos "Touchscreen user interface computer: front seat track pos";
CM_ SG_ 645 UI_frontSeatBackPos "Touchscreen user interface computer: front seat back pos";
CM_ SG_ 645 UI_frontSeatLiftPos "Touchscreen user interface computer: front seat lift pos";
CM_ SG_ 645 UI_frontSeatTiltPos "Touchscreen user interface computer: front seat tilt pos";
CM_ SG_ 645 UI_columnAndLumbarRecallActive "Touchscreen user interface computer: column and lumbar recall active";
CM_ SG_ 645 UI_steeringColumnUpDownPos "Touchscreen user interface computer: steering column up down pos";
CM_ SG_ 645 UI_lumbarAPressureHpa "Touchscreen user interface computer: lumbar a pressure hpa";
CM_ SG_ 645 UI_lumbarBPressureHpa "Touchscreen user interface computer: lumbar b pressure hpa";
CM_ SG_ 645 UI_steeringColumnInOutPos "Touchscreen user interface computer: steering column in out pos";
CM_ SG_ 645 UI_leftMirrorTiltXPosition "signal from ui to command mirror X tilt position";
CM_ SG_ 645 UI_leftMirrorTiltYPosition "signal from ui to command mirror Y tilt position";
CM_ SG_ 645 UI_rightMirrorTiltXPosition "Touchscreen user interface computer: right mirror tilt x position";
CM_ SG_ 645 UI_rightMirrorTiltYPosition "Touchscreen user interface computer: right mirror tilt y position";
CM_ SG_ 645 UI_mirrorRecallActive "Touchscreen user interface computer: mirror recall active";
CM_ SG_ 645 UI_customMirrorDipPositionsSet "Reports whether custom mirror dip positions are set.";
CM_ SG_ 645 UI_leftMirrorDipXPosition "signal from ui to command left mirror X dip position";
CM_ SG_ 645 UI_leftMirrorDipYPosition "signal from ui to command mirror Y dip position";
CM_ SG_ 645 UI_rightMirrorDipXPosition "Touchscreen user interface computer: right mirror dip x position";
CM_ SG_ 645 UI_rightMirrorDipYPosition "Touchscreen user interface computer: right mirror dip y position";
CM_ SG_ 645 UI_modifyMirrorDipRequest "Reports that a user is trying to modify the mirrors in the dipped position.";
CM_ BO_ 651 "Touchscreen user interface computer message: driver profile recall2; forwarded onto this bus by the gateway";
CM_ SG_ 651 UI_driverProfileLinkedKeySHA1 "Touchscreen user interface computer: driver profile linked key SHA1; raw 4294967295 = signal not available (SNA)";
CM_ SG_ 651 UI_driverProfileIndex "Tracks manual driver profile selection. Shows the linked phonekey / key card / key fob or profile index if not linked";
CM_ SG_ 651 UI_driverProfileSelectionType "Tracks manual driver profile selection. Shows the linked phonekey / key card / key fob or profile index if not linked";
CM_ SG_ 651 UI_driverProfilePositionAdjusted "Tracks adjustments to driver profile. Sets when a profile position has been adjusted from what was saved";
CM_ SG_ 651 UI_activeKeyRequested "Tracks manual driver profile selection. Shows the linked phonekey / key card / key fob or profile index if not linked";
CM_ BO_ 984 "Touchscreen user interface computer message: elevation status; forwarded onto this bus by the gateway";
CM_ SG_ 984 UI_elevation "Touchscreen user interface computer: elevation; raw 8191 = signal not available (SNA)";
CM_ SG_ 984 UI_navElevation "Touchscreen user interface computer: nav elevation; raw 8191 = signal not available (SNA)";
CM_ BO_ 1139 "Touchscreen user interface computer message: eth nm; forwarded onto this bus by the gateway";
CM_ SG_ 1139 UI_nmGoingToSleep "Touchscreen user interface computer: nm going to sleep";
CM_ SG_ 1139 UI_nmKeepAwakeReason "reason UI is being kept awake; raw 0 = signal not available (SNA)";
CM_ SG_ 1139 UI_wakeupTime "Unix epoch time at which vehicle should wake for scheduled charge or update.";
CM_ BO_ 1267 "Touchscreen user interface computer message: front seat requests; forwarded onto this bus by the gateway";
CM_ SG_ 1267 UI_frontRightSeatTrackForward "Touchscreen user interface computer: front right seat track forward";
CM_ SG_ 1267 UI_frontRightSeatTrackBack "Touchscreen user interface computer: front right seat track back";
CM_ SG_ 1267 UI_frontLeftSeatTrackForward "Touchscreen user interface computer: front left seat track forward";
CM_ SG_ 1267 UI_frontLeftSeatTrackBack "Touchscreen user interface computer: front left seat track back";
CM_ SG_ 1267 UI_frontRightSeatBackrestBack "Touchscreen user interface computer: front right seat backrest back";
CM_ SG_ 1267 UI_frontRightSeatBackrestForward "Touchscreen user interface computer: front right seat backrest forward";
CM_ SG_ 1267 UI_frontLeftSeatBackrestBack "Touchscreen user interface computer: front left seat backrest back";
CM_ SG_ 1267 UI_frontLeftSeatBackrestForward "Touchscreen user interface computer: front left seat backrest forward";
CM_ BO_ 804 "Touchscreen user interface computer message: gps time; forwarded onto this bus by the gateway";
CM_ SG_ 804 UI_gpsTime "Touchscreen user interface computer: gps time";
CM_ BO_ 883 "Touchscreen user interface computer message: gps vehicle speed; forwarded onto this bus by the gateway";
CM_ SG_ 883 UI_gpsHDOP "Touchscreen user interface computer: gps HDOP";
CM_ SG_ 883 UI_gpsVehicleHeading "Touchscreen user interface computer: gps vehicle heading";
CM_ SG_ 883 UI_gpsVehicleSpeed "Touchscreen user interface computer: gps vehicle speed";
CM_ SG_ 883 UI_userSpeedOffset "Touchscreen user interface computer: user speed offset";
CM_ SG_ 883 UI_mapSpeedLimitUnits "Autopilot map speed limit units.";
CM_ SG_ 883 UI_userSpeedOffsetUnits "Touchscreen user interface computer: user speed offset units";
CM_ SG_ 883 UI_mppSpeedLimit "Autopilot map speed limit";
CM_ SG_ 883 UI_gpsNmeaMIA "GPS NMEA data MIA";
CM_ SG_ 883 UI_gpsAntennaDisconnected "GPS antenna state";
CM_ SG_ 883 UI_conditionalLimitActive "Conditional speed limit condition is currently active";
CM_ SG_ 883 UI_conditionalSpeedLimit "Conditional speed limit value; raw 31 = signal not available (SNA)";
CM_ BO_ 755 "Touchscreen user interface computer message: hvac request; forwarded onto this bus by the gateway";
CM_ SG_ 755 UI_hvacReqTempSetpointLeft "HVAC left set temperature.";
CM_ SG_ 755 UI_hvacReqAutoBlowerLevel "Reports the auto Heating, Ventilation, and Air Conditioning (HVAC) speed aggressiveness setting.";
CM_ SG_ 755 UI_hvacReqTempSetpointRight "HVAC right set temperature.";
CM_ SG_ 755 UI_hvacReqAirDistributionMode "Request for air distribution mode.";
CM_ SG_ 755 UI_hvacReqBlowerSegment "HVAC manual blower request (GUI_hvacManualBlowerRequest)";
CM_ SG_ 755 UI_hvacReqRecirc "HVAC recirculation mode";
CM_ SG_ 755 UI_hvacReqACDisable "Request to disable AC.";
CM_ SG_ 755 UI_hvacDefogState "HVAC defog state.";
CM_ SG_ 755 UI_hvacReqUserPowerState "Reports HVAC power state.";
CM_ SG_ 755 UI_hvacReqSecondRowState "HVAC rear fan request speed.";
CM_ SG_ 755 UI_hvacUseModeledDuctTemp "Touchscreen user interface computer: hvac use modeled duct temp";
CM_ SG_ 755 UI_hvacReqKeepClimateOn "Request accessory power";
CM_ SG_ 755 UI_hvacReqBioWeaponDefMode "Request for BioWeapon Defense Mode";
CM_ SG_ 755 UI_hvacLatchPassengerPresent "Touchscreen user interface computer: hvac latch passenger present";
CM_ SG_ 755 UI_enableHvacControlsFeatures1 "Touchscreen user interface computer: enable hvac controls features1";
CM_ SG_ 755 UI_enableHvacNotifications "Touchscreen user interface computer: enable hvac notifications";
CM_ SG_ 755 UI_hvacPhoneCallAirFlowAdjustEna "Touchscreen user interface computer: hvac phone call air flow adjust enabled";
CM_ SG_ 755 UI_enableHvacVOCPurgeRoutine "Touchscreen user interface computer: enable hvac VOC purge routine";
CM_ SG_ 755 UI_enableCustomerTHSAlerts "Touchscreen user interface computer: enable customer THS alerts";
CM_ SG_ 755 UI_evapDryingSelectiveEnable "Touchscreen user interface computer: evap drying selective enable";
CM_ SG_ 755 UI_enableHvacWeatherDataBasedHum "Touchscreen user interface computer: enable hvac weather data based humidity controls";
CM_ SG_ 755 UI_hvacReqTempSetpointCOP "HVAC cabin overheat protection set temperature.";
CM_ SG_ 755 UI_hvacClimateNudgeStatus "Touchscreen user interface computer: hvac climate nudge status";
CM_ SG_ 755 UI_enableHvacControlsFeatures2 "Touchscreen user interface computer: enable hvac controls features2";
CM_ SG_ 755 UI_enableHvacAPFoggingMonitor "Touchscreen user interface computer: enable hvac AP fogging monitor";
CM_ SG_ 755 UI_enableHvacLimpMode "Touchscreen user interface computer: enable hvac limp mode";
CM_ BO_ 777 "Touchscreen user interface computer message: location status; forwarded onto this bus by the gateway";
CM_ SG_ 777 UI_latitude "Touchscreen user interface computer: latitude";
CM_ SG_ 777 UI_longitude "Touchscreen user interface computer: longitude";
CM_ SG_ 777 UI_gpsAccuracy "Touchscreen user interface computer: gps accuracy; raw 127 = signal not available (SNA)";
BA_DEF_ BO_ "GenMsgCycleTime" INT 0 3600000;
BA_DEF_ BO_ "GenMsgSendType" ENUM "Cyclic","NotUsed","NotUsed","NotUsed","NotUsed","NotUsed","NotUsed","IfActive","NoMsgSendType","NotUsed";
BA_DEF_ BO_ "VFrameFormat" ENUM "StandardCAN","ExtendedCAN","reserved","J1939PG","reserved","reserved","reserved","reserved","reserved","reserved","reserved","reserved","reserved","reserved","StandardCAN_FD","ExtendedCAN_FD";
BA_DEF_ BO_ "CANFD_BRS" ENUM "0","1";
BA_DEF_ SG_ "GenSigSNA" STRING;
BA_DEF_ SG_ "SystemSignalLongSymbol" STRING;
BA_DEF_ SG_ "Confidence" ENUM "validated","plausible","layout-only","contradicted";
BA_DEF_DEF_ "GenMsgCycleTime" 0;
BA_DEF_DEF_ "GenMsgSendType" "NoMsgSendType";
BA_DEF_DEF_ "VFrameFormat" "StandardCAN";
BA_DEF_DEF_ "CANFD_BRS" "1";
BA_DEF_DEF_ "GenSigSNA" "";
BA_DEF_DEF_ "SystemSignalLongSymbol" "";
BA_DEF_DEF_ "Confidence" "layout-only";
BA_ "GenMsgCycleTime" BO_ 852 100;
BA_ "GenMsgSendType" BO_ 852 0;
BA_ "GenMsgCycleTime" BO_ 523 20;
BA_ "GenMsgSendType" BO_ 523 0;
BA_ "GenMsgCycleTime" BO_ 1398 100;
BA_ "GenMsgSendType" BO_ 1398 0;
BA_ "GenMsgCycleTime" BO_ 1357 1000;
BA_ "GenMsgSendType" BO_ 1357 0;
BA_ "GenMsgCycleTime" BO_ 525 100;
BA_ "GenMsgSendType" BO_ 525 0;
BA_ "GenMsgCycleTime" BO_ 409 50;
BA_ "GenMsgSendType" BO_ 409 0;
BA_ "GenMsgCycleTime" BO_ 410 50;
BA_ "GenMsgSendType" BO_ 410 0;
BA_ "GenMsgCycleTime" BO_ 538 100;
BA_ "GenMsgSendType" BO_ 538 0;
BA_ "GenMsgCycleTime" BO_ 1657 500;
BA_ "GenMsgSendType" BO_ 1657 0;
BA_ "GenMsgCycleTime" BO_ 1021 500;
BA_ "GenMsgSendType" BO_ 1021 0;
BA_ "GenMsgCycleTime" BO_ 819 500;
BA_ "GenMsgSendType" BO_ 819 0;
BA_ "GenMsgCycleTime" BO_ 659 500;
BA_ "GenMsgSendType" BO_ 659 0;
BA_ "GenMsgCycleTime" BO_ 531 500;
BA_ "GenMsgSendType" BO_ 531 0;
BA_ "GenMsgCycleTime" BO_ 1280 5000;
BA_ "GenMsgSendType" BO_ 1280 0;
BA_ "GenMsgCycleTime" BO_ 2043 2000;
BA_ "GenMsgSendType" BO_ 2043 0;
BA_ "GenMsgCycleTime" BO_ 568 500;
BA_ "GenMsgSendType" BO_ 568 0;
BA_ "GenMsgCycleTime" BO_ 645 500;
BA_ "GenMsgSendType" BO_ 645 0;
BA_ "GenMsgCycleTime" BO_ 651 500;
BA_ "GenMsgSendType" BO_ 651 0;
BA_ "GenMsgCycleTime" BO_ 984 1000;
BA_ "GenMsgSendType" BO_ 984 0;
BA_ "GenMsgCycleTime" BO_ 1139 500;
BA_ "GenMsgSendType" BO_ 1139 0;
BA_ "GenMsgCycleTime" BO_ 1267 500;
BA_ "GenMsgSendType" BO_ 1267 0;
BA_ "GenMsgCycleTime" BO_ 804 1000;
BA_ "GenMsgSendType" BO_ 804 0;
BA_ "GenMsgCycleTime" BO_ 883 1000;
BA_ "GenMsgSendType" BO_ 883 0;
BA_ "GenMsgCycleTime" BO_ 755 500;
BA_ "GenMsgSendType" BO_ 755 0;
BA_ "GenMsgCycleTime" BO_ 777 1000;
BA_ "GenMsgSendType" BO_ 777 0;
BA_ "Confidence" SG_ 1291 TAS_alertID 1;
BA_ "Confidence" SG_ 1291 TAS_alertState 1;
BA_ "Confidence" SG_ 1291 TAS_a030_PWMdutyCycleFL 1;
BA_ "Confidence" SG_ 1291 TAS_a030_PWMfrequencyFL 1;
BA_ "Confidence" SG_ 1291 TAS_a030_PWMfaultFL 1;
BA_ "Confidence" SG_ 1291 TAS_a031_PWMdutyCycleFR 1;
BA_ "Confidence" SG_ 1291 TAS_a031_PWMfrequencyFR 1;
BA_ "Confidence" SG_ 1291 TAS_a031_PWMfaultFR 1;
BA_ "Confidence" SG_ 1291 TAS_a032_PWMdutyCycleRL 1;
BA_ "Confidence" SG_ 1291 TAS_a032_PWMfrequencyRL 1;
BA_ "Confidence" SG_ 1291 TAS_a032_PWMfaultRL 1;
BA_ "Confidence" SG_ 1291 TAS_a033_PWMdutyCycleRR 1;
BA_ "Confidence" SG_ 1291 TAS_a033_PWMfrequencyRR 1;
BA_ "Confidence" SG_ 1291 TAS_a033_PWMfaultRR 1;
BA_ "Confidence" SG_ 1291 TAS_a034_PWMdutyCycleFL 1;
BA_ "Confidence" SG_ 1291 TAS_a034_PWMfrequencyFL 1;
BA_ "Confidence" SG_ 1291 TAS_a034_PWMfaultFL 1;
BA_ "Confidence" SG_ 1291 TAS_a035_PWMdutyCycleFR 1;
BA_ "Confidence" SG_ 1291 TAS_a035_PWMfrequencyFR 1;
BA_ "Confidence" SG_ 1291 TAS_a035_PWMfaultFR 1;
BA_ "Confidence" SG_ 1291 TAS_a036_PWMdutyCycleRL 1;
BA_ "Confidence" SG_ 1291 TAS_a036_PWMfrequencyRL 1;
BA_ "Confidence" SG_ 1291 TAS_a036_PWMfaultRL 1;
BA_ "Confidence" SG_ 1291 TAS_a037_PWMdutyCycleRR 1;
BA_ "Confidence" SG_ 1291 TAS_a037_PWMfrequencyRR 1;
BA_ "Confidence" SG_ 1291 TAS_a037_PWMfaultRR 1;
BA_ "Confidence" SG_ 1291 TAS_a038_PWMdutyCycleFL 1;
BA_ "Confidence" SG_ 1291 TAS_a038_PWMfrequencyFL 1;
BA_ "Confidence" SG_ 1291 TAS_a038_PWMfaultFL 1;
BA_ "Confidence" SG_ 1291 TAS_a039_PWMdutyCycleFR 1;
BA_ "Confidence" SG_ 1291 TAS_a039_PWMfrequencyFR 1;
BA_ "Confidence" SG_ 1291 TAS_a039_PWMfaultFR 1;
BA_ "Confidence" SG_ 1291 TAS_a040_PWMdutyCycleRL 1;
BA_ "Confidence" SG_ 1291 TAS_a040_PWMfrequencyRL 1;
BA_ "Confidence" SG_ 1291 TAS_a040_PWMfaultRL 1;
BA_ "Confidence" SG_ 1291 TAS_a041_PWMdutyCycleRR 1;
BA_ "Confidence" SG_ 1291 TAS_a041_PWMfrequencyRR 1;
BA_ "Confidence" SG_ 1291 TAS_a041_PWMfaultRR 1;
BA_ "Confidence" SG_ 1291 TAS_a070_voltage12V 1;
BA_ "Confidence" SG_ 1291 TAS_a071_voltage12V 1;
BA_ "Confidence" SG_ 1291 TAS_a072_voltage5VOnBoard 1;
BA_ "Confidence" SG_ 1291 TAS_a073_voltage5VOnBoard 1;
BA_ "Confidence" SG_ 1291 TAS_a074_voltage5VOffBoard 1;
BA_ "Confidence" SG_ 1291 TAS_a075_voltage5VOffBoard 1;
BA_ "Confidence" SG_ 1291 TAS_a076_voltage5VOffBoard 1;
BA_ "Confidence" SG_ 1291 TAS_a077_sensorVoltage 1;
BA_ "Confidence" SG_ 1291 TAS_a077_sensorRefVoltage 1;
BA_ "Confidence" SG_ 1291 TAS_a078_sensorVoltage 1;
BA_ "Confidence" SG_ 1291 TAS_a078_sensorRefVoltage 1;
BA_ "Confidence" SG_ 1291 TAS_a080_voltage5VHeight 1;
BA_ "Confidence" SG_ 1291 TAS_a081_voltage5VHeight 1;
BA_ "Confidence" SG_ 1291 TAS_a082_voltage5VHeight 1;
BA_ "Confidence" SG_ 1291 TAS_a083_voltage5VAnalog 1;
BA_ "Confidence" SG_ 1291 TAS_a084_voltage5VAnalog 1;
BA_ "Confidence" SG_ 1291 TAS_a085_voltage5VAnalog 1;
BA_ "Confidence" SG_ 1291 TAS_a086_voltage12VSwitched 1;
BA_ "Confidence" SG_ 1291 TAS_a087_voltage12VSwitched 1;
BA_ "SystemSignalLongSymbol" SG_ 1291 TAS_a098_VCFRONT_LVPowerState_MI "TAS_a098_VCFRONT_LVPowerState_MIA";
BA_ "SystemSignalLongSymbol" SG_ 1291 TAS_a098_VCFRONT_systemStatus_MI "TAS_a098_VCFRONT_systemStatus_MIA";
BA_ "SystemSignalLongSymbol" SG_ 1291 TAS_a099_UI_driverAssistMapData_ "TAS_a099_UI_driverAssistMapData_MIA";
BA_ "SystemSignalLongSymbol" SG_ 1291 TAS_a099_UI_suspensionControl_MI "TAS_a099_UI_suspensionControl_MIA";
BA_ "Confidence" SG_ 1291 TAS_a164_detectedDamperSolenoid 1;
BA_ "Confidence" SG_ 1291 TAS_a164_expectedDamperSolenoid 1;
BA_ "Confidence" SG_ 1291 TAS_a165_damperValveFault 1;
BA_ "Confidence" SG_ 1291 TAS_a166_damperValveFault 1;
BA_ "Confidence" SG_ 1291 TAS_a167_damperValveFault 1;
BA_ "Confidence" SG_ 1291 TAS_a168_damperValveFault 1;
BA_ "Confidence" SG_ 1291 TAS_a169_damperValveFault 1;
BA_ "Confidence" SG_ 1291 TAS_a170_damperValveFault 1;
BA_ "Confidence" SG_ 1291 TAS_a171_damperValveFault 1;
BA_ "Confidence" SG_ 1291 TAS_a172_damperValveFault 1;
BA_ "Confidence" SG_ 1291 TAS_a173_heightDelta_mm 1;
BA_ "Confidence" SG_ 1291 TAS_a174_heightDelta_mm 1;
BA_ "Confidence" SG_ 1291 TAS_a175_heightDelta_mm 1;
BA_ "Confidence" SG_ 1291 TAS_a176_heightDelta_mm 1;
BA_ "Confidence" SG_ 1291 TAS_a190_a2bFaultType 1;
BA_ "Confidence" SG_ 1291 TAS_a190_a2bInterruptType 1;
BA_ "Confidence" SG_ 1291 TAS_a190_a2bFaultSource 1;
BA_ "Confidence" SG_ 1291 TAS_a191_a2bFaultType 1;
BA_ "Confidence" SG_ 1291 TAS_a191_a2bInterruptType 1;
BA_ "Confidence" SG_ 1291 TAS_a191_a2bFaultSource 1;
BA_ "Confidence" SG_ 1291 TAS_a192_rideHeightVelDspFL 1;
BA_ "Confidence" SG_ 1291 TAS_a192_rideHeightVelDspFR 1;
BA_ "Confidence" SG_ 1291 TAS_a192_rideHeightVelDspRL 1;
BA_ "Confidence" SG_ 1291 TAS_a192_rideHeightVelDspRR 1;
BA_ "Confidence" SG_ 1291 TAS_a192_rideHeightVelObserverFL 1;
BA_ "Confidence" SG_ 1291 TAS_a192_rideHeightVelObserverFR 1;
BA_ "Confidence" SG_ 1291 TAS_a192_rideHeightVelObserverRL 1;
BA_ "Confidence" SG_ 1291 TAS_a192_rideHeightVelObserverRR 1;
BA_ "Confidence" SG_ 1291 TAS_a210_heightSensorDeltaFL 1;
BA_ "Confidence" SG_ 1291 TAS_a210_heightSensorDeltaFR 1;
BA_ "Confidence" SG_ 1291 TAS_a210_heightSensorDeltaRL 1;
BA_ "Confidence" SG_ 1291 TAS_a210_heightSensorDeltaRR 1;
BA_ "Confidence" SG_ 1291 TAS_a220_galleryPressure 1;
BA_ "Confidence" SG_ 1291 TAS_a220_timeInExhaust 1;
BA_ "Confidence" SG_ 1291 TAS_a221_galleryPressureDelta 1;
BA_ "Confidence" SG_ 1291 TAS_a221_timeInIdle 1;
BA_ "Confidence" SG_ 1291 TAS_a222_galleryPressureDelta 1;
BA_ "Confidence" SG_ 1291 TAS_a223_galleryPressure 1;
BA_ "Confidence" SG_ 1291 TAS_a224_galleryPressure 1;
BA_ "Confidence" SG_ 1291 TAS_a225_galleryPressure 1;
BA_ "Confidence" SG_ 1291 TAS_a226_PWMdutyCycleFL 1;
BA_ "Confidence" SG_ 1291 TAS_a226_PWMfrequencyFL 1;
BA_ "Confidence" SG_ 1291 TAS_a226_PWMfaultFL 1;
BA_ "Confidence" SG_ 1291 TAS_a227_PWMdutyCycleFR 1;
BA_ "Confidence" SG_ 1291 TAS_a227_PWMfrequencyFR 1;
BA_ "Confidence" SG_ 1291 TAS_a227_PWMfaultFR 1;
BA_ "Confidence" SG_ 1291 TAS_a228_PWMdutyCycleRL 1;
BA_ "Confidence" SG_ 1291 TAS_a228_PWMfrequencyRL 1;
BA_ "Confidence" SG_ 1291 TAS_a228_PWMfaultRL 1;
BA_ "Confidence" SG_ 1291 TAS_a229_PWMdutyCycleRR 1;
BA_ "Confidence" SG_ 1291 TAS_a229_PWMfrequencyRR 1;
BA_ "Confidence" SG_ 1291 TAS_a229_PWMfaultRR 1;
BA_ "Confidence" SG_ 1291 TAS_a232_detectedSuspensionType 1;
BA_ "Confidence" SG_ 1291 TAS_a232_expectedSuspensionType 1;
BA_ "Confidence" SG_ 1291 TAS_a234_detectedDamperHydraulic 1;
BA_ "Confidence" SG_ 1291 TAS_a234_expectedDamperHydraulic 1;
BA_ "Confidence" SG_ 1291 TAS_a240_adjustCountRatioSpring 1;
BA_ "Confidence" SG_ 1291 TAS_a240_adjustCountRatio 1;
BA_ "GenSigSNA" SG_ 1291 TAS_a240_adjustCountRatio "255";
BA_ "Confidence" SG_ 1291 TAS_a240_adjustTimeRatioSpring 1;
BA_ "Confidence" SG_ 1291 TAS_a240_adjustTimeRatio 1;
BA_ "GenSigSNA" SG_ 1291 TAS_a240_adjustTimeRatio "255";
BA_ "Confidence" SG_ 1291 TAS_a240_compExhTimeRatio 1;
BA_ "Confidence" SG_ 1291 TAS_a240_crossPressure 1;
BA_ "Confidence" SG_ 1291 TAS_a285_twistLevel 1;
BA_ "Confidence" SG_ 1291 TAS_a290_twistLevel 1;
BA_ "Confidence" SG_ 1291 TAS_a291_frontAxleHeight 1;
BA_ "Confidence" SG_ 1291 TAS_a292_rearAxleHeight 1;
BA_ "Confidence" SG_ 1291 TAS_a293_frontAxleHeight 1;
BA_ "Confidence" SG_ 1291 TAS_a294_rearAxleHeight 1;
BA_ "Confidence" SG_ 1291 TAS_a295_targetHeight 1;
BA_ "Confidence" SG_ 1291 TAS_a296_detectedChassisType 1;
BA_ "Confidence" SG_ 1291 TAS_a296_expectedChassisType 1;
BA_ "Confidence" SG_ 1291 TAS_a319_detectedDrivetrainType 1;
BA_ "Confidence" SG_ 1291 TAS_a319_expectedDrivetrainType 1;
BA_ "Confidence" SG_ 852 TAS_matrixIndex 1;
BA_ "SystemSignalLongSymbol" SG_ 852 TAS_a066_undefinedInstructionAbo "TAS_a066_undefinedInstructionAbort";
BA_ "SystemSignalLongSymbol" SG_ 852 TAS_a150_accelAvgImplausible_FL_ "TAS_a150_accelAvgImplausible_FL_X";
BA_ "SystemSignalLongSymbol" SG_ 852 TAS_a151_accelAvgImplausible_FL_ "TAS_a151_accelAvgImplausible_FL_Y";
BA_ "SystemSignalLongSymbol" SG_ 852 TAS_a152_accelAvgImplausible_FL_ "TAS_a152_accelAvgImplausible_FL_Z";
BA_ "SystemSignalLongSymbol" SG_ 852 TAS_a153_accelAvgImplausible_FR_ "TAS_a153_accelAvgImplausible_FR_X";
BA_ "SystemSignalLongSymbol" SG_ 852 TAS_a154_accelAvgImplausible_FR_ "TAS_a154_accelAvgImplausible_FR_Y";
BA_ "SystemSignalLongSymbol" SG_ 852 TAS_a155_accelAvgImplausible_FR_ "TAS_a155_accelAvgImplausible_FR_Z";
BA_ "SystemSignalLongSymbol" SG_ 852 TAS_a156_accelAvgImplausible_RL_ "TAS_a156_accelAvgImplausible_RL_X";
BA_ "SystemSignalLongSymbol" SG_ 852 TAS_a157_accelAvgImplausible_RL_ "TAS_a157_accelAvgImplausible_RL_Y";
BA_ "SystemSignalLongSymbol" SG_ 852 TAS_a158_accelAvgImplausible_RL_ "TAS_a158_accelAvgImplausible_RL_Z";
BA_ "SystemSignalLongSymbol" SG_ 852 TAS_a159_accelAvgImplausible_RR_ "TAS_a159_accelAvgImplausible_RR_X";
BA_ "SystemSignalLongSymbol" SG_ 852 TAS_a160_accelAvgImplausible_RR_ "TAS_a160_accelAvgImplausible_RR_Y";
BA_ "SystemSignalLongSymbol" SG_ 852 TAS_a161_accelAvgImplausible_RR_ "TAS_a161_accelAvgImplausible_RR_Z";
BA_ "SystemSignalLongSymbol" SG_ 852 TAS_a192_rideHeightObserverDiver "TAS_a192_rideHeightObserverDivergence";
BA_ "SystemSignalLongSymbol" SG_ 852 TAS_a197_invalidAdaptiveModeRequ "TAS_a197_invalidAdaptiveModeRequested";
BA_ "Confidence" SG_ 523 TAS_axleIndex 1;
BA_ "Confidence" SG_ 523 TAS_rawHeightFL 0;
BA_ "GenSigSNA" SG_ 523 TAS_rawHeightFL "1023";
BA_ "Confidence" SG_ 523 TAS_staticHeightEstimateFL 0;
BA_ "GenSigSNA" SG_ 523 TAS_staticHeightEstimateFL "1023";
BA_ "Confidence" SG_ 523 TAS_componentPressureFL 0;
BA_ "GenSigSNA" SG_ 523 TAS_componentPressureFL "255";
BA_ "Confidence" SG_ 523 TAS_rawHeightFR 0;
BA_ "GenSigSNA" SG_ 523 TAS_rawHeightFR "1023";
BA_ "Confidence" SG_ 523 TAS_staticHeightEstimateFR 0;
BA_ "GenSigSNA" SG_ 523 TAS_staticHeightEstimateFR "1023";
BA_ "Confidence" SG_ 523 TAS_componentPressureFR 0;
BA_ "GenSigSNA" SG_ 523 TAS_componentPressureFR "255";
BA_ "Confidence" SG_ 523 TAS_rawHeightRL 0;
BA_ "GenSigSNA" SG_ 523 TAS_rawHeightRL "1023";
BA_ "Confidence" SG_ 523 TAS_staticHeightEstimateRL 0;
BA_ "GenSigSNA" SG_ 523 TAS_staticHeightEstimateRL "1023";
BA_ "Confidence" SG_ 523 TAS_componentPressureRL 0;
BA_ "GenSigSNA" SG_ 523 TAS_componentPressureRL "255";
BA_ "Confidence" SG_ 523 TAS_rawHeightRR 0;
BA_ "GenSigSNA" SG_ 523 TAS_rawHeightRR "1023";
BA_ "Confidence" SG_ 523 TAS_staticHeightEstimateRR 0;
BA_ "GenSigSNA" SG_ 523 TAS_staticHeightEstimateRR "1023";
BA_ "Confidence" SG_ 523 TAS_componentPressureRR 0;
BA_ "GenSigSNA" SG_ 523 TAS_componentPressureRR "255";
BA_ "Confidence" SG_ 1398 TAS_endstopState 0;
BA_ "Confidence" SG_ 1398 TAS_continuousControlState 0;
BA_ "Confidence" SG_ 1398 TAS_activeTireTune 0;
BA_ "Confidence" SG_ 1398 TAS_roughnessRaiseReason 0;
BA_ "Confidence" SG_ 1398 TAS_frontMetricDrivesRear 0;
BA_ "Confidence" SG_ 1398 TAS_roadCondition 0;
BA_ "GenSigSNA" SG_ 1398 TAS_roadCondition "255";
BA_ "Confidence" SG_ 1398 TAS_bellyProtect 0;
BA_ "Confidence" SG_ 1398 TAS_frontMetricDrivesFront 0;
BA_ "Confidence" SG_ 1398 TAS_speedBumpAxleFront 0;
BA_ "Confidence" SG_ 1398 TAS_speedBumpAxleRear 0;
BA_ "Confidence" SG_ 1398 TAS_holeProtectFL 0;
BA_ "Confidence" SG_ 1398 TAS_holeProtectFR 0;
BA_ "Confidence" SG_ 1398 TAS_holeProtectRL 0;
BA_ "Confidence" SG_ 1398 TAS_holeProtectRR 0;
BA_ "Confidence" SG_ 1398 TAS_stepProtectFL 0;
BA_ "Confidence" SG_ 1398 TAS_stepProtectFR 0;
BA_ "Confidence" SG_ 1398 TAS_stepProtectRL 0;
BA_ "Confidence" SG_ 1398 TAS_stepProtectRR 0;
BA_ "Confidence" SG_ 1398 TAS_FDUTorqueCorruptionScale 0;
BA_ "GenSigSNA" SG_ 1398 TAS_FDUTorqueCorruptionScale "15";
BA_ "Confidence" SG_ 1398 TAS_sprungMassEstimate 0;
BA_ "GenSigSNA" SG_ 1398 TAS_sprungMassEstimate "31";
BA_ "Confidence" SG_ 1398 TAS_anyDamperActive 0;
BA_ "Confidence" SG_ 1398 TAS_dampingStatesCounter 0;
BA_ "Confidence" SG_ 1398 TAS_dampingStatesChecksum 0;
BA_ "Confidence" SG_ 1357 TAS_infoIndex 1;
BA_ "Confidence" SG_ 1357 TAS_infoBuildType 0;
BA_ "Confidence" SG_ 1357 TAS_infoBuildConfigId 0;
BA_ "Confidence" SG_ 1357 TAS_infoHardwareId 0;
BA_ "Confidence" SG_ 1357 TAS_infoComponentId 0;
BA_ "Confidence" SG_ 1357 TAS_infoPcbaId 0;
BA_ "Confidence" SG_ 1357 TAS_infoAssemblyId 0;
BA_ "GenSigSNA" SG_ 1357 TAS_infoAssemblyId "255";
BA_ "Confidence" SG_ 1357 TAS_infoUsageId 0;
BA_ "Confidence" SG_ 1357 TAS_infoSubUsageId 0;
BA_ "Confidence" SG_ 1357 TAS_infoAppCrc 0;
BA_ "Confidence" SG_ 1357 TAS_infoAppGitHash 0;
BA_ "Confidence" SG_ 1357 TAS_infoBootGitHash 0;
BA_ "Confidence" SG_ 1357 TAS_infoPlatformType 0;
BA_ "Confidence" SG_ 1357 TAS_infoMajorVersion 0;
BA_ "GenSigSNA" SG_ 1357 TAS_infoMajorVersion "255";
BA_ "Confidence" SG_ 1357 TAS_infoBranchOrigin 0;
BA_ "GenSigSNA" SG_ 1357 TAS_infoBranchOrigin "255";
BA_ "Confidence" SG_ 1357 TAS_infoMaturity 0;
BA_ "GenSigSNA" SG_ 1357 TAS_infoMaturity "255";
BA_ "Confidence" SG_ 1357 TAS_infoHardwareRevision 0;
BA_ "GenSigSNA" SG_ 1357 TAS_infoHardwareRevision "255";
BA_ "Confidence" SG_ 525 TAS_levelingState 0;
BA_ "Confidence" SG_ 525 TAS_levelingItem 0;
BA_ "Confidence" SG_ 525 TAS_pressureGallery 0;
BA_ "GenSigSNA" SG_ 525 TAS_pressureGallery "255";
BA_ "Confidence" SG_ 525 TAS_pressureReservoir 0;
BA_ "GenSigSNA" SG_ 525 TAS_pressureReservoir "255";
BA_ "Confidence" SG_ 525 TAS_runMode 0;
BA_ "Confidence" SG_ 525 TAS_filterMode 0;
BA_ "Confidence" SG_ 525 TAS_compressorRun 0;
BA_ "Confidence" SG_ 525 TAS_twistDetected 0;
BA_ "Confidence" SG_ 525 TAS_leanDetected 0;
BA_ "Confidence" SG_ 525 TAS_limpHomeMode 0;
BA_ "Confidence" SG_ 525 TAS_targetLevel 0;
BA_ "Confidence" SG_ 525 TAS_currentLevel 0;
BA_ "Confidence" SG_ 525 TAS_jackMode 0;
BA_ "Confidence" SG_ 525 TAS_reduceVehicleSpeedRequest 0;
BA_ "Confidence" SG_ 525 TAS_statesCounter 0;
BA_ "Confidence" SG_ 525 TAS_statesChecksum 0;
BA_ "Confidence" SG_ 409 TAS_adaptiveActivityFL_C 0;
BA_ "GenSigSNA" SG_ 409 TAS_adaptiveActivityFL_C "31";
BA_ "Confidence" SG_ 409 TAS_adaptiveActivityFL_R 0;
BA_ "GenSigSNA" SG_ 409 TAS_adaptiveActivityFL_R "31";
BA_ "Confidence" SG_ 409 TAS_adaptiveActivityFR_C 0;
BA_ "GenSigSNA" SG_ 409 TAS_adaptiveActivityFR_C "31";
BA_ "Confidence" SG_ 409 TAS_adaptiveActivityFR_R 0;
BA_ "GenSigSNA" SG_ 409 TAS_adaptiveActivityFR_R "31";
BA_ "Confidence" SG_ 409 TAS_adaptiveActivityRL_C 0;
BA_ "GenSigSNA" SG_ 409 TAS_adaptiveActivityRL_C "31";
BA_ "Confidence" SG_ 409 TAS_adaptiveActivityRL_R 0;
BA_ "GenSigSNA" SG_ 409 TAS_adaptiveActivityRL_R "31";
BA_ "Confidence" SG_ 409 TAS_adaptiveActivityRR_C 0;
BA_ "GenSigSNA" SG_ 409 TAS_adaptiveActivityRR_C "31";
BA_ "Confidence" SG_ 409 TAS_adaptiveActivityRR_R 0;
BA_ "GenSigSNA" SG_ 409 TAS_adaptiveActivityRR_R "31";
BA_ "Confidence" SG_ 409 TAS_uiHeightFL 0;
BA_ "GenSigSNA" SG_ 409 TAS_uiHeightFL "63";
BA_ "Confidence" SG_ 409 TAS_uiHeightFR 0;
BA_ "GenSigSNA" SG_ 409 TAS_uiHeightFR "63";
BA_ "Confidence" SG_ 409 TAS_uiHeightRL 0;
BA_ "GenSigSNA" SG_ 409 TAS_uiHeightRL "63";
BA_ "Confidence" SG_ 409 TAS_uiHeightRR 0;
BA_ "GenSigSNA" SG_ 409 TAS_uiHeightRR "63";
BA_ "Confidence" SG_ 410 TAS_bodyAccelFL 0;
BA_ "GenSigSNA" SG_ 410 TAS_bodyAccelFL "255";
BA_ "Confidence" SG_ 410 TAS_bodyAccelFR 0;
BA_ "GenSigSNA" SG_ 410 TAS_bodyAccelFR "255";
BA_ "Confidence" SG_ 410 TAS_bodyAccelRL 0;
BA_ "GenSigSNA" SG_ 410 TAS_bodyAccelRL "255";
BA_ "Confidence" SG_ 410 TAS_bodyAccelRR 0;
BA_ "GenSigSNA" SG_ 410 TAS_bodyAccelRR "255";
BA_ "Confidence" SG_ 538 TAS_yellowWarningLamp 0;
BA_ "Confidence" SG_ 538 TAS_redWarningLamp 0;
BA_ "Confidence" SG_ 538 TAS_veryLowAllowed 0;
BA_ "Confidence" SG_ 538 TAS_lowAllowed 0;
BA_ "Confidence" SG_ 538 TAS_standardAllowed 0;
BA_ "Confidence" SG_ 538 TAS_highAllowed 0;
BA_ "Confidence" SG_ 538 TAS_veryHighAllowed 0;
BA_ "Confidence" SG_ 538 TAS_extractAllowed 0;
BA_ "Confidence" SG_ 538 TAS_showSpinner 0;
BA_ "Confidence" SG_ 538 TAS_adaptiveRideModeOverride 0;
BA_ "GenSigSNA" SG_ 538 TAS_adaptiveRideModeOverride "3";
BA_ "Confidence" SG_ 538 TAS_levelSelectEnabled 0;
BA_ "Confidence" SG_ 538 TAS_jackModeToggleEnabled 0;
BA_ "Confidence" SG_ 538 TAS_adaptiveRideSelectEnabled 0;
BA_ "Confidence" SG_ 538 TAS_launchModeState 0;
BA_ "Confidence" SG_ 538 TAS_restrictUpLevelingFalcons 0;
BA_ "Confidence" SG_ 538 TAS_restrictUpLevelingTrunk 0;
BA_ "Confidence" SG_ 538 TAS_restrictDownLevelingDoors 0;
BA_ "Confidence" SG_ 538 TAS_restrictLevelingChargeCable 0;
BA_ "Confidence" SG_ 538 TAS_restrictLevelingSystemCheck 0;
BA_ "Confidence" SG_ 538 TAS_restrictLevelingTransport 0;
BA_ "Confidence" SG_ 538 TAS_restrictLevelingShowroom 0;
BA_ "Confidence" SG_ 538 TAS_uiControlCounter 0;
BA_ "Confidence" SG_ 538 TAS_uiControlChecksum 0;
BA_ "Confidence" SG_ 1657 UI_rgbEnableState 0;
BA_ "Confidence" SG_ 1657 UI_rgbEffectType 0;
BA_ "Confidence" SG_ 1657 UI_rgbBrightnessLevel 0;
BA_ "GenSigSNA" SG_ 1657 UI_rgbBrightnessLevel "127";
BA_ "Confidence" SG_ 1657 UI_rgbTargetDOORFL 0;
BA_ "Confidence" SG_ 1657 UI_rgbTargetDOORFR 0;
BA_ "Confidence" SG_ 1657 UI_rgbTargetDOORRL 0;
BA_ "Confidence" SG_ 1657 UI_rgbTargetDOORRR 0;
BA_ "Confidence" SG_ 1657 UI_rgbTargetIPFL 0;
BA_ "Confidence" SG_ 1657 UI_rgbTargetIPFR 0;
BA_ "Confidence" SG_ 1021 UI_autopilotControlIndex 1;
BA_ "Confidence" SG_ 1021 UI_hovEnabled 0;
BA_ "Confidence" SG_ 1021 UI_donDisableAutoWiperDuration 1;
BA_ "Confidence" SG_ 1021 UI_donDisableOnAutoWiperSpeed 1;
BA_ "Confidence" SG_ 1021 UI_blindspotMinSpeed 1;
BA_ "Confidence" SG_ 1021 UI_blindspotDistance 1;
BA_ "Confidence" SG_ 1021 UI_blindspotTTC 1;
BA_ "Confidence" SG_ 1021 UI_donStopEndOfRampBuffer 1;
BA_ "Confidence" SG_ 1021 UI_donDisableCutin 1;
BA_ "Confidence" SG_ 1021 UI_smartSetSpeedOffset 0;
BA_ "Confidence" SG_ 1021 UI_smartSetSpeedOffsetType 0;
BA_ "Confidence" SG_ 1021 UI_fsdStopsControlEnabled 0;
BA_ "Confidence" SG_ 1021 UI_smartSetSpeed 0;
BA_ "Confidence" SG_ 1021 UI_automaticSetSpeedOffset 0;
BA_ "Confidence" SG_ 1021 UI_homelinkNearby 1;
BA_ "Confidence" SG_ 1021 UI_enableFullSelfDriving 0;
BA_ "Confidence" SG_ 1021 UI_hasFullSelfDriving 0;
BA_ "Confidence" SG_ 1021 UI_autosteerActivation 0;
BA_ "Confidence" SG_ 1021 UI_autopilotDrivingProfile 1;
BA_ "Confidence" SG_ 1021 UI_fsdBetaRequest 0;
BA_ "Confidence" SG_ 1021 UI_fullSelfDrivingSuspended 0;
BA_ "Confidence" SG_ 1021 UI_disableOptionalLaneChanges 0;
BA_ "Confidence" SG_ 1021 UI_selectableCameraRequest 0;
BA_ "GenSigSNA" SG_ 1021 UI_selectableCameraRequest "15";
BA_ "Confidence" SG_ 1021 UI_overrideSleepWithSuspend 1;
BA_ "Confidence" SG_ 1021 UI_driverMonitorConfirmation 0;
BA_ "Confidence" SG_ 1021 UI_parkAssistUseVision 0;
BA_ "Confidence" SG_ 1021 UI_noStalkConfirmAlertHaptic 0;
BA_ "Confidence" SG_ 1021 UI_regulatoryLaneAssistLevel 1;
BA_ "Confidence" SG_ 1021 UI_noStalkConfirmAlertChime 0;
BA_ "Confidence" SG_ 1021 UI_factorySummonEnable 0;
BA_ "Confidence" SG_ 1021 UI_apmv3Branch 1;
BA_ "Confidence" SG_ 1021 UI_enableCabinCamera 0;
BA_ "Confidence" SG_ 1021 UI_enableAutopilotStopWarning 0;
BA_ "Confidence" SG_ 1021 UI_enableVisionSpeedControl 0;
BA_ "Confidence" SG_ 1021 UI_enableTeslaAutopark 0;
BA_ "Confidence" SG_ 1021 UI_autoTurnSignalMode 0;
BA_ "Confidence" SG_ 1021 UI_enableCabinAudioRecording 0;
BA_ "SystemSignalLongSymbol" SG_ 1021 UI_enableApproachingEmergencyVeh "UI_enableApproachingEmergencyVehicleDetection";
BA_ "SystemSignalLongSymbol" SG_ 1021 UI_enableStartFsdFromParkBrakeCo "UI_enableStartFsdFromParkBrakeConfirmation";
BA_ "Confidence" SG_ 1021 UI_fsdMaxSpeedOffsetPercentage 1;
BA_ "Confidence" SG_ 819 UI_openChargePortDoorRequest 0;
BA_ "Confidence" SG_ 819 UI_closeChargePortDoorRequest 0;
BA_ "Confidence" SG_ 819 UI_chargeEnableRequest 0;
BA_ "Confidence" SG_ 819 UI_brickVLoggingRequest 1;
BA_ "Confidence" SG_ 819 UI_brickBalancingDisabled 1;
BA_ "Confidence" SG_ 819 UI_dSocAlertThreshold 1;
BA_ "Confidence" SG_ 819 UI_acChargeCurrentLimit 0;
BA_ "GenSigSNA" SG_ 819 UI_acChargeCurrentLimit "127";
BA_ "Confidence" SG_ 819 UI_dSocAlertEnable 1;
BA_ "Confidence" SG_ 819 UI_chargeTerminationPct 0;
BA_ "Confidence" SG_ 819 UI_scheduledDepartureEnabled 0;
BA_ "Confidence" SG_ 819 UI_chargePortLatchRequest 0;
BA_ "Confidence" SG_ 819 UI_socSnapshotExpirationTime 1;
BA_ "Confidence" SG_ 819 UI_cpInletHeaterRequest 0;
BA_ "Confidence" SG_ 659 UI_steeringTuneRequest 0;
BA_ "Confidence" SG_ 659 UI_tractionControlMode 0;
BA_ "Confidence" SG_ 659 UI_parkBrakeRequest 0;
BA_ "GenSigSNA" SG_ 659 UI_parkBrakeRequest "3";
BA_ "Confidence" SG_ 659 UI_winchModeRequest 0;
BA_ "Confidence" SG_ 659 UI_zeroSpeedConfirmed 1;
BA_ "GenSigSNA" SG_ 659 UI_zeroSpeedConfirmed "3";
BA_ "Confidence" SG_ 659 UI_trailerMode 0;
BA_ "Confidence" SG_ 659 UI_distanceUnits 1;
BA_ "Confidence" SG_ 659 UI_accOvertakeEnable 0;
BA_ "GenSigSNA" SG_ 659 UI_accOvertakeEnable "3";
BA_ "Confidence" SG_ 659 UI_aebEnable 0;
BA_ "GenSigSNA" SG_ 659 UI_aebEnable "3";
BA_ "Confidence" SG_ 659 UI_aesEnable 0;
BA_ "GenSigSNA" SG_ 659 UI_aesEnable "3";
BA_ "Confidence" SG_ 659 UI_ahlbEnable 0;
BA_ "GenSigSNA" SG_ 659 UI_ahlbEnable "3";
BA_ "Confidence" SG_ 659 UI_autoLaneChangeEnable 0;
BA_ "GenSigSNA" SG_ 659 UI_autoLaneChangeEnable "3";
BA_ "Confidence" SG_ 659 UI_winchProxUserOverride 0;
BA_ "Confidence" SG_ 659 UI_autoParkRequest 0;
BA_ "GenSigSNA" SG_ 659 UI_autoParkRequest "15";
BA_ "Confidence" SG_ 659 UI_bsdEnable 0;
BA_ "GenSigSNA" SG_ 659 UI_bsdEnable "3";
BA_ "Confidence" SG_ 659 UI_fcwEnable 0;
BA_ "GenSigSNA" SG_ 659 UI_fcwEnable "3";
BA_ "Confidence" SG_ 659 UI_fcwSensitivity 0;
BA_ "GenSigSNA" SG_ 659 UI_fcwSensitivity "3";
BA_ "Confidence" SG_ 659 UI_latControlEnable 0;
BA_ "GenSigSNA" SG_ 659 UI_latControlEnable "3";
BA_ "Confidence" SG_ 659 UI_ldwEnable 0;
BA_ "GenSigSNA" SG_ 659 UI_ldwEnable "3";
BA_ "Confidence" SG_ 659 UI_pedalSafetyEnable 1;
BA_ "GenSigSNA" SG_ 659 UI_pedalSafetyEnable "3";
BA_ "Confidence" SG_ 659 UI_pedalMap_epas 1;
BA_ "Confidence" SG_ 659 UI_redLightStopSignEnable 1;
BA_ "GenSigSNA" SG_ 659 UI_redLightStopSignEnable "3";
BA_ "Confidence" SG_ 659 UI_selfParkTune 1;
BA_ "GenSigSNA" SG_ 659 UI_selfParkTune "15";
BA_ "Confidence" SG_ 531 UI_cruiseSpeedCommand 0;
BA_ "Confidence" SG_ 1280 UI_debugEcuTarget 1;
BA_ "Confidence" SG_ 2043 UI_debugDampingRequestFLC 1;
BA_ "GenSigSNA" SG_ 2043 UI_debugDampingRequestFLC "255";
BA_ "Confidence" SG_ 2043 UI_debugDampingRequestFLR 1;
BA_ "GenSigSNA" SG_ 2043 UI_debugDampingRequestFLR "255";
BA_ "Confidence" SG_ 2043 UI_debugDampingRequestFRC 1;
BA_ "GenSigSNA" SG_ 2043 UI_debugDampingRequestFRC "255";
BA_ "Confidence" SG_ 2043 UI_debugDampingRequestFRR 1;
BA_ "GenSigSNA" SG_ 2043 UI_debugDampingRequestFRR "255";
BA_ "Confidence" SG_ 2043 UI_debugDampingRequestRLC 1;
BA_ "GenSigSNA" SG_ 2043 UI_debugDampingRequestRLC "255";
BA_ "Confidence" SG_ 2043 UI_debugDampingRequestRLR 1;
BA_ "GenSigSNA" SG_ 2043 UI_debugDampingRequestRLR "255";
BA_ "Confidence" SG_ 2043 UI_debugDampingRequestRRC 1;
BA_ "GenSigSNA" SG_ 2043 UI_debugDampingRequestRRC "255";
BA_ "Confidence" SG_ 2043 UI_debugDampingRequestRRR 1;
BA_ "GenSigSNA" SG_ 2043 UI_debugDampingRequestRRR "255";
BA_ "Confidence" SG_ 568 UI_mapSpeedLimitDependency 1;
BA_ "GenSigSNA" SG_ 568 UI_mapSpeedLimitDependency "7";
BA_ "Confidence" SG_ 568 UI_roadClass 0;
BA_ "GenSigSNA" SG_ 568 UI_roadClass "0";
BA_ "Confidence" SG_ 568 UI_mapSpeedUnits 1;
BA_ "Confidence" SG_ 568 UI_mapSpeedLimit 1;
BA_ "GenSigSNA" SG_ 568 UI_mapSpeedLimit "31";
BA_ "Confidence" SG_ 568 UI_mapSpeedLimitType 1;
BA_ "GenSigSNA" SG_ 568 UI_mapSpeedLimitType "7";
BA_ "Confidence" SG_ 568 UI_countryCode 1;
BA_ "GenSigSNA" SG_ 568 UI_countryCode "1023";
BA_ "Confidence" SG_ 568 UI_navRouteActive 0;
BA_ "Confidence" SG_ 568 UI_parallelAutoparkEnabled 0;
BA_ "Confidence" SG_ 568 UI_perpendicularAutoparkEnabled 0;
BA_ "Confidence" SG_ 568 UI_nextBranchDist 1;
BA_ "GenSigSNA" SG_ 568 UI_nextBranchDist "31";
BA_ "Confidence" SG_ 568 UI_controlledAccess 0;
BA_ "Confidence" SG_ 568 UI_autosteerRestricted 0;
BA_ "Confidence" SG_ 645 UI_driverProfileRecallIndex 1;
BA_ "GenSigSNA" SG_ 645 UI_driverProfileRecallIndex "0";
BA_ "Confidence" SG_ 645 UI_driverProfileRecallStop 0;
BA_ "Confidence" SG_ 645 UI_frontSeatRecallActive 0;
BA_ "Confidence" SG_ 645 UI_frontSeatTrackPos 1;
BA_ "Confidence" SG_ 645 UI_frontSeatBackPos 1;
BA_ "Confidence" SG_ 645 UI_frontSeatLiftPos 1;
BA_ "Confidence" SG_ 645 UI_frontSeatTiltPos 1;
BA_ "Confidence" SG_ 645 UI_steeringColumnUpDownPos 1;
BA_ "Confidence" SG_ 645 UI_steeringColumnInOutPos 1;
BA_ "Confidence" SG_ 645 UI_leftMirrorTiltXPosition 0;
BA_ "Confidence" SG_ 645 UI_leftMirrorTiltYPosition 0;
BA_ "Confidence" SG_ 645 UI_rightMirrorTiltXPosition 1;
BA_ "Confidence" SG_ 645 UI_rightMirrorTiltYPosition 1;
BA_ "Confidence" SG_ 645 UI_customMirrorDipPositionsSet 0;
BA_ "Confidence" SG_ 645 UI_leftMirrorDipXPosition 0;
BA_ "Confidence" SG_ 645 UI_leftMirrorDipYPosition 0;
BA_ "Confidence" SG_ 645 UI_rightMirrorDipXPosition 1;
BA_ "Confidence" SG_ 645 UI_rightMirrorDipYPosition 1;
BA_ "Confidence" SG_ 645 UI_modifyMirrorDipRequest 0;
BA_ "Confidence" SG_ 651 UI_driverProfileLinkedKeySHA1 1;
BA_ "GenSigSNA" SG_ 651 UI_driverProfileLinkedKeySHA1 "4294967295";
BA_ "Confidence" SG_ 651 UI_driverProfileIndex 0;
BA_ "Confidence" SG_ 651 UI_driverProfileSelectionType 0;
BA_ "Confidence" SG_ 651 UI_driverProfilePositionAdjusted 0;
BA_ "Confidence" SG_ 651 UI_activeKeyRequested 0;
BA_ "Confidence" SG_ 984 UI_elevation 1;
BA_ "GenSigSNA" SG_ 984 UI_elevation "8191";
BA_ "Confidence" SG_ 984 UI_navElevation 1;
BA_ "GenSigSNA" SG_ 984 UI_navElevation "8191";
BA_ "Confidence" SG_ 1139 UI_nmKeepAwakeReason 1;
BA_ "GenSigSNA" SG_ 1139 UI_nmKeepAwakeReason "0";
BA_ "Confidence" SG_ 1139 UI_wakeupTime 0;
BA_ "Confidence" SG_ 883 UI_gpsHDOP 1;
BA_ "Confidence" SG_ 883 UI_gpsVehicleHeading 1;
BA_ "Confidence" SG_ 883 UI_gpsVehicleSpeed 1;
BA_ "Confidence" SG_ 883 UI_userSpeedOffset 1;
BA_ "Confidence" SG_ 883 UI_mapSpeedLimitUnits 0;
BA_ "Confidence" SG_ 883 UI_userSpeedOffsetUnits 1;
BA_ "Confidence" SG_ 883 UI_mppSpeedLimit 0;
BA_ "Confidence" SG_ 883 UI_gpsNmeaMIA 0;
BA_ "Confidence" SG_ 883 UI_gpsAntennaDisconnected 0;
BA_ "Confidence" SG_ 883 UI_conditionalLimitActive 0;
BA_ "Confidence" SG_ 883 UI_conditionalSpeedLimit 0;
BA_ "GenSigSNA" SG_ 883 UI_conditionalSpeedLimit "31";
BA_ "Confidence" SG_ 755 UI_hvacReqTempSetpointLeft 0;
BA_ "Confidence" SG_ 755 UI_hvacReqAutoBlowerLevel 0;
BA_ "Confidence" SG_ 755 UI_hvacReqTempSetpointRight 0;
BA_ "Confidence" SG_ 755 UI_hvacReqAirDistributionMode 0;
BA_ "Confidence" SG_ 755 UI_hvacReqBlowerSegment 0;
BA_ "Confidence" SG_ 755 UI_hvacReqRecirc 0;
BA_ "Confidence" SG_ 755 UI_hvacReqACDisable 0;
BA_ "Confidence" SG_ 755 UI_hvacDefogState 0;
BA_ "Confidence" SG_ 755 UI_hvacReqUserPowerState 0;
BA_ "Confidence" SG_ 755 UI_hvacReqSecondRowState 0;
BA_ "Confidence" SG_ 755 UI_hvacReqKeepClimateOn 0;
BA_ "Confidence" SG_ 755 UI_hvacReqBioWeaponDefMode 0;
BA_ "SystemSignalLongSymbol" SG_ 755 UI_hvacPhoneCallAirFlowAdjustEna "UI_hvacPhoneCallAirFlowAdjustEnabled";
BA_ "SystemSignalLongSymbol" SG_ 755 UI_enableHvacWeatherDataBasedHum "UI_enableHvacWeatherDataBasedHumidityControls";
BA_ "Confidence" SG_ 755 UI_hvacReqTempSetpointCOP 0;
BA_ "Confidence" SG_ 755 UI_hvacClimateNudgeStatus 1;
BA_ "Confidence" SG_ 777 UI_latitude 1;
BA_ "Confidence" SG_ 777 UI_longitude 1;
BA_ "Confidence" SG_ 777 UI_gpsAccuracy 1;
BA_ "GenSigSNA" SG_ 777 UI_gpsAccuracy "127";
VAL_ 1291 TAS_alertID 333 "a333_levelingThresholds2" 332 "a332_levelingThresholds1" 322 "a322_speedBumpAttributes2" 321 "a321_speedBumpAttributes1" 320 "a320_offsetsRotationalRates" 319 "a319_drivetrainTypeMismatch" 318 "a318_dampingCntrlInputMIA" 317 "a317_offsetsRotationalRates" 316 "a316_offsetsAccels" 315 "a315_pcbaHighTemp" 314 "a314_dampingReduced" 313 "a313_dampingCntrlDisabled" 312 "a312_rotationalRatesMIA" 311 "a311_accelsMIA" 310 "a310_controlFrozenData" 309 "a309_controlFrozen" 308 "a308_endstopBoundaryRbnd" 307 "a307_endstopBoundaryComp" 306 "a306_hardwareProtectFrozen" 305 "a305_newEndstopPosition" 304 "a304_massEstimateFrozenData" 303 "a303_massEstimateFrozen" 301 "a301_offsetEstimateData2" 300 "a300_offsetEstimateData1" 299 "a299_offsetEstimateTooLarge" 298 "a298_vinNotLearned" 297 "a297_vinMismatch" 296 "a296_chassisTypeMismatch" 295 "a295_targetHeightNotMet" 294 "a294_rearAxleTooLow" 293 "a293_frontAxleTooLow" 292 "a292_rearAxleTooHigh" 291 "a291_frontAxleTooHigh" 290 "a290_twistSustainedAtSpeed" 289 "a289_driveCycleStats4" 288 "a288_driveCycleStats3" 287 "a287_driveCycleStats2" 286 "a286_driveCycleStats1" 285 "a285_twistSustainedUserVis" 284 "a284_serviceRunModeActive" 240 "a240_airSpringLeak" 234 "a234_damperHydraulicMismatch" 233 "a233_compressorStuckOn" 232 "a232_suspensionTypeMismatch" 231 "a231_notifyRoughRoadRaise" 230 "a230_notifyGeofence" 229 "a229_PWMfastDetectRR" 228 "a228_PWMfastDetectRL" 227 "a227_PWMfastDetectFR" 226 "a226_PWMfastDetectFL" 225 "a225_galleryPressureTooHigh" 224 "a224_openAirline" 223 "a223_blockedAirline" 222 "a222_compressorPrefillFault" 221 "a221_valveLeakDetected" 220 "a220_exhaustGalleryFault" 218 "a218_limpHomeMode40" 217 "a217_limpHomeMode30" 216 "a216_limpHomeMode20" 215 "a215_limpHomeMode10" 214 "a214_redWarningLamp" 213 "a213_yellowWarningLamp" 211 "a211_noRideHeightCalib" 210 "a210_outOfRangeCalibration" 201 "a201_low12VBattery" 200 "a200_jackModeActive" 197 "a197_invalidAdaptiveModeRequested" 196 "a196_adaptiveDampingUsingDSP" 195 "a195_a2bRearAxleDataError" 194 "a194_a2bFrontAxleDataError" 193 "a193_EPAS3P_MIA" 192 "a192_rideHeightObserverDivergence" 191 "a191_a2bRearAxleFault" 190 "a190_a2bFrontAxleFault" 176 "a176_staticLeakDetectRR" 175 "a175_staticLeakDetectRL" 174 "a174_staticLeakDetectFR" 173 "a173_staticLeakDetectFL" 172 "a172_damperValveRbndRR" 171 "a171_damperValveCompRR" 170 "a170_damperValveRbndRL" 169 "a169_damperValveCompRL" 168 "a168_damperValveRbndFR" 167 "a167_damperValveCompFR" 166 "a166_damperValveRbndFL" 165 "a165_damperValveCompFL" 164 "a164_damperSolenoidMismatch" 161 "a161_accelAvgImplausible_RR_Z" 160 "a160_accelAvgImplausible_RR_Y" 159 "a159_accelAvgImplausible_RR_X" 158 "a158_accelAvgImplausible_RL_Z" 157 "a157_accelAvgImplausible_RL_Y" 156 "a156_accelAvgImplausible_RL_X" 155 "a155_accelAvgImplausible_FR_Z" 154 "a154_accelAvgImplausible_FR_Y" 153 "a153_accelAvgImplausible_FR_X" 152 "a152_accelAvgImplausible_FL_Z" 151 "a151_accelAvgImplausible_FL_Y" 150 "a150_accelAvgImplausible_FL_X" 107 "a107_HighStackUsage" 106 "a106_HighCPULoad" 105 "a105_ECUDebugMode" 103 "a103_GTW_MIA" 102 "a102_DI_MIA" 101 "a101_ESP_MIA" 100 "a100_RCM_MIA" 99 "a099_UI_MIA" 98 "a098_VCFRONT_MIA" 93 "a093_OTPError" 87 "a087_overVoltage12VSwtchd" 86 "a086_underVoltage12VSwtchd" 85 "a085_overVoltage5VAnalog" 84 "a084_underVoltage5VAnalog" 83 "a083_shortCircuit5VAnalog" 82 "a082_overVoltage5VHeight" 81 "a081_underVoltage5VHeight" 80 "a080_shortCircuit5VHeight" 78 "a078_pressureSigVTooHigh" 77 "a077_pressureSigVTooLow" 76 "a076_overVoltage5VOffBoard" 75 "a075_underVoltage5VOffBoard" 74 "a074_shortCircuit5VOffBoard" 73 "a073_underVoltage5VOnBoard" 72 "a072_shortCircuit5VOnBoard" 71 "a071_overVoltage12V" 70 "a070_underVoltage12V" 67 "a067_reservedHandlerAbort" 66 "a066_undefinedInstructionAbort" 65 "a065_ahbWriteFault" 64 "a064_abortFaultExt" 63 "a063_abortFault" 62 "a062_XCPWasConnected" 61 "a061_XCPConnected" 46 "a046_Task1000msError" 45 "a045_Task100msError" 44 "a044_Task10msError" 43 "a043_Task1msError" 41 "a041_PWMopenRR" 40 "a040_PWMopenRL" 39 "a039_PWMopenFR" 38 "a038_PWMopenFL" 37 "a037_PWMshortRR" 36 "a036_PWMshortRL" 35 "a035_PWMshortFR" 34 "a034_PWMshortFL" 33 "a033_PWMerrorRR" 32 "a032_PWMerrorRL" 31 "a031_PWMerrorFR" 30 "a030_PWMerrorFL" 25 "a025_CrashEvent" 24 "a024_prefetchAbort" 23 "a023_rtosResetRequested" 22 "a022_TaskInitError" 21 "a021_TaskSchedulerError" 16 "a016_NVMMRecordError" 15 "a015_NVMMError" 12 "a012_CPUReset" 3 "a003_SWAssertion" 2 "a002_PowerLossReset" 1 "a001_WatchdogReset" 0 "ALERT_DO_NOT_USE_ZERO" ;
VAL_ 1291 TAS_alertState 1 "SET" 0 "CLEARED" ;
VAL_ 1291 TAS_a030_PWMfaultFL 9 "NONE" 8 "COUNT" 7 "OPEN_CIRCUIT" 6 "SHORT_CIRCUIT" 5 "MIA" 4 "OVER_MAX_DELTA_DUTY" 3 "UNDER_MIN_PERIOD" 2 "OVER_MAX_PERIOD" 1 "UNDER_MIN_DUTY" 0 "OVER_MAX_DUTY" ;
VAL_ 1291 TAS_a031_PWMfaultFR 9 "NONE" 8 "COUNT" 7 "OPEN_CIRCUIT" 6 "SHORT_CIRCUIT" 5 "MIA" 4 "OVER_MAX_DELTA_DUTY" 3 "UNDER_MIN_PERIOD" 2 "OVER_MAX_PERIOD" 1 "UNDER_MIN_DUTY" 0 "OVER_MAX_DUTY" ;
VAL_ 1291 TAS_a032_PWMfaultRL 9 "NONE" 8 "COUNT" 7 "OPEN_CIRCUIT" 6 "SHORT_CIRCUIT" 5 "MIA" 4 "OVER_MAX_DELTA_DUTY" 3 "UNDER_MIN_PERIOD" 2 "OVER_MAX_PERIOD" 1 "UNDER_MIN_DUTY" 0 "OVER_MAX_DUTY" ;
VAL_ 1291 TAS_a033_PWMfaultRR 9 "NONE" 8 "COUNT" 7 "OPEN_CIRCUIT" 6 "SHORT_CIRCUIT" 5 "MIA" 4 "OVER_MAX_DELTA_DUTY" 3 "UNDER_MIN_PERIOD" 2 "OVER_MAX_PERIOD" 1 "UNDER_MIN_DUTY" 0 "OVER_MAX_DUTY" ;
VAL_ 1291 TAS_a034_PWMfaultFL 9 "NONE" 8 "COUNT" 7 "OPEN_CIRCUIT" 6 "SHORT_CIRCUIT" 5 "MIA" 4 "OVER_MAX_DELTA_DUTY" 3 "UNDER_MIN_PERIOD" 2 "OVER_MAX_PERIOD" 1 "UNDER_MIN_DUTY" 0 "OVER_MAX_DUTY" ;
VAL_ 1291 TAS_a035_PWMfaultFR 9 "NONE" 8 "COUNT" 7 "OPEN_CIRCUIT" 6 "SHORT_CIRCUIT" 5 "MIA" 4 "OVER_MAX_DELTA_DUTY" 3 "UNDER_MIN_PERIOD" 2 "OVER_MAX_PERIOD" 1 "UNDER_MIN_DUTY" 0 "OVER_MAX_DUTY" ;
VAL_ 1291 TAS_a036_PWMfaultRL 9 "NONE" 8 "COUNT" 7 "OPEN_CIRCUIT" 6 "SHORT_CIRCUIT" 5 "MIA" 4 "OVER_MAX_DELTA_DUTY" 3 "UNDER_MIN_PERIOD" 2 "OVER_MAX_PERIOD" 1 "UNDER_MIN_DUTY" 0 "OVER_MAX_DUTY" ;
VAL_ 1291 TAS_a037_PWMfaultRR 9 "NONE" 8 "COUNT" 7 "OPEN_CIRCUIT" 6 "SHORT_CIRCUIT" 5 "MIA" 4 "OVER_MAX_DELTA_DUTY" 3 "UNDER_MIN_PERIOD" 2 "OVER_MAX_PERIOD" 1 "UNDER_MIN_DUTY" 0 "OVER_MAX_DUTY" ;
VAL_ 1291 TAS_a038_PWMfaultFL 9 "NONE" 8 "COUNT" 7 "OPEN_CIRCUIT" 6 "SHORT_CIRCUIT" 5 "MIA" 4 "OVER_MAX_DELTA_DUTY" 3 "UNDER_MIN_PERIOD" 2 "OVER_MAX_PERIOD" 1 "UNDER_MIN_DUTY" 0 "OVER_MAX_DUTY" ;
VAL_ 1291 TAS_a039_PWMfaultFR 9 "NONE" 8 "COUNT" 7 "OPEN_CIRCUIT" 6 "SHORT_CIRCUIT" 5 "MIA" 4 "OVER_MAX_DELTA_DUTY" 3 "UNDER_MIN_PERIOD" 2 "OVER_MAX_PERIOD" 1 "UNDER_MIN_DUTY" 0 "OVER_MAX_DUTY" ;
VAL_ 1291 TAS_a040_PWMfaultRL 9 "NONE" 8 "COUNT" 7 "OPEN_CIRCUIT" 6 "SHORT_CIRCUIT" 5 "MIA" 4 "OVER_MAX_DELTA_DUTY" 3 "UNDER_MIN_PERIOD" 2 "OVER_MAX_PERIOD" 1 "UNDER_MIN_DUTY" 0 "OVER_MAX_DUTY" ;
VAL_ 1291 TAS_a041_PWMfaultRR 9 "NONE" 8 "COUNT" 7 "OPEN_CIRCUIT" 6 "SHORT_CIRCUIT" 5 "MIA" 4 "OVER_MAX_DELTA_DUTY" 3 "UNDER_MIN_PERIOD" 2 "OVER_MAX_PERIOD" 1 "UNDER_MIN_DUTY" 0 "OVER_MAX_DUTY" ;
VAL_ 1291 TAS_a164_detectedDamperSolenoid 4 "NC_COMPRESSION_NC_REBOUND" 3 "NC_COMPRESSION_NO_REBOUND" 2 "NO_COMPRESSION_NC_REBOUND" 1 "NO_COMPRESSION_NO_REBOUND" 0 "UNKNOWN" ;
VAL_ 1291 TAS_a164_expectedDamperSolenoid 4 "NC_COMPRESSION_NC_REBOUND" 3 "NC_COMPRESSION_NO_REBOUND" 2 "NO_COMPRESSION_NC_REBOUND" 1 "NO_COMPRESSION_NO_REBOUND" 0 "UNKNOWN" ;
VAL_ 1291 TAS_a165_damperValveFault 15 "REMOTE_VALVE_FAULTED" 14 "POSTIVE_TO_NEGATIVE_SHORT" 13 "DRIVER_OVER_TEMPERATURE" 12 "FEEDBACK_CURRENT_MIA" 11 "TARGET_CURRENT_MIA" 10 "LOW_SIDE_STATUS_IMPLAUSIBLE" 9 "CURRENT_MISMATCH" 8 "CURRENT_IMPLAUSIBLE" 7 "HIGH_RESISTANCE" 6 "LOW_RESISTANCE" 5 "CROSS_CONNECTION_SHORT" 4 "OPEN_CIRCUIT" 3 "VOLTAGE_ON_CIRCUIT" 2 "SHORT_TO_GND" 1 "SHORT_TO_VBAT" 0 "NONE_UNUSED" ;
VAL_ 1291 TAS_a166_damperValveFault 15 "REMOTE_VALVE_FAULTED" 14 "POSTIVE_TO_NEGATIVE_SHORT" 13 "DRIVER_OVER_TEMPERATURE" 12 "FEEDBACK_CURRENT_MIA" 11 "TARGET_CURRENT_MIA" 10 "LOW_SIDE_STATUS_IMPLAUSIBLE" 9 "CURRENT_MISMATCH" 8 "CURRENT_IMPLAUSIBLE" 7 "HIGH_RESISTANCE" 6 "LOW_RESISTANCE" 5 "CROSS_CONNECTION_SHORT" 4 "OPEN_CIRCUIT" 3 "VOLTAGE_ON_CIRCUIT" 2 "SHORT_TO_GND" 1 "SHORT_TO_VBAT" 0 "NONE_UNUSED" ;
VAL_ 1291 TAS_a167_damperValveFault 15 "REMOTE_VALVE_FAULTED" 14 "POSTIVE_TO_NEGATIVE_SHORT" 13 "DRIVER_OVER_TEMPERATURE" 12 "FEEDBACK_CURRENT_MIA" 11 "TARGET_CURRENT_MIA" 10 "LOW_SIDE_STATUS_IMPLAUSIBLE" 9 "CURRENT_MISMATCH" 8 "CURRENT_IMPLAUSIBLE" 7 "HIGH_RESISTANCE" 6 "LOW_RESISTANCE" 5 "CROSS_CONNECTION_SHORT" 4 "OPEN_CIRCUIT" 3 "VOLTAGE_ON_CIRCUIT" 2 "SHORT_TO_GND" 1 "SHORT_TO_VBAT" 0 "NONE_UNUSED" ;
VAL_ 1291 TAS_a168_damperValveFault 15 "REMOTE_VALVE_FAULTED" 14 "POSTIVE_TO_NEGATIVE_SHORT" 13 "DRIVER_OVER_TEMPERATURE" 12 "FEEDBACK_CURRENT_MIA" 11 "TARGET_CURRENT_MIA" 10 "LOW_SIDE_STATUS_IMPLAUSIBLE" 9 "CURRENT_MISMATCH" 8 "CURRENT_IMPLAUSIBLE" 7 "HIGH_RESISTANCE" 6 "LOW_RESISTANCE" 5 "CROSS_CONNECTION_SHORT" 4 "OPEN_CIRCUIT" 3 "VOLTAGE_ON_CIRCUIT" 2 "SHORT_TO_GND" 1 "SHORT_TO_VBAT" 0 "NONE_UNUSED" ;
VAL_ 1291 TAS_a169_damperValveFault 15 "REMOTE_VALVE_FAULTED" 14 "POSTIVE_TO_NEGATIVE_SHORT" 13 "DRIVER_OVER_TEMPERATURE" 12 "FEEDBACK_CURRENT_MIA" 11 "TARGET_CURRENT_MIA" 10 "LOW_SIDE_STATUS_IMPLAUSIBLE" 9 "CURRENT_MISMATCH" 8 "CURRENT_IMPLAUSIBLE" 7 "HIGH_RESISTANCE" 6 "LOW_RESISTANCE" 5 "CROSS_CONNECTION_SHORT" 4 "OPEN_CIRCUIT" 3 "VOLTAGE_ON_CIRCUIT" 2 "SHORT_TO_GND" 1 "SHORT_TO_VBAT" 0 "NONE_UNUSED" ;
VAL_ 1291 TAS_a170_damperValveFault 15 "REMOTE_VALVE_FAULTED" 14 "POSTIVE_TO_NEGATIVE_SHORT" 13 "DRIVER_OVER_TEMPERATURE" 12 "FEEDBACK_CURRENT_MIA" 11 "TARGET_CURRENT_MIA" 10 "LOW_SIDE_STATUS_IMPLAUSIBLE" 9 "CURRENT_MISMATCH" 8 "CURRENT_IMPLAUSIBLE" 7 "HIGH_RESISTANCE" 6 "LOW_RESISTANCE" 5 "CROSS_CONNECTION_SHORT" 4 "OPEN_CIRCUIT" 3 "VOLTAGE_ON_CIRCUIT" 2 "SHORT_TO_GND" 1 "SHORT_TO_VBAT" 0 "NONE_UNUSED" ;
VAL_ 1291 TAS_a171_damperValveFault 15 "REMOTE_VALVE_FAULTED" 14 "POSTIVE_TO_NEGATIVE_SHORT" 13 "DRIVER_OVER_TEMPERATURE" 12 "FEEDBACK_CURRENT_MIA" 11 "TARGET_CURRENT_MIA" 10 "LOW_SIDE_STATUS_IMPLAUSIBLE" 9 "CURRENT_MISMATCH" 8 "CURRENT_IMPLAUSIBLE" 7 "HIGH_RESISTANCE" 6 "LOW_RESISTANCE" 5 "CROSS_CONNECTION_SHORT" 4 "OPEN_CIRCUIT" 3 "VOLTAGE_ON_CIRCUIT" 2 "SHORT_TO_GND" 1 "SHORT_TO_VBAT" 0 "NONE_UNUSED" ;
VAL_ 1291 TAS_a172_damperValveFault 15 "REMOTE_VALVE_FAULTED" 14 "POSTIVE_TO_NEGATIVE_SHORT" 13 "DRIVER_OVER_TEMPERATURE" 12 "FEEDBACK_CURRENT_MIA" 11 "TARGET_CURRENT_MIA" 10 "LOW_SIDE_STATUS_IMPLAUSIBLE" 9 "CURRENT_MISMATCH" 8 "CURRENT_IMPLAUSIBLE" 7 "HIGH_RESISTANCE" 6 "LOW_RESISTANCE" 5 "CROSS_CONNECTION_SHORT" 4 "OPEN_CIRCUIT" 3 "VOLTAGE_ON_CIRCUIT" 2 "SHORT_TO_GND" 1 "SHORT_TO_VBAT" 0 "NONE_UNUSED" ;
VAL_ 1291 TAS_a190_a2bFaultType 8 "OTHER" 7 "DEVICE_RESET" 6 "NO_CLOCK_SYNC" 5 "MASTER_VENDOR_ID" 4 "NODE_DROP" 3 "FAILED_DISCOVERY" 2 "DATA" 1 "HARDWARE" 0 "NONE" ;
VAL_ 1291 TAS_a190_a2bInterruptType 255 "MSTR_RUNNING" 254 "STANDBY_DONE" 253 "SUB_READ_INTTYPE_ERROR" 252 "STARTUP_ERROR" 251 "NONE" 128 "INTERRUPT_MESSAGING_ERROR" 51 "MAILBOX_1_EMPTY" 50 "MAILBOX_1_FULL" 49 "MAILBOX_0_EMPTY" 48 "MAILBOX_0_FULL" 42 "NON_LOCALIZED_SHORT_TO_VBAT" 41 "NON_LOCALIZED_SHORT_TO_GROUND" 26 "INTERRUPT_CRC_ERROR" 25 "I2CERR" 24 "DSCDONE" 23 "IO7PND" 22 "IO6PND" 21 "IO5PND" 20 "IO4PND" 19 "IO3PND" 18 "IO2PND" 17 "IO1PND" 16 "IO0PND" 15 "UNDETERMINED_CABLE_FAULT" 14 "DISCONNECTED_WRONG_PORT_REVERSE" 13 "INTTYPE_REVERSE_CONNECTED_AD2428" 12 "INTTYPE_DISCONNECTED_AD2428" 11 "BP_SHORT_BN" 10 "BN_SHORT_VBAT" 9 "BP_SHORT_GND" 6 "SRF_CRC_ERROR" 5 "SRF_MISS_ERROR" 4 "BIT_ERROR_COUNT_OVERFLOW" 3 "DATA_SLOT_PARITY_ERROR" 2 "CRC_ERROR" 1 "DATA_SLOT_DECODING_ERROR" 0 "HEADER_COUNT_ERROR" ;
VAL_ 1291 TAS_a190_a2bFaultSource 3 "UNDETERMINED" 2 "MASTER" 1 "LEFT" 0 "RIGHT" ;
VAL_ 1291 TAS_a191_a2bFaultType 8 "OTHER" 7 "DEVICE_RESET" 6 "NO_CLOCK_SYNC" 5 "MASTER_VENDOR_ID" 4 "NODE_DROP" 3 "FAILED_DISCOVERY" 2 "DATA" 1 "HARDWARE" 0 "NONE" ;
VAL_ 1291 TAS_a191_a2bInterruptType 255 "MSTR_RUNNING" 254 "STANDBY_DONE" 253 "SUB_READ_INTTYPE_ERROR" 252 "STARTUP_ERROR" 251 "NONE" 128 "INTERRUPT_MESSAGING_ERROR" 51 "MAILBOX_1_EMPTY" 50 "MAILBOX_1_FULL" 49 "MAILBOX_0_EMPTY" 48 "MAILBOX_0_FULL" 42 "NON_LOCALIZED_SHORT_TO_VBAT" 41 "NON_LOCALIZED_SHORT_TO_GROUND" 26 "INTERRUPT_CRC_ERROR" 25 "I2CERR" 24 "DSCDONE" 23 "IO7PND" 22 "IO6PND" 21 "IO5PND" 20 "IO4PND" 19 "IO3PND" 18 "IO2PND" 17 "IO1PND" 16 "IO0PND" 15 "UNDETERMINED_CABLE_FAULT" 14 "DISCONNECTED_WRONG_PORT_REVERSE" 13 "INTTYPE_REVERSE_CONNECTED_AD2428" 12 "INTTYPE_DISCONNECTED_AD2428" 11 "BP_SHORT_BN" 10 "BN_SHORT_VBAT" 9 "BP_SHORT_GND" 6 "SRF_CRC_ERROR" 5 "SRF_MISS_ERROR" 4 "BIT_ERROR_COUNT_OVERFLOW" 3 "DATA_SLOT_PARITY_ERROR" 2 "CRC_ERROR" 1 "DATA_SLOT_DECODING_ERROR" 0 "HEADER_COUNT_ERROR" ;
VAL_ 1291 TAS_a191_a2bFaultSource 3 "UNDETERMINED" 2 "MASTER" 1 "LEFT" 0 "RIGHT" ;
VAL_ 1291 TAS_a226_PWMfaultFL 9 "NONE" 8 "COUNT" 7 "OPEN_CIRCUIT" 6 "SHORT_CIRCUIT" 5 "MIA" 4 "OVER_MAX_DELTA_DUTY" 3 "UNDER_MIN_PERIOD" 2 "OVER_MAX_PERIOD" 1 "UNDER_MIN_DUTY" 0 "OVER_MAX_DUTY" ;
VAL_ 1291 TAS_a227_PWMfaultFR 9 "NONE" 8 "COUNT" 7 "OPEN_CIRCUIT" 6 "SHORT_CIRCUIT" 5 "MIA" 4 "OVER_MAX_DELTA_DUTY" 3 "UNDER_MIN_PERIOD" 2 "OVER_MAX_PERIOD" 1 "UNDER_MIN_DUTY" 0 "OVER_MAX_DUTY" ;
VAL_ 1291 TAS_a228_PWMfaultRL 9 "NONE" 8 "COUNT" 7 "OPEN_CIRCUIT" 6 "SHORT_CIRCUIT" 5 "MIA" 4 "OVER_MAX_DELTA_DUTY" 3 "UNDER_MIN_PERIOD" 2 "OVER_MAX_PERIOD" 1 "UNDER_MIN_DUTY" 0 "OVER_MAX_DUTY" ;
VAL_ 1291 TAS_a229_PWMfaultRR 9 "NONE" 8 "COUNT" 7 "OPEN_CIRCUIT" 6 "SHORT_CIRCUIT" 5 "MIA" 4 "OVER_MAX_DELTA_DUTY" 3 "UNDER_MIN_PERIOD" 2 "OVER_MAX_PERIOD" 1 "UNDER_MIN_DUTY" 0 "OVER_MAX_DUTY" ;
VAL_ 1291 TAS_a232_detectedSuspensionType 6 "TESLA_ADAPTIVE" 5 "TESLA_PLUS" 4 "TESLA_STANDARD" 3 "CONTI_PLUS" 2 "CONTI_STANDARD" 1 "NONE" 0 "UNKNOWN" ;
VAL_ 1291 TAS_a232_expectedSuspensionType 6 "TESLA_ADAPTIVE" 5 "TESLA_PLUS" 4 "TESLA_STANDARD" 3 "CONTI_PLUS" 2 "CONTI_STANDARD" 1 "NONE" 0 "UNKNOWN" ;
VAL_ 1291 TAS_a234_detectedDamperHydraulic 2 "P3" 1 "V0" 0 "UNKNOWN" ;
VAL_ 1291 TAS_a234_expectedDamperHydraulic 2 "P3" 1 "V0" 0 "UNKNOWN" ;
VAL_ 1291 TAS_a240_adjustCountRatioSpring 4 "UNKNOWN" 3 "RR" 2 "RL" 1 "FR" 0 "FL" ;
VAL_ 1291 TAS_a240_adjustCountRatio 255 "SNA" ;
VAL_ 1291 TAS_a240_adjustTimeRatioSpring 4 "UNKNOWN" 3 "RR" 2 "RL" 1 "FR" 0 "FL" ;
VAL_ 1291 TAS_a240_adjustTimeRatio 255 "SNA" ;
VAL_ 1291 TAS_a296_detectedChassisType 4 "CYBERTRUCK" 3 "MODEL3" 2 "MODELX" 1 "MODELS" 0 "UNKNOWN" ;
VAL_ 1291 TAS_a296_expectedChassisType 4 "CYBERTRUCK" 3 "MODEL3" 2 "MODELX" 1 "MODELS" 0 "UNKNOWN" ;
VAL_ 1291 TAS_a319_detectedDrivetrainType 3 "AWD_DUAL_REAR" 2 "AWD" 1 "RWD" 0 "UNKNOWN" ;
VAL_ 1291 TAS_a319_expectedDrivetrainType 3 "AWD_DUAL_REAR" 2 "AWD" 1 "RWD" 0 "UNKNOWN" ;
VAL_ 852 TAS_matrixIndex 5 "AlertMatrix5" 4 "AlertMatrix4" 3 "AlertMatrix3" 2 "AlertMatrix2" 1 "AlertMatrix1" 0 "AlertMatrix0" ;
VAL_ 523 TAS_axleIndex 1 "axleRear" 0 "axleFront" ;
VAL_ 523 TAS_rawHeightFL 1023 "SNA" ;
VAL_ 523 TAS_staticHeightEstimateFL 1023 "SNA" ;
VAL_ 523 TAS_componentPressureFL 255 "SNA" ;
VAL_ 523 TAS_rawHeightFR 1023 "SNA" ;
VAL_ 523 TAS_staticHeightEstimateFR 1023 "SNA" ;
VAL_ 523 TAS_componentPressureFR 255 "SNA" ;
VAL_ 523 TAS_rawHeightRL 1023 "SNA" ;
VAL_ 523 TAS_staticHeightEstimateRL 1023 "SNA" ;
VAL_ 523 TAS_componentPressureRL 255 "SNA" ;
VAL_ 523 TAS_rawHeightRR 1023 "SNA" ;
VAL_ 523 TAS_staticHeightEstimateRR 1023 "SNA" ;
VAL_ 523 TAS_componentPressureRR 255 "SNA" ;
VAL_ 1398 TAS_endstopState 1 "TAS_DAMPING_STATE_ACTIVE" 0 "TAS_DAMPING_STATE_STANDBY" ;
VAL_ 1398 TAS_continuousControlState 1 "TAS_DAMPING_STATE_ACTIVE" 0 "TAS_DAMPING_STATE_STANDBY" ;
VAL_ 1398 TAS_activeTireTune 1 "TAS_TIRE_TUNE_MICHELIN_SUMMER_21" 0 "TAS_TIRE_TUNE_DEFAULT" ;
VAL_ 1398 TAS_roughnessRaiseReason 2 "TAS_ROUGHNESS_RAISE_REASON_LOOKAHEAD" 1 "TAS_ROUGHNESS_RAISE_REASON_LEGACY" 0 "TAS_ROUGHNESS_RAISE_REASON_NONE" ;
VAL_ 1398 TAS_frontMetricDrivesRear 3 "TAS_ACTION_ACTIVE" 2 "TAS_ACTION_ARMED" 1 "TAS_ACTION_STANDBY" 0 "TAS_ACTION_DISABLED" ;
VAL_ 1398 TAS_roadCondition 255 "SNA" ;
VAL_ 1398 TAS_bellyProtect 3 "TAS_ACTION_ACTIVE" 2 "TAS_ACTION_ARMED" 1 "TAS_ACTION_STANDBY" 0 "TAS_ACTION_DISABLED" ;
VAL_ 1398 TAS_frontMetricDrivesFront 3 "TAS_ACTION_ACTIVE" 2 "TAS_ACTION_ARMED" 1 "TAS_ACTION_STANDBY" 0 "TAS_ACTION_DISABLED" ;
VAL_ 1398 TAS_speedBumpAxleFront 4 "TAS_ACTION_CANCELED" 3 "TAS_ACTION_ACTIVE" 2 "TAS_ACTION_ARMED" 1 "TAS_ACTION_STANDBY" 0 "TAS_ACTION_DISABLED" ;
VAL_ 1398 TAS_speedBumpAxleRear 4 "TAS_ACTION_CANCELED" 3 "TAS_ACTION_ACTIVE" 2 "TAS_ACTION_ARMED" 1 "TAS_ACTION_STANDBY" 0 "TAS_ACTION_DISABLED" ;
VAL_ 1398 TAS_holeProtectFL 3 "TAS_ACTION_ACTIVE" 2 "TAS_ACTION_ARMED" 1 "TAS_ACTION_STANDBY" 0 "TAS_ACTION_DISABLED" ;
VAL_ 1398 TAS_holeProtectFR 3 "TAS_ACTION_ACTIVE" 2 "TAS_ACTION_ARMED" 1 "TAS_ACTION_STANDBY" 0 "TAS_ACTION_DISABLED" ;
VAL_ 1398 TAS_holeProtectRL 3 "TAS_ACTION_ACTIVE" 2 "TAS_ACTION_ARMED" 1 "TAS_ACTION_STANDBY" 0 "TAS_ACTION_DISABLED" ;
VAL_ 1398 TAS_holeProtectRR 3 "TAS_ACTION_ACTIVE" 2 "TAS_ACTION_ARMED" 1 "TAS_ACTION_STANDBY" 0 "TAS_ACTION_DISABLED" ;
VAL_ 1398 TAS_stepProtectFL 3 "TAS_ACTION_ACTIVE" 2 "TAS_ACTION_ARMED" 1 "TAS_ACTION_STANDBY" 0 "TAS_ACTION_DISABLED" ;
VAL_ 1398 TAS_stepProtectFR 3 "TAS_ACTION_ACTIVE" 2 "TAS_ACTION_ARMED" 1 "TAS_ACTION_STANDBY" 0 "TAS_ACTION_DISABLED" ;
VAL_ 1398 TAS_stepProtectRL 3 "TAS_ACTION_ACTIVE" 2 "TAS_ACTION_ARMED" 1 "TAS_ACTION_STANDBY" 0 "TAS_ACTION_DISABLED" ;
VAL_ 1398 TAS_stepProtectRR 3 "TAS_ACTION_ACTIVE" 2 "TAS_ACTION_ARMED" 1 "TAS_ACTION_STANDBY" 0 "TAS_ACTION_DISABLED" ;
VAL_ 1398 TAS_FDUTorqueCorruptionScale 15 "SNA" ;
VAL_ 1398 TAS_sprungMassEstimate 31 "SNA" ;
VAL_ 1357 TAS_infoIndex 255 "END" 41 "SUBCOMPONENT14" 40 "SUBCOMPONENT13" 39 "SUBCOMPONENT12" 38 "SUBCOMPONENT11" 37 "SUBCOMPONENT10" 36 "SUBCOMPONENT9" 35 "SUBCOMPONENT8" 34 "SUBCOMPONENT7" 33 "SUBCOMPONENT6" 32 "SUBCOMPONENT5" 31 "SUBCOMPONENT4" 24 "SUBCOMPONENT3" 23 "SUBCOMPONENT2" 20 "UDS_PROTOCOL_BOOTCRC" 19 "VERSION_DEPRECATED" 18 "BOOTLOADER_GITHASH" 17 "APP_GITHASH" 16 "SUBCOMPONENT1" 15 "BOOTLOADER_CRC" 14 "BOOTLOADER_SVN" 13 "APP_CRC" 11 "PCBAID_ASSYID_USAGEID" 10 "BUILD_HWID_COMPONENTID" 9 "DEPRECATED_9" 8 "DEPRECATED_8" 7 "DEPRECATED_7" 6 "DEPRECATED_6" 5 "DEPRECATED_5" 4 "DEPRECATED_4" 3 "DEPRECATED_3" 2 "DEPRECATED_2" 1 "DEPRECATED_1" 0 "DEPRECATED_0" ;
VAL_ 1357 TAS_infoBuildType 4 "INFO_MFG_BUILD" 3 "INFO_TRACEABLE_CI_BUILD" 2 "INFO_LOCAL_BUILD" 1 "INFO_PLATFORM_BUILD" 0 "INFO_UNKNOWN_BUILD" ;
VAL_ 1357 TAS_infoAssemblyId 255 "ASSEMBLY_SNA" 1 "ASSEMBLY1" ;
VAL_ 1357 TAS_infoMajorVersion 255 "SNA" 254 "LOCAL_BUILD" ;
VAL_ 1357 TAS_infoBranchOrigin 255 "SNA" 254 "LOCAL_BUILD" ;
VAL_ 1357 TAS_infoMaturity 255 "SNA" 254 "LOCAL_BUILD" ;
VAL_ 1357 TAS_infoHardwareRevision 255 "SNA" 254 "LOCAL_BUILD" ;
VAL_ 525 TAS_levelingState 15 "LEVELING_STATE_CROSSLINK" 14 "LEVELING_STATE_QUIET_EXHAUST" 13 "LEVELING_STATE_EXHAUST_RESERVOIR" 12 "LEVELING_STATE_LOWER_SPRING_WITH_COMPRESSOR" 11 "LEVELING_STATE_LOWER_SPRING" 10 "LEVELING_STATE_FILL_SPRING_RESERVOIR_FROM_COMPRESSOR" 9 "LEVELING_STATE_FILL_SPRING_FROM_RESERVOIR" 8 "LEVELING_STATE_FILL_SPRING_FROM_BOOST" 7 "LEVELING_STATE_FILL_SPRING_FROM_COMPRESSOR" 6 "LEVELING_STATE_FILL_RESERVOIR_FROM_COMPRESSOR" 5 "LEVELING_STATE_COMPRESSOR_PREFILL_GALLERY" 4 "LEVELING_STATE_COMPRESSOR_RAMPUP" 3 "LEVELING_STATE_EXHAUST_GALLERY" 2 "LEVELING_STATE_MEASURE_SPRING_PRESSURE" 1 "LEVELING_STATE_READ_P_RESERVOIR" 0 "LEVELING_STATE_IDLE" ;
VAL_ 525 TAS_levelingItem 7 "TAS_LEVELING_ITEM_ALL" 6 "TAS_LEVELING_ITEM_REAR_AXLE" 5 "TAS_LEVELING_ITEM_FRONT_AXLE" 4 "TAS_LEVELING_ITEM_RR" 3 "TAS_LEVELING_ITEM_RL" 2 "TAS_LEVELING_ITEM_FR" 1 "TAS_LEVELING_ITEM_FL" 0 "TAS_LEVELING_ITEM_NONE" ;
VAL_ 525 TAS_pressureGallery 255 "SNA" ;
VAL_ 525 TAS_pressureReservoir 255 "SNA" ;
VAL_ 525 TAS_runMode 7 "RUN_MODE_DYNO" 6 "RUN_MODE_LOW_POWER" 5 "RUN_MODE_NORMAL" 4 "RUN_MODE_DAN" 3 "RUN_MODE_ASSEMBLY" 2 "RUN_MODE_SERVICE" 1 "RUN_MODE_SYSTEM_CHECK" 0 "RUN_MODE_INIT" ;
VAL_ 525 TAS_filterMode 7 "MODE_STOPPING" 6 "MODE_DRIVE" 5 "MODE_LOADING" 4 "MODE_READY" 3 "MODE_TEST" 2 "MODE_CALIBRATE" 1 "MODE_INIT" 0 "MODE_NONE" ;
VAL_ 525 TAS_limpHomeMode 4 "LIMP_HOME_MODE_40" 3 "LIMP_HOME_MODE_30" 2 "LIMP_HOME_MODE_20" 1 "LIMP_HOME_MODE_10" 0 "LIMP_HOME_MODE_0" ;
VAL_ 525 TAS_targetLevel 4 "TAS_VERY_LOW" 3 "TAS_LOW" 2 "TAS_STANDARD" 1 "TAS_HIGH" 0 "TAS_VERY_HIGH" ;
VAL_ 525 TAS_currentLevel 4 "TAS_VERY_LOW" 3 "TAS_LOW" 2 "TAS_STANDARD" 1 "TAS_HIGH" 0 "TAS_VERY_HIGH" ;
VAL_ 409 TAS_adaptiveActivityFL_C 31 "SNA" ;
VAL_ 409 TAS_adaptiveActivityFL_R 31 "SNA" ;
VAL_ 409 TAS_adaptiveActivityFR_C 31 "SNA" ;
VAL_ 409 TAS_adaptiveActivityFR_R 31 "SNA" ;
VAL_ 409 TAS_adaptiveActivityRL_C 31 "SNA" ;
VAL_ 409 TAS_adaptiveActivityRL_R 31 "SNA" ;
VAL_ 409 TAS_adaptiveActivityRR_C 31 "SNA" ;
VAL_ 409 TAS_adaptiveActivityRR_R 31 "SNA" ;
VAL_ 409 TAS_uiHeightFL 63 "SNA" ;
VAL_ 409 TAS_uiHeightFR 63 "SNA" ;
VAL_ 409 TAS_uiHeightRL 63 "SNA" ;
VAL_ 409 TAS_uiHeightRR 63 "SNA" ;
VAL_ 410 TAS_bodyAccelFL 255 "SNA" ;
VAL_ 410 TAS_bodyAccelFR 255 "SNA" ;
VAL_ 410 TAS_bodyAccelRL 255 "SNA" ;
VAL_ 410 TAS_bodyAccelRR 255 "SNA" ;
VAL_ 538 TAS_adaptiveRideModeOverride 3 "TAS_ADAPTIVE_RIDE_MODE_SNA" 2 "TAS_ADAPTIVE_RIDE_MODE_SPORT" 1 "TAS_ADAPTIVE_RIDE_MODE_AUTO" 0 "TAS_ADAPTIVE_RIDE_MODE_COMFORT" ;
VAL_ 538 TAS_launchModeState 4 "TAS_LAUNCH_MODE_STATE_RAISE_SUSPENSION" 3 "TAS_LAUNCH_MODE_STATE_READY" 2 "TAS_LAUNCH_MODE_STATE_LOWER_SUSPENSION" 1 "TAS_LAUNCH_MODE_STATE_IDLE" 0 "TAS_LAUNCH_MODE_STATE_BLOCKED" ;
VAL_ 1657 UI_rgbEnableState 2 "AUTO" 1 "ON" 0 "OFF" ;
VAL_ 1657 UI_rgbEffectType 20 "RAMP_5000MS" 19 "RAMP_4750MS" 18 "RAMP_4500MS" 17 "RAMP_4250MS" 16 "RAMP_4000MS" 15 "RAMP_3750MS" 14 "RAMP_3500MS" 13 "RAMP_3250MS" 12 "RAMP_3000MS" 11 "RAMP_2750MS" 10 "RAMP_2500MS" 9 "RAMP_2250MS" 8 "RAMP_2000MS" 7 "RAMP_1750MS" 6 "RAMP_1500MS" 5 "RAMP_1250MS" 4 "RAMP_1000MS" 3 "RAMP_750MS" 2 "RAMP_500MS" 1 "RAMP_250MS" 0 "RAMP_INSTANT" ;
VAL_ 1657 UI_rgbBrightnessLevel 127 "SNA" ;
VAL_ 1021 UI_autopilotControlIndex 7 "7" 6 "6" 5 "5" 4 "4" 3 "3" 2 "2" 1 "1" 0 "0" ;
VAL_ 1021 UI_hovEnabled 1 "HOV_ON" 0 "HOV_OFF" ;
VAL_ 1021 UI_donDisableAutoWiperDuration 6 "OFF" 5 "120_S" 4 "60_S" 3 "30_S" 2 "15_S" 1 "5_S" 0 "DEFAULT" ;
VAL_ 1021 UI_donDisableOnAutoWiperSpeed 15 "INVALID" 14 "14" 13 "13" 12 "12" 11 "11" 10 "10" 9 "9" 8 "8" 7 "7" 6 "6" 5 "5" 4 "4" 3 "3" 2 "2" 1 "1" 0 "OFF" ;
VAL_ 1021 UI_blindspotMinSpeed 10 "OFF" 9 "45_KPH" 8 "40_KPH" 7 "35_KPH" 6 "30_KPH" 5 "25_KPH" 4 "20_KPH" 3 "15_KPH" 2 "10_KPH" 1 "5_KPH" 0 "DEFAULT" ;
VAL_ 1021 UI_blindspotDistance 5 "OFF" 4 "4_M" 3 "2_M" 2 "1_M" 1 "0P5_M" 0 "DEFAULT" ;
VAL_ 1021 UI_blindspotTTC 7 "OFF" 6 "5_S" 5 "3_S" 4 "4_S" 3 "2_S" 2 "1_S" 1 "0P5_S" 0 "DEFAULT" ;
VAL_ 1021 UI_donStopEndOfRampBuffer 4 "OFF" 3 "45_M" 2 "30_M" 1 "15_M" 0 "DEFAULT" ;
VAL_ 1021 UI_donDisableCutin 1 "ON" 0 "OFF" ;
VAL_ 1021 UI_smartSetSpeedOffsetType 1 "PERCENTAGE_OFFSET" 0 "FIXED_OFFSET" ;
VAL_ 1021 UI_homelinkNearby 1 "NEARBY" 0 "NOT_NEARBY" ;
VAL_ 1021 UI_autosteerActivation 1 "DOUBLE_CLICK" 0 "SINGLE_CLICK" ;
VAL_ 1021 UI_autopilotDrivingProfile 3 "MAD_MAX" 2 "ASSERTIVE" 1 "NORMAL" 0 "CHILL" ;
VAL_ 1021 UI_fsdBetaRequest 1 "FSD_REQUEST_ACTIVE" 0 "FSD_REQUEST_NOT_ACTIVE" ;
VAL_ 1021 UI_selectableCameraRequest 15 "SNA" 13 "REPEATERS_BACKUP" 12 "FASCIA" 11 "GRID_VIEW" 10 "OCTA" 9 "BACKUP" 8 "RIGHT_REPEATER" 7 "RIGHT_PILLAR" 6 "LEFT_REPEATER" 5 "LEFT_PILLAR" 4 "FRONT_NARROW" 3 "FRONT_FISHEYE" 2 "FRONT_MAIN" 1 "SELFIE" 0 "NONE" ;
VAL_ 1021 UI_overrideSleepWithSuspend 1 "ENABLED" 0 "DISABLED" ;
VAL_ 1021 UI_regulatoryLaneAssistLevel 1 "ASSIST" 0 "WARNING" ;
VAL_ 1021 UI_apmv3Branch 5 "DEMO" 4 "EAP" 3 "STAGE2" 2 "DEV" 1 "STAGE" 0 "LIVE" ;
VAL_ 1021 UI_autoTurnSignalMode 1 "UI_AUTO_TURN_SIGNAL_MODE_AUTO_CANCEL" 0 "UI_AUTO_TURN_SIGNAL_MODE_OFF" ;
VAL_ 819 UI_brickVLoggingRequest 1 "TRUE" 0 "FALSE" ;
VAL_ 819 UI_brickBalancingDisabled 1 "TRUE" 0 "FALSE" ;
VAL_ 819 UI_acChargeCurrentLimit 127 "SNA" ;
VAL_ 819 UI_chargePortLatchRequest 2 "UI_LATCH_REQUEST_DISENGAGE" 1 "UI_LATCH_REQUEST_ENGAGE" 0 "UI_LATCH_REQUEST_NONE" ;
VAL_ 819 UI_cpInletHeaterRequest 2 "HEATER_MANUAL_OVERRIDE" 1 "HEATER_AUTO" 0 "HEATER_OFF" ;
VAL_ 659 UI_steeringTuneRequest 2 "STEERING_TUNE_SPORT" 1 "STEERING_TUNE_STANDARD" 0 "STEERING_TUNE_COMFORT" ;
VAL_ 659 UI_tractionControlMode 7 "TC_SLIPPERY_SURFACE_SELECTED" 6 "TC_OFFROAD_ASSIST_SELECTED" 5 "TC_DYNO_MODE_SELECTED" 4 "TC_ROLLS_MODE_SELECTED" 3 "TC_DEV_MODE_2_SELECTED" 2 "TC_DEV_MODE_1_SELECTED" 1 "TC_SLIP_START_SELECTED" 0 "TC_NORMAL_SELECTED" ;
VAL_ 659 UI_parkBrakeRequest 3 "PARK_BRAKE_REQUEST_SNA" 1 "PARK_BRAKE_REQUEST_PRESSED" 0 "PARK_BRAKE_REQUEST_IDLE" ;
VAL_ 659 UI_winchModeRequest 3 "WINCH_MODE_DIALOGUE_OPEN" 2 "WINCH_MODE_EXIT" 1 "WINCH_MODE_ENTER" 0 "WINCH_MODE_IDLE" ;
VAL_ 659 UI_zeroSpeedConfirmed 3 "SNA" 2 "UNUSED" 1 "CONFIRMED" 0 "CANCELED" ;
VAL_ 659 UI_trailerMode 1 "TRAILER_MODE_ON" 0 "TRAILER_MODE_OFF" ;
VAL_ 659 UI_distanceUnits 1 "MILES" 0 "KM" ;
VAL_ 659 UI_accOvertakeEnable 3 "SNA" 1 "ACC_OVERTAKE_ON" 0 "ACC_OVERTAKE_OFF" ;
VAL_ 659 UI_aebEnable 3 "SNA" 1 "AEB_ON" 0 "AEB_OFF" ;
VAL_ 659 UI_aesEnable 3 "SNA" 1 "AES_ON" 0 "AES_OFF" ;
VAL_ 659 UI_ahlbEnable 3 "SNA" 1 "AHLB_ON" 0 "AHLB_OFF" ;
VAL_ 659 UI_autoLaneChangeEnable 3 "SNA" 1 "ON" 0 "OFF" ;
VAL_ 659 UI_autoParkRequest 15 "SNA" 12 "BEGIN_PARKING" 11 "RESUME" 10 "PAUSE" 9 "SEARCH" 8 "COMPLETE" 7 "ABORT" 6 "PARALLEL_PULL_OUT_TO_RIGHT" 5 "PARALLEL_PULL_OUT_TO_LEFT" 4 "PARK_RIGHT_CROSS" 3 "PARK_RIGHT_PARALLEL" 2 "PARK_LEFT_CROSS" 1 "PARK_LEFT_PARALLEL" 0 "NONE" ;
VAL_ 659 UI_bsdEnable 3 "SNA" 1 "BSD_ON" 0 "BSD_OFF" ;
VAL_ 659 UI_fcwEnable 3 "SNA" 1 "FCW_ON" 0 "FCW_OFF" ;
VAL_ 659 UI_fcwSensitivity 3 "SNA" 2 "AEB_SENSITIVITY_LATE" 1 "AEB_SENSITIVITY_AVERAGE" 0 "AEB_SENSITIVITY_EARLY" ;
VAL_ 659 UI_latControlEnable 3 "LATERAL_CONTROL_SNA" 2 "LATERAL_CONTROL_UNAVAILABLE" 1 "LATERAL_CONTROL_ON" 0 "LATERAL_CONTROL_OFF" ;
VAL_ 659 UI_ldwEnable 3 "SNA" 1 "LDW_TRIGGERS_HAPTIC" 0 "NO_HAPTIC" ;
VAL_ 659 UI_pedalSafetyEnable 3 "SNA" 1 "PEDAL_SAFETY_ON" 0 "PEDAL_SAFETY_OFF" ;
VAL_ 659 UI_pedalMap_epas 2 "PERFORMANCE" 1 "SPORT" 0 "CHILL" ;
VAL_ 659 UI_redLightStopSignEnable 3 "SNA" 1 "RLSSW_ON" 0 "RLSSW_OFF" ;
VAL_ 659 UI_selfParkTune 15 "SNA" ;
VAL_ 531 UI_cruiseSpeedCommand 6 "CRUISE_SPEED_SNAP_SPEEDO" 5 "CRUISE_SPEED_SNAP" 4 "CRUISE_SPEED_DEC_LONG" 3 "CRUISE_SPEED_DEC_SHORT" 2 "CRUISE_SPEED_INC_LONG" 1 "CRUISE_SPEED_INC_SHORT" 0 "CRUISE_SPEED_IDLE" ;
VAL_ 1280 UI_debugEcuTarget 21 "PMRE2" 20 "PMRE2L" 19 "PMRE1L" 18 "DIRE2" 17 "DIRE1R" 16 "DIRE1L" 15 "PMRER" 14 "PMREL" 13 "DIRER" 12 "DIREL" 11 "PMR" 10 "PMF" 9 "DIR" 8 "DIF" 7 "VCFRONT" 6 "VCRIGHT" 5 "BMS" 4 "PMS" 3 "PM" 2 "DIS" 1 "DI" ;
VAL_ 2043 UI_debugDampingRequestFLC 255 "SNA" ;
VAL_ 2043 UI_debugDampingRequestFLR 255 "SNA" ;
VAL_ 2043 UI_debugDampingRequestFRC 255 "SNA" ;
VAL_ 2043 UI_debugDampingRequestFRR 255 "SNA" ;
VAL_ 2043 UI_debugDampingRequestRLC 255 "SNA" ;
VAL_ 2043 UI_debugDampingRequestRLR 255 "SNA" ;
VAL_ 2043 UI_debugDampingRequestRRC 255 "SNA" ;
VAL_ 2043 UI_debugDampingRequestRRR 255 "SNA" ;
VAL_ 568 UI_mapSpeedLimitDependency 7 "SNA" 6 "LANE" 5 "SEASON" 4 "TIME" 3 "SNOW" 2 "RAIN" 1 "SCHOOL" 0 "NONE" ;
VAL_ 568 UI_roadClass 6 "CLASS_6_MINOR" 5 "CLASS_5" 4 "CLASS_4" 3 "CLASS_3" 2 "CLASS_2" 1 "CLASS_1_MAJOR" 0 "UNKNOWN_INVALID_SNA" ;
VAL_ 568 UI_mapSpeedUnits 1 "KPH" 0 "MPH" ;
VAL_ 568 UI_mapSpeedLimit 31 "SNA" 30 "UNLIMITED" 29 "LESS_OR_EQ_160" 28 "LESS_OR_EQ_150" 27 "LESS_OR_EQ_140" 26 "LESS_OR_EQ_130" 25 "LESS_OR_EQ_120" 24 "LESS_OR_EQ_115" 23 "LESS_OR_EQ_110" 22 "LESS_OR_EQ_105" 21 "LESS_OR_EQ_100" 20 "LESS_OR_EQ_95" 19 "LESS_OR_EQ_90" 18 "LESS_OR_EQ_85" 17 "LESS_OR_EQ_80" 16 "LESS_OR_EQ_75" 15 "LESS_OR_EQ_70" 14 "LESS_OR_EQ_65" 13 "LESS_OR_EQ_60" 12 "LESS_OR_EQ_55" 11 "LESS_OR_EQ_50" 10 "LESS_OR_EQ_45" 9 "LESS_OR_EQ_40" 8 "LESS_OR_EQ_35" 7 "LESS_OR_EQ_30" 6 "LESS_OR_EQ_25" 5 "LESS_OR_EQ_20" 4 "LESS_OR_EQ_15" 3 "LESS_OR_EQ_10" 2 "LESS_OR_EQ_7" 1 "LESS_OR_EQ_5" 0 "UNKNOWN" ;
VAL_ 568 UI_mapSpeedLimitType 7 "UNKNOWN_SNA" 4 "BUMPS" 3 "DEPENDENT" 2 "ADVISORY" 1 "REGULAR" ;
VAL_ 568 UI_countryCode 1023 "SNA" 0 "UNKNOWN" ;
VAL_ 568 UI_nextBranchDist 31 "SNA" ;
VAL_ 645 UI_driverProfileRecallIndex 5 "5" 4 "4" 3 "3" 2 "2" 1 "1" 0 "SNA" ;
VAL_ 645 UI_modifyMirrorDipRequest 2 "MODIFY_MIRROR_DIP_REQUEST_DIPPED" 1 "MODIFY_MIRROR_DIP_REQUEST_UNDIPPED" 0 "MODIFY_MIRROR_DIP_REQUEST_NONE" ;
VAL_ 651 UI_driverProfileLinkedKeySHA1 4294967295 "SNA" ;
VAL_ 651 UI_driverProfileSelectionType 3 "DRIVER_PROFILE_SELECTION_TYPE_NONE" 2 "DRIVER_PROFILE_SELECTION_TYPE_AUTOMATIC_NO_OP" 1 "DRIVER_PROFILE_SELECTION_TYPE_AUTOMATIC_RESTORE" 0 "DRIVER_PROFILE_SELECTION_TYPE_MANUAL" ;
VAL_ 984 UI_elevation 8191 "SNA" ;
VAL_ 984 UI_navElevation 8191 "SNA" ;
VAL_ 1139 UI_nmKeepAwakeReason 31 "UI_KEEPAWAKE_REASON_AUTO_CONDITIONING_START" 30 "UI_KEEPAWAKE_REASON_WINDOW_CONTROL" 29 "UI_KEEPAWAKE_REASON_GET_VEHICLE_CONFIGURATION" 28 "UI_KEEPAWAKE_REASON_MOTHERSHIP_SMS_OWNER_WAKE_UP" 27 "UI_KEEPAWAKE_REASON_MOTHERSHIP_SMS_GARAGE_WAKE_UP" 26 "UI_KEEPAWAKE_REASON_MOTHERSHIP_SMS_VEHICLE_TASK" 25 "UI_KEEPAWAKE_REASON_MOTHERSHIP_SMS_YOUVE_GOT_MAIL" 24 "UI_KEEPAWAKE_REASON_WAKE_UP" 23 "UI_KEEPAWAKE_REASON_FIRMWARE_HANDSHAKE" 22 "UI_KEEPAWAKE_REASON_VEHICLE_DATA" 21 "UI_KEEPAWAKE_REASON_DIAG_VITALS" 20 "UI_KEEPAWAKE_REASON_URGENT_UPLOAD" 19 "UI_KEEPAWAKE_REASON_UI_REQUEST_AP_KEEPALIVE" 18 "UI_KEEPAWAKE_REASON_STEAM" 17 "UI_KEEPAWAKE_REASON_CHARGING" 16 "UI_KEEPAWAKE_REASON_UI_HVAC_REQUEST" 15 "UI_KEEPAWAKE_REASON_USER_NOTIFICATION_TIMER" 14 "UI_KEEPAWAKE_REASON_ODIN" 13 "UI_KEEPAWAKE_REASON_MEDIA_DOWNLOAD" 12 "UI_KEEPAWAKE_REASON_SENTRY_MODE" 11 "UI_KEEPAWAKE_REASON_SELFTEST" 10 "UI_KEEPAWAKE_REASON_ECALL_ACTIVE" 9 "UI_KEEPAWAKE_REASON_UPDATE_COUNTDOWN" 8 "UI_KEEPAWAKE_REASON_AUTOFUSER" 7 "UI_KEEPAWAKE_REASON_HERMES" 6 "UI_KEEPAWAKE_REASON_UPDATER" 5 "UI_KEEPAWAKE_REASON_MODEM_RESET" 4 "UI_KEEPAWAKE_REASON_UNKNOWN_REMOTE_REQUEST" 3 "UI_KEEPAWAKE_REASON_PM_CHECKING" 2 "UI_KEEPAWAKE_REASON_GUI_NEVER_SLEEP_SET" 1 "UI_KEEPAWAKE_REASON_KEEPALIVEACTIVE" 0 "UI_KEEPAWAKE_REASON_NONE_SNA" ;
VAL_ 883 UI_mapSpeedLimitUnits 1 "KPH" 0 "MPH" ;
VAL_ 883 UI_userSpeedOffsetUnits 1 "KPH" 0 "MPH" ;
VAL_ 883 UI_conditionalSpeedLimit 31 "SNA" ;
VAL_ 755 UI_hvacReqTempSetpointLeft 26 "HI" 0 "LO" ;
VAL_ 755 UI_hvacReqAutoBlowerLevel 4 "VERY_HIGH" 3 "HIGH" 2 "MEDIUM" 1 "LOW" 0 "VERY_LOW" ;
VAL_ 755 UI_hvacReqTempSetpointRight 26 "HI" 0 "LO" ;
VAL_ 755 UI_hvacReqAirDistributionMode 7 "MANUAL_DEFROST_PANEL_FLOOR" 6 "MANUAL_DEFROST_PANEL" 5 "MANUAL_DEFROST_FLOOR" 4 "MANUAL_DEFROST" 3 "MANUAL_PANEL_FLOOR" 2 "MANUAL_PANEL" 1 "MANUAL_FLOOR" 0 "AUTO" ;
VAL_ 755 UI_hvacReqBlowerSegment 11 "AUTO" 10 "10" 9 "9" 8 "8" 7 "7" 6 "6" 5 "5" 4 "4" 3 "3" 2 "2" 1 "1" 0 "OFF" ;
VAL_ 755 UI_hvacReqRecirc 2 "FRESH" 1 "RECIRC" 0 "AUTO" ;
VAL_ 755 UI_hvacReqACDisable 2 "ON" 1 "OFF" 0 "AUTO" ;
VAL_ 755 UI_hvacDefogState 3 "AUTO_DEFOG" 2 "DEFROST" 1 "DEFOG" 0 "NONE" ;
VAL_ 755 UI_hvacReqUserPowerState 4 "OVERHEAT_PROTECT" 3 "OVERHEAT_PROTECT_FANONLY" 2 "PRECONDITION" 1 "ON" 0 "OFF" ;
VAL_ 755 UI_hvacReqSecondRowState 4 "HIGH" 3 "MED" 2 "LOW" 1 "OFF" 0 "AUTO" ;
VAL_ 755 UI_hvacReqKeepClimateOn 3 "KEEP_CLIMATE_ON_REQ_PARTY" 2 "KEEP_CLIMATE_ON_REQ_DOG" 1 "KEEP_CLIMATE_ON_REQ_ON" 0 "KEEP_CLIMATE_ON_REQ_OFF" ;
VAL_ 755 UI_hvacReqTempSetpointCOP 2 "HIGH" 1 "MEDIUM" 0 "LOW" ;
VAL_ 755 UI_hvacClimateNudgeStatus 4 "CLOSED_WITH_EXTERIOR_NUDGE" 3 "OPEN_WITH_NUDGE" 2 "OPEN_NO_NUDGE" 1 "CLOSED_WITH_NUDGE" 0 "CLOSED_NO_NUDGE" ;
VAL_ 777 UI_gpsAccuracy 127 "SNA" ;
